VERSION ""

NS_ :

BS_:

BU_:

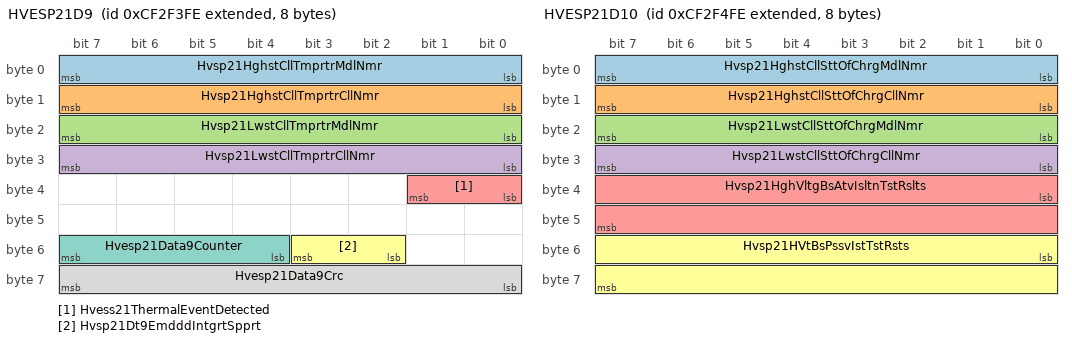
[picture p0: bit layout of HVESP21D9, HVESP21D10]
BO_ 2364732414 HVESP21D9: 8 Vector__XXX
 SG_ Hvsp21HghstCllTmprtrMdlNmr : 0|8@1+ (1,0) [0|250] "count" Vector__XXX
 SG_ Hvsp21HghstCllTmprtrCllNmr : 8|8@1+ (1,0) [0|250] "count" Vector__XXX
 SG_ Hvsp21LwstCllTmprtrMdlNmr : 16|8@1+ (1,0) [0|250] "count" Vector__XXX
 SG_ Hvsp21LwstCllTmprtrCllNmr : 24|8@1+ (1,0) [0|250] "count" Vector__XXX
 SG_ Hvess21ThermalEventDetected : 32|2@1+ (1,0) [0|3] "" Vector__XXX
 SG_ Hvsp21Dt9EmdddIntgrtSpprt : 50|2@1+ (1,0) [0|3] "" Vector__XXX
 SG_ Hvesp21Data9Counter : 52|4@1+ (1,0) [0|15] "" Vector__XXX
 SG_ Hvesp21Data9Crc : 56|8@1+ (1,0) [0|250] "count" Vector__XXX

BO_ 2364732670 HVESP21D10: 8 Vector__XXX
 SG_ Hvsp21HghstCllSttOfChrgMdlNmr : 0|8@1+ (1,0) [0|250] "count" Vector__XXX
 SG_ Hvsp21HghstCllSttOfChrgCllNmr : 8|8@1+ (1,0) [0|250] "count" Vector__XXX
 SG_ Hvsp21LwstCllSttOfChrgMdlNmr : 16|8@1+ (1,0) [0|250] "count" Vector__XXX
 SG_ Hvsp21LwstCllSttOfChrgCllNmr : 24|8@1+ (1,0) [0|250] "count" Vector__XXX
 SG_ Hvsp21HghVltgBsAtvIsltnTstRslts : 32|16@1+ (0.1,0) [0|6425.5] "OhmPerV" Vector__XXX
 SG_ Hvsp21HVtBsPssvIstTstRsts : 48|16@1+ (0.1,0) [0|6425.5] "OhmPerV" Vector__XXX

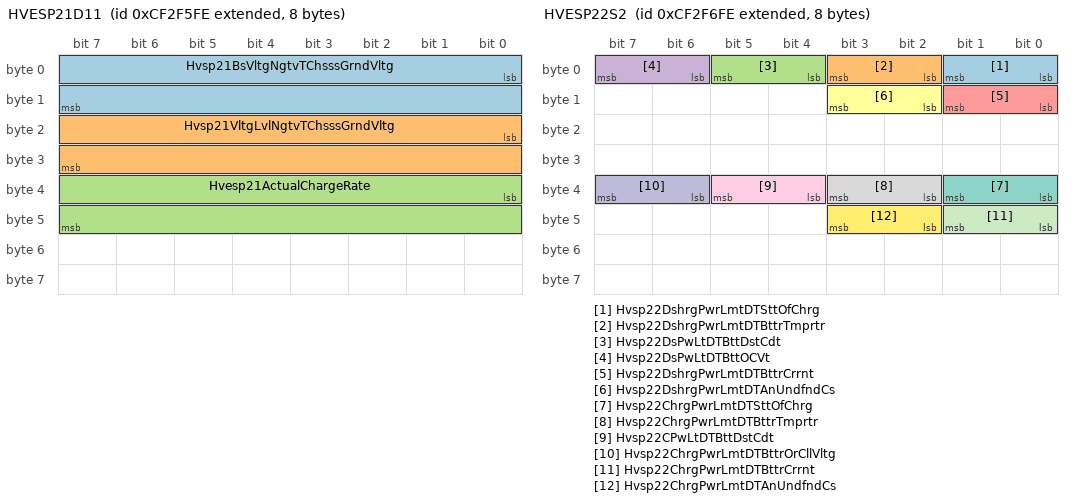
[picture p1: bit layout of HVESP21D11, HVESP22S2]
BO_ 2364732926 HVESP21D11: 8 Vector__XXX
 SG_ Hvsp21BsVltgNgtvTChsssGrndVltg : 0|16@1+ (0.05,0) [0|3212.75] "V" Vector__XXX
 SG_ Hvsp21VltgLvlNgtvTChsssGrndVltg : 16|16@1+ (0.05,0) [0|3212.75] "V" Vector__XXX
 SG_ Hvesp21ActualChargeRate : 32|16@1+ (0.05,0) [0|3212.75] "kW" Vector__XXX

BO_ 2364733182 HVESP22S2: 8 Vector__XXX
 SG_ Hvsp22DshrgPwrLmtDTSttOfChrg : 0|2@1+ (1,0) [0|3] "" Vector__XXX
 SG_ Hvsp22DshrgPwrLmtDTBttrTmprtr : 2|2@1+ (1,0) [0|3] "" Vector__XXX
 SG_ Hvsp22DsPwLtDTBttDstCdt : 4|2@1+ (1,0) [0|3] "" Vector__XXX
 SG_ Hvsp22DsPwLtDTBttOCVt : 6|2@1+ (1,0) [0|3] "" Vector__XXX
 SG_ Hvsp22DshrgPwrLmtDTBttrCrrnt : 8|2@1+ (1,0) [0|3] "" Vector__XXX
 SG_ Hvsp22DshrgPwrLmtDTAnUndfndCs : 10|2@1+ (1,0) [0|3] "" Vector__XXX
 SG_ Hvsp22ChrgPwrLmtDTSttOfChrg : 32|2@1+ (1,0) [0|3] "" Vector__XXX
 SG_ Hvsp22ChrgPwrLmtDTBttrTmprtr : 34|2@1+ (1,0) [0|3] "" Vector__XXX
 SG_ Hvsp22CPwLtDTBttDstCdt : 36|2@1+ (1,0) [0|3] "" Vector__XXX
 SG_ Hvsp22ChrgPwrLmtDTBttrOrCllVltg : 38|2@1+ (1,0) [0|3] "" Vector__XXX
 SG_ Hvsp22ChrgPwrLmtDTBttrCrrnt : 40|2@1+ (1,0) [0|3] "" Vector__XXX
 SG_ Hvsp22ChrgPwrLmtDTAnUndfndCs : 42|2@1+ (1,0) [0|3] "" Vector__XXX

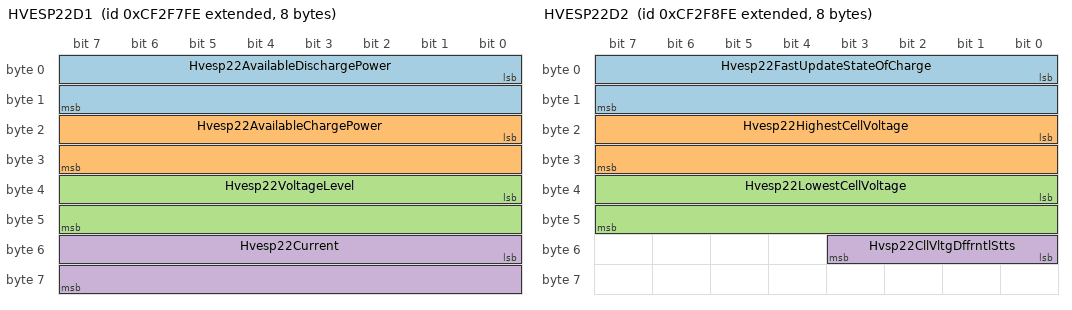
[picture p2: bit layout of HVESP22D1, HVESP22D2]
BO_ 2364733438 HVESP22D1: 8 Vector__XXX
 SG_ Hvesp22AvailableDischargePower : 0|16@1+ (0.05,0) [0|3212.75] "kW" Vector__XXX
 SG_ Hvesp22AvailableChargePower : 16|16@1+ (0.05,0) [0|3212.75] "kW" Vector__XXX
 SG_ Hvesp22VoltageLevel : 32|16@1+ (0.05,0) [0|3212.75] "V" Vector__XXX
 SG_ Hvesp22Current : 48|16@1+ (0.05,-1600) [-1600|1612.75] "A" Vector__XXX

BO_ 2364733694 HVESP22D2: 8 Vector__XXX
 SG_ Hvesp22FastUpdateStateOfCharge : 0|16@1+ (0.0015625,0) [0|100.3984375] "%" Vector__XXX
 SG_ Hvesp22HighestCellVoltage : 16|16@1+ (0.001,0) [0|64.255] "V" Vector__XXX
 SG_ Hvesp22LowestCellVoltage : 32|16@1+ (0.001,0) [0|64.255] "V" Vector__XXX
 SG_ Hvsp22CllVltgDffrntlStts : 48|4@1+ (1,0) [0|15] "" Vector__XXX

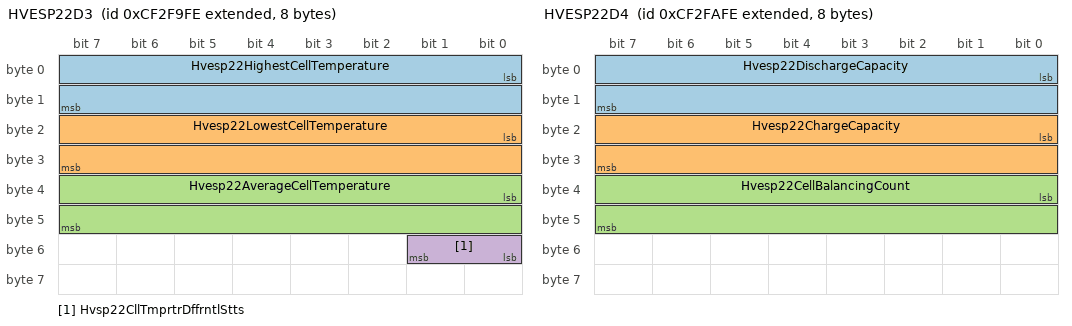
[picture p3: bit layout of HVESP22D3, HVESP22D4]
BO_ 2364733950 HVESP22D3: 8 Vector__XXX
 SG_ Hvesp22HighestCellTemperature : 0|16@1+ (0.03125,-273) [-273|1734.96875] "degC" Vector__XXX
 SG_ Hvesp22LowestCellTemperature : 16|16@1+ (0.03125,-273) [-273|1734.96875] "degC" Vector__XXX
 SG_ Hvesp22AverageCellTemperature : 32|16@1+ (0.03125,-273) [-273|1734.96875] "degC" Vector__XXX
 SG_ Hvsp22CllTmprtrDffrntlStts : 48|2@1+ (1,0) [0|3] "" Vector__XXX

BO_ 2364734206 HVESP22D4: 8 Vector__XXX
 SG_ Hvesp22DischargeCapacity : 0|16@1+ (0.01,0) [0|642.55] "Ah" Vector__XXX
 SG_ Hvesp22ChargeCapacity : 16|16@1+ (0.01,0) [0|642.55] "Ah" Vector__XXX
 SG_ Hvesp22CellBalancingCount : 32|16@1+ (1,0) [0|64255] "count" Vector__XXX

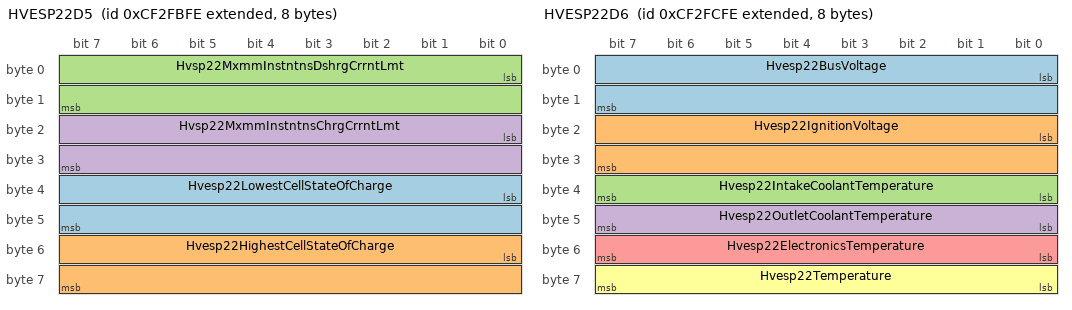
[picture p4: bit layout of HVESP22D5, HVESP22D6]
BO_ 2364734462 HVESP22D5: 8 Vector__XXX
 SG_ Hvesp22LowestCellStateOfCharge : 32|16@1+ (0.0015625,0) [0|100.3984375] "%" Vector__XXX
 SG_ Hvesp22HighestCellStateOfCharge : 48|16@1+ (0.0015625,0) [0|100.3984375] "%" Vector__XXX
 SG_ Hvsp22MxmmInstntnsDshrgCrrntLmt : 0|16@1+ (0.05,-1600) [-1600|0] "A" Vector__XXX
 SG_ Hvsp22MxmmInstntnsChrgCrrntLmt : 16|16@1+ (0.05,-1600) [0|1612.75] "A" Vector__XXX

BO_ 2364734718 HVESP22D6: 8 Vector__XXX
 SG_ Hvesp22BusVoltage : 0|16@1+ (0.05,0) [0|3212.75] "V" Vector__XXX
 SG_ Hvesp22IgnitionVoltage : 16|16@1+ (0.01,0) [0|642.55] "V" Vector__XXX
 SG_ Hvesp22IntakeCoolantTemperature : 32|8@1+ (1,-40) [-40|210] "degC" Vector__XXX
 SG_ Hvesp22OutletCoolantTemperature : 40|8@1+ (1,-40) [-40|210] "degC" Vector__XXX
 SG_ Hvesp22ElectronicsTemperature : 48|8@1+ (1,-40) [-40|210] "degC" Vector__XXX
 SG_ Hvesp22Temperature : 56|8@1+ (1,-40) [-40|210] "degC" Vector__XXX

BO_ 2364734974 HVESP22S1: 8 Vector__XXX
 SG_ Hvsp22HghVltgBsPstvCnttrStt : 0|2@1+ (1,0) [0|3] "" Vector__XXX
 SG_ Hvsp22HghVltgBsNgtvCnttrStt : 2|2@1+ (1,0) [0|3] "" Vector__XXX
 SG_ Hvsp22HghVltgBsDsnntFrwrnng : 4|4@1+ (1,0) [0|15] "" Vector__XXX
 SG_ Hvsp22HghVltgBsPrChrgRlStt : 8|2@1+ (1,0) [0|3] "" Vector__XXX
 SG_ Hvsp22CntrOfPkCnttrStt : 10|2@1+ (1,0) [0|3] "" Vector__XXX
 SG_ Hvsp22HghVltgBsAtvIsltnTstStts : 12|4@1+ (1,0) [0|15] "" Vector__XXX
 SG_ Hvsp22HghVltgBsPssvIsltnTstStts : 16|4@1+ (1,0) [0|15] "" Vector__XXX
 SG_ Hvesp22HvilStatus : 20|2@1+ (1,0) [0|3] "" Vector__XXX
 SG_ Hvesp22InertiaSwitchStatus : 22|2@1+ (1,0) [0|3] "" Vector__XXX
 SG_ Hvesp22StateOfChargeStatus : 24|4@1+ (1,0) [0|15] "" Vector__XXX
 SG_ Hvesp22CellBalanceStatus : 28|2@1+ (1,0) [0|3] "" Vector__XXX
 SG_ Hvesp22CellBalancingActive : 30|2@1+ (1,0) [0|3] "" Vector__XXX
 SG_ Hvesp22InternalChargerStatus : 32|2@1+ (1,0) [0|3] "" Vector__XXX
 SG_ Hvsp22HghVltgBsCnntnStts : 40|4@1+ (1,0) [0|15] "" Vector__XXX
 SG_ Hvesp22OperationalStatus : 44|4@1+ (1,0) [0|15] "" Vector__XXX
 SG_ Hvesp22Status1Counter : 52|4@1+ (1,0) [0|15] "" Vector__XXX
 SG_ Hvesp22Status1Crc : 56|8@1+ (1,0) [0|250] "count" Vector__XXX

BO_ 2364735230 HVESP22D7: 8 Vector__XXX
 SG_ Hvesp22DischargeEnergyCapacity : 0|24@1+ (0.001,0) [0|16449.535] "kWh" Vector__XXX
 SG_ Hvesp22ChargeEnergyCapacity : 24|24@1+ (0.001,0) [0|16449.535] "kWh" Vector__XXX
 SG_ Hvsp22MxmmChrgVltgLmt : 48|16@1+ (0.05,0) [0|3212.75] "V" Vector__XXX

BO_ 2364735486 HVESP22MS1: 8 Vector__XXX
 SG_ Hvesp22Module1OperationalStatus : 0|2@1+ (1,0) [0|3] "" Vector__XXX
 SG_ Hvesp22Module2OperationalStatus : 2|2@1+ (1,0) [0|3] "" Vector__XXX
 SG_ Hvesp22Module3OperationalStatus : 4|2@1+ (1,0) [0|3] "" Vector__XXX
 SG_ Hvesp22Module4OperationalStatus : 6|2@1+ (1,0) [0|3] "" Vector__XXX
 SG_ Hvesp22Module5OperationalStatus : 8|2@1+ (1,0) [0|3] "" Vector__XXX
 SG_ Hvesp22Module6OperationalStatus : 10|2@1+ (1,0) [0|3] "" Vector__XXX
 SG_ Hvesp22Module7OperationalStatus : 12|2@1+ (1,0) [0|3] "" Vector__XXX
 SG_ Hvesp22Module8OperationalStatus : 14|2@1+ (1,0) [0|3] "" Vector__XXX
 SG_ Hvesp22Module9OperationalStatus : 16|2@1+ (1,0) [0|3] "" Vector__XXX
 SG_ Hvsp22Mdl10OprtnlStts : 18|2@1+ (1,0) [0|3] "" Vector__XXX
 SG_ Hvsp22Mdl11OprtnlStts : 20|2@1+ (1,0) [0|3] "" Vector__XXX
 SG_ Hvsp22Mdl12OprtnlStts : 22|2@1+ (1,0) [0|3] "" Vector__XXX
 SG_ Hvsp22Mdl13OprtnlStts : 24|2@1+ (1,0) [0|3] "" Vector__XXX
 SG_ Hvsp22Mdl14OprtnlStts : 26|2@1+ (1,0) [0|3] "" Vector__XXX
 SG_ Hvsp22Mdl15OprtnlStts : 28|2@1+ (1,0) [0|3] "" Vector__XXX
 SG_ Hvsp22Mdl16OprtnlStts : 30|2@1+ (1,0) [0|3] "" Vector__XXX
 SG_ Hvsp22Mdl17OprtnlStts : 32|2@1+ (1,0) [0|3] "" Vector__XXX
 SG_ Hvsp22Mdl18OprtnlStts : 34|2@1+ (1,0) [0|3] "" Vector__XXX
 SG_ Hvsp22Mdl19OprtnlStts : 36|2@1+ (1,0) [0|3] "" Vector__XXX
 SG_ Hvsp22Mdl20OprtnlStts : 38|2@1+ (1,0) [0|3] "" Vector__XXX
 SG_ Hvsp22Mdl21OprtnlStts : 40|2@1+ (1,0) [0|3] "" Vector__XXX
 SG_ Hvsp22Mdl22OprtnlStts : 42|2@1+ (1,0) [0|3] "" Vector__XXX
 SG_ Hvsp22Mdl23OprtnlStts : 44|2@1+ (1,0) [0|3] "" Vector__XXX
 SG_ Hvsp22Mdl24OprtnlStts : 46|2@1+ (1,0) [0|3] "" Vector__XXX
 SG_ Hvsp22Mdl25OprtnlStts : 48|2@1+ (1,0) [0|3] "" Vector__XXX
 SG_ Hvsp22Mdl26OprtnlStts : 50|2@1+ (1,0) [0|3] "" Vector__XXX
 SG_ Hvsp22Mdl27OprtnlStts : 52|2@1+ (1,0) [0|3] "" Vector__XXX
 SG_ Hvsp22Mdl28OprtnlStts : 54|2@1+ (1,0) [0|3] "" Vector__XXX
 SG_ Hvsp22Mdl29OprtnlStts : 56|2@1+ (1,0) [0|3] "" Vector__XXX
 SG_ Hvsp22Mdl30OprtnlStts : 58|2@1+ (1,0) [0|3] "" Vector__XXX
 SG_ Hvsp22Mdl31OprtnlStts : 60|2@1+ (1,0) [0|3] "" Vector__XXX
 SG_ Hvsp22Mdl32OprtnlStts : 62|2@1+ (1,0) [0|3] "" Vector__XXX

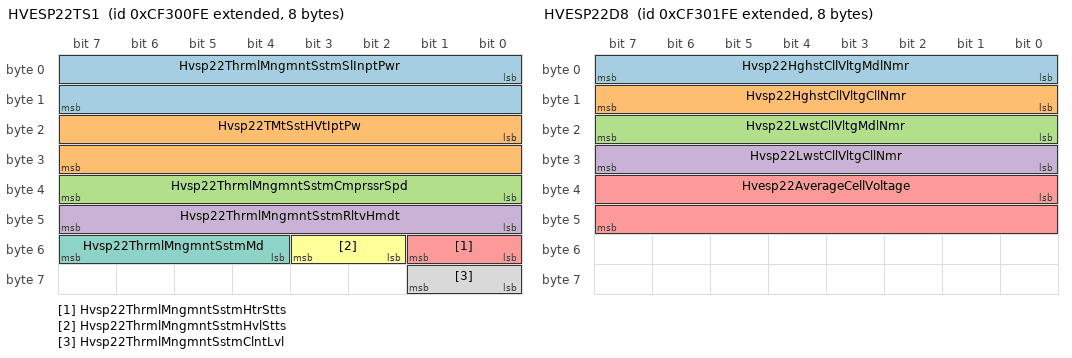
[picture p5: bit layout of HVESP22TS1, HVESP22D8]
BO_ 2364735742 HVESP22TS1: 8 Vector__XXX
 SG_ Hvsp22ThrmlMngmntSstmSlInptPwr : 0|16@1+ (0.5,0) [0|32127.5] "W" Vector__XXX
 SG_ Hvsp22TMtSstHVtIptPw : 16|16@1+ (0.5,0) [0|32127.5] "W" Vector__XXX
 SG_ Hvsp22ThrmlMngmntSstmCmprssrSpd : 32|8@1+ (32,0) [0|8000] "rpm" Vector__XXX
 SG_ Hvsp22ThrmlMngmntSstmRltvHmdt : 40|8@1+ (0.4,0) [0|100] "%" Vector__XXX
 SG_ Hvsp22ThrmlMngmntSstmHtrStts : 48|2@1+ (1,0) [0|3] "" Vector__XXX
 SG_ Hvsp22ThrmlMngmntSstmHvlStts : 50|2@1+ (1,0) [0|3] "" Vector__XXX
 SG_ Hvsp22ThrmlMngmntSstmMd : 52|4@1+ (1,0) [0|15] "" Vector__XXX
 SG_ Hvsp22ThrmlMngmntSstmClntLvl : 56|2@1+ (1,0) [0|3] "" Vector__XXX

BO_ 2364735998 HVESP22D8: 8 Vector__XXX
 SG_ Hvsp22HghstCllVltgMdlNmr : 0|8@1+ (1,0) [0|250] "count" Vector__XXX
 SG_ Hvsp22HghstCllVltgCllNmr : 8|8@1+ (1,0) [0|250] "count" Vector__XXX
 SG_ Hvsp22LwstCllVltgMdlNmr : 16|8@1+ (1,0) [0|250] "count" Vector__XXX
 SG_ Hvsp22LwstCllVltgCllNmr : 24|8@1+ (1,0) [0|250] "count" Vector__XXX
 SG_ Hvesp22AverageCellVoltage : 32|16@1+ (0.001,0) [0|64.255] "V" Vector__XXX

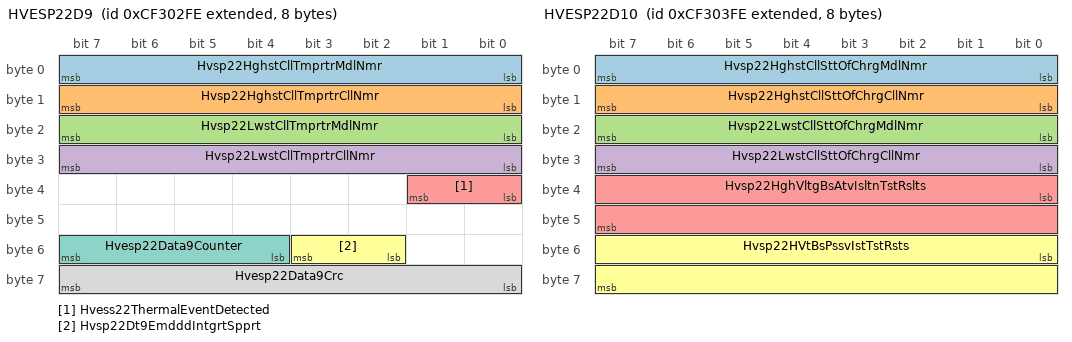
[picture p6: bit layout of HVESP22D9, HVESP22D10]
BO_ 2364736254 HVESP22D9: 8 Vector__XXX
 SG_ Hvsp22HghstCllTmprtrMdlNmr : 0|8@1+ (1,0) [0|250] "count" Vector__XXX
 SG_ Hvsp22HghstCllTmprtrCllNmr : 8|8@1+ (1,0) [0|250] "count" Vector__XXX
 SG_ Hvsp22LwstCllTmprtrMdlNmr : 16|8@1+ (1,0) [0|250] "count" Vector__XXX
 SG_ Hvsp22LwstCllTmprtrCllNmr : 24|8@1+ (1,0) [0|250] "count" Vector__XXX
 SG_ Hvess22ThermalEventDetected : 32|2@1+ (1,0) [0|3] "" Vector__XXX
 SG_ Hvsp22Dt9EmdddIntgrtSpprt : 50|2@1+ (1,0) [0|3] "" Vector__XXX
 SG_ Hvesp22Data9Counter : 52|4@1+ (1,0) [0|15] "" Vector__XXX
 SG_ Hvesp22Data9Crc : 56|8@1+ (1,0) [0|250] "count" Vector__XXX

BO_ 2364736510 HVESP22D10: 8 Vector__XXX
 SG_ Hvsp22HghstCllSttOfChrgMdlNmr : 0|8@1+ (1,0) [0|250] "count" Vector__XXX
 SG_ Hvsp22HghstCllSttOfChrgCllNmr : 8|8@1+ (1,0) [0|250] "count" Vector__XXX
 SG_ Hvsp22LwstCllSttOfChrgMdlNmr : 16|8@1+ (1,0) [0|250] "count" Vector__XXX
 SG_ Hvsp22LwstCllSttOfChrgCllNmr : 24|8@1+ (1,0) [0|250] "count" Vector__XXX
 SG_ Hvsp22HghVltgBsAtvIsltnTstRslts : 32|16@1+ (0.1,0) [0|6425.5] "OhmPerV" Vector__XXX
 SG_ Hvsp22HVtBsPssvIstTstRsts : 48|16@1+ (0.1,0) [0|6425.5] "OhmPerV" Vector__XXX

BO_ 2364736766 HVESP22D11: 8 Vector__XXX
 SG_ Hvsp22BsVltgNgtvTChsssGrndVltg : 0|16@1+ (0.05,0) [0|3212.75] "V" Vector__XXX
 SG_ Hvsp22VltgLvlNgtvTChsssGrndVltg : 16|16@1+ (0.05,0) [0|3212.75] "V" Vector__XXX
 SG_ Hvesp22ActualChargeRate : 32|16@1+ (0.05,0) [0|3212.75] "kW" Vector__XXX

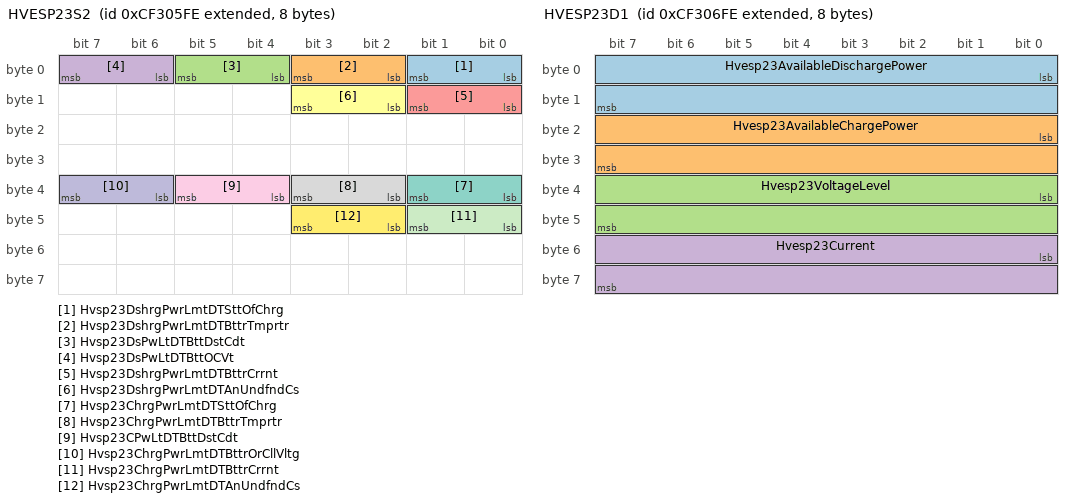
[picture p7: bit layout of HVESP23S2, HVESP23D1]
BO_ 2364737022 HVESP23S2: 8 Vector__XXX
 SG_ Hvsp23DshrgPwrLmtDTSttOfChrg : 0|2@1+ (1,0) [0|3] "" Vector__XXX
 SG_ Hvsp23DshrgPwrLmtDTBttrTmprtr : 2|2@1+ (1,0) [0|3] "" Vector__XXX
 SG_ Hvsp23DsPwLtDTBttDstCdt : 4|2@1+ (1,0) [0|3] "" Vector__XXX
 SG_ Hvsp23DsPwLtDTBttOCVt : 6|2@1+ (1,0) [0|3] "" Vector__XXX
 SG_ Hvsp23DshrgPwrLmtDTBttrCrrnt : 8|2@1+ (1,0) [0|3] "" Vector__XXX
 SG_ Hvsp23DshrgPwrLmtDTAnUndfndCs : 10|2@1+ (1,0) [0|3] "" Vector__XXX
 SG_ Hvsp23ChrgPwrLmtDTSttOfChrg : 32|2@1+ (1,0) [0|3] "" Vector__XXX
 SG_ Hvsp23ChrgPwrLmtDTBttrTmprtr : 34|2@1+ (1,0) [0|3] "" Vector__XXX
 SG_ Hvsp23CPwLtDTBttDstCdt : 36|2@1+ (1,0) [0|3] "" Vector__XXX
 SG_ Hvsp23ChrgPwrLmtDTBttrOrCllVltg : 38|2@1+ (1,0) [0|3] "" Vector__XXX
 SG_ Hvsp23ChrgPwrLmtDTBttrCrrnt : 40|2@1+ (1,0) [0|3] "" Vector__XXX
 SG_ Hvsp23ChrgPwrLmtDTAnUndfndCs : 42|2@1+ (1,0) [0|3] "" Vector__XXX

BO_ 2364737278 HVESP23D1: 8 Vector__XXX
 SG_ Hvesp23AvailableDischargePower : 0|16@1+ (0.05,0) [0|3212.75] "kW" Vector__XXX
 SG_ Hvesp23AvailableChargePower : 16|16@1+ (0.05,0) [0|3212.75] "kW" Vector__XXX
 SG_ Hvesp23VoltageLevel : 32|16@1+ (0.05,0) [0|3212.75] "V" Vector__XXX
 SG_ Hvesp23Current : 48|16@1+ (0.05,-1600) [-1600|1612.75] "A" Vector__XXX

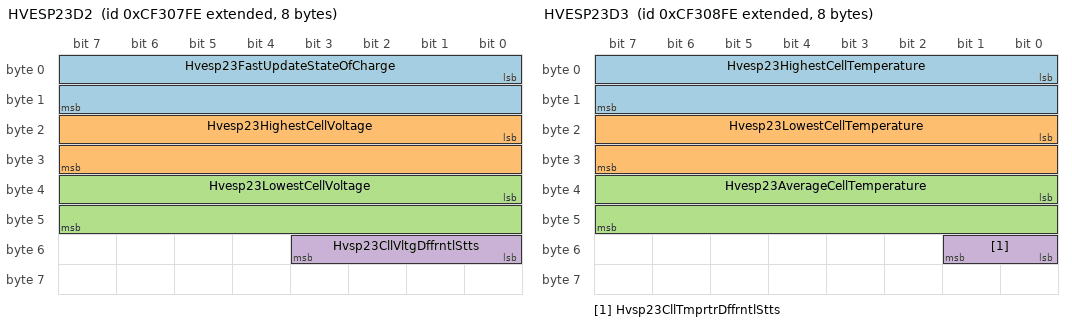
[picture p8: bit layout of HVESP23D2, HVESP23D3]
BO_ 2364737534 HVESP23D2: 8 Vector__XXX
 SG_ Hvesp23FastUpdateStateOfCharge : 0|16@1+ (0.0015625,0) [0|100.3984375] "%" Vector__XXX
 SG_ Hvesp23HighestCellVoltage : 16|16@1+ (0.001,0) [0|64.255] "V" Vector__XXX
 SG_ Hvesp23LowestCellVoltage : 32|16@1+ (0.001,0) [0|64.255] "V" Vector__XXX
 SG_ Hvsp23CllVltgDffrntlStts : 48|4@1+ (1,0) [0|15] "" Vector__XXX

BO_ 2364737790 HVESP23D3: 8 Vector__XXX
 SG_ Hvesp23HighestCellTemperature : 0|16@1+ (0.03125,-273) [-273|1734.96875] "degC" Vector__XXX
 SG_ Hvesp23LowestCellTemperature : 16|16@1+ (0.03125,-273) [-273|1734.96875] "degC" Vector__XXX
 SG_ Hvesp23AverageCellTemperature : 32|16@1+ (0.03125,-273) [-273|1734.96875] "degC" Vector__XXX
 SG_ Hvsp23CllTmprtrDffrntlStts : 48|2@1+ (1,0) [0|3] "" Vector__XXX

BO_ 2364738046 HVESP23D4: 8 Vector__XXX
 SG_ Hvesp23DischargeCapacity : 0|16@1+ (0.01,0) [0|642.55] "Ah" Vector__XXX
 SG_ Hvesp23ChargeCapacity : 16|16@1+ (0.01,0) [0|642.55] "Ah" Vector__XXX
 SG_ Hvesp23CellBalancingCount : 32|16@1+ (1,0) [0|64255] "count" Vector__XXX

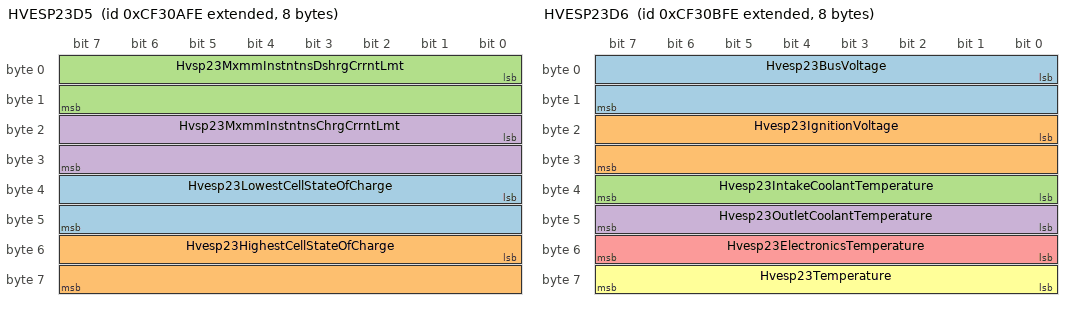
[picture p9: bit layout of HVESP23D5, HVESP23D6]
BO_ 2364738302 HVESP23D5: 8 Vector__XXX
 SG_ Hvesp23LowestCellStateOfCharge : 32|16@1+ (0.0015625,0) [0|100.3984375] "%" Vector__XXX
 SG_ Hvesp23HighestCellStateOfCharge : 48|16@1+ (0.0015625,0) [0|100.3984375] "%" Vector__XXX
 SG_ Hvsp23MxmmInstntnsDshrgCrrntLmt : 0|16@1+ (0.05,-1600) [-1600|0] "A" Vector__XXX
 SG_ Hvsp23MxmmInstntnsChrgCrrntLmt : 16|16@1+ (0.05,-1600) [0|1612.75] "A" Vector__XXX

BO_ 2364738558 HVESP23D6: 8 Vector__XXX
 SG_ Hvesp23BusVoltage : 0|16@1+ (0.05,0) [0|3212.75] "V" Vector__XXX
 SG_ Hvesp23IgnitionVoltage : 16|16@1+ (0.01,0) [0|642.55] "V" Vector__XXX
 SG_ Hvesp23IntakeCoolantTemperature : 32|8@1+ (1,-40) [-40|210] "degC" Vector__XXX
 SG_ Hvesp23OutletCoolantTemperature : 40|8@1+ (1,-40) [-40|210] "degC" Vector__XXX
 SG_ Hvesp23ElectronicsTemperature : 48|8@1+ (1,-40) [-40|210] "degC" Vector__XXX
 SG_ Hvesp23Temperature : 56|8@1+ (1,-40) [-40|210] "degC" Vector__XXX

BO_ 2364738814 HVESP23S1: 8 Vector__XXX
 SG_ Hvsp23HghVltgBsPstvCnttrStt : 0|2@1+ (1,0) [0|3] "" Vector__XXX
 SG_ Hvsp23HghVltgBsNgtvCnttrStt : 2|2@1+ (1,0) [0|3] "" Vector__XXX
 SG_ Hvsp23HghVltgBsDsnntFrwrnng : 4|4@1+ (1,0) [0|15] "" Vector__XXX
 SG_ Hvsp23HghVltgBsPrChrgRlStt : 8|2@1+ (1,0) [0|3] "" Vector__XXX
 SG_ Hvsp23CntrOfPkCnttrStt : 10|2@1+ (1,0) [0|3] "" Vector__XXX
 SG_ Hvsp23HghVltgBsAtvIsltnTstStts : 12|4@1+ (1,0) [0|15] "" Vector__XXX
 SG_ Hvsp23HghVltgBsPssvIsltnTstStts : 16|4@1+ (1,0) [0|15] "" Vector__XXX
 SG_ Hvesp23HvilStatus : 20|2@1+ (1,0) [0|3] "" Vector__XXX
 SG_ Hvesp23InertiaSwitchStatus : 22|2@1+ (1,0) [0|3] "" Vector__XXX
 SG_ Hvesp23StateOfChargeStatus : 24|4@1+ (1,0) [0|15] "" Vector__XXX
 SG_ Hvesp23CellBalanceStatus : 28|2@1+ (1,0) [0|3] "" Vector__XXX
 SG_ Hvesp23CellBalancingActive : 30|2@1+ (1,0) [0|3] "" Vector__XXX
 SG_ Hvesp23InternalChargerStatus : 32|2@1+ (1,0) [0|3] "" Vector__XXX
 SG_ Hvsp23HghVltgBsCnntnStts : 40|4@1+ (1,0) [0|15] "" Vector__XXX
 SG_ Hvesp23OperationalStatus : 44|4@1+ (1,0) [0|15] "" Vector__XXX
 SG_ Hvesp23Status1Counter : 52|4@1+ (1,0) [0|15] "" Vector__XXX
 SG_ Hvesp23Status1Crc : 56|8@1+ (1,0) [0|250] "count" Vector__XXX

BO_ 2364739070 HVESP23D7: 8 Vector__XXX
 SG_ Hvesp23DischargeEnergyCapacity : 0|24@1+ (0.001,0) [0|16449.535] "kWh" Vector__XXX
 SG_ Hvesp23ChargeEnergyCapacity : 24|24@1+ (0.001,0) [0|16449.535] "kWh" Vector__XXX
 SG_ Hvsp23MxmmChrgVltgLmt : 48|16@1+ (0.05,0) [0|3212.75] "V" Vector__XXX

BO_ 2364739326 HVESP23MS1: 8 Vector__XXX
 SG_ Hvesp23Module1OperationalStatus : 0|2@1+ (1,0) [0|3] "" Vector__XXX
 SG_ Hvesp23Module2OperationalStatus : 2|2@1+ (1,0) [0|3] "" Vector__XXX
 SG_ Hvesp23Module3OperationalStatus : 4|2@1+ (1,0) [0|3] "" Vector__XXX
 SG_ Hvesp23Module4OperationalStatus : 6|2@1+ (1,0) [0|3] "" Vector__XXX
 SG_ Hvesp23Module5OperationalStatus : 8|2@1+ (1,0) [0|3] "" Vector__XXX
 SG_ Hvesp23Module6OperationalStatus : 10|2@1+ (1,0) [0|3] "" Vector__XXX
 SG_ Hvesp23Module7OperationalStatus : 12|2@1+ (1,0) [0|3] "" Vector__XXX
 SG_ Hvesp23Module8OperationalStatus : 14|2@1+ (1,0) [0|3] "" Vector__XXX
 SG_ Hvesp23Module9OperationalStatus : 16|2@1+ (1,0) [0|3] "" Vector__XXX
 SG_ Hvsp23Mdl10OprtnlStts : 18|2@1+ (1,0) [0|3] "" Vector__XXX
 SG_ Hvsp23Mdl11OprtnlStts : 20|2@1+ (1,0) [0|3] "" Vector__XXX
 SG_ Hvsp23Mdl12OprtnlStts : 22|2@1+ (1,0) [0|3] "" Vector__XXX
 SG_ Hvsp23Mdl13OprtnlStts : 24|2@1+ (1,0) [0|3] "" Vector__XXX
 SG_ Hvsp23Mdl14OprtnlStts : 26|2@1+ (1,0) [0|3] "" Vector__XXX
 SG_ Hvsp23Mdl15OprtnlStts : 28|2@1+ (1,0) [0|3] "" Vector__XXX
 SG_ Hvsp23Mdl16OprtnlStts : 30|2@1+ (1,0) [0|3] "" Vector__XXX
 SG_ Hvsp23Mdl17OprtnlStts : 32|2@1+ (1,0) [0|3] "" Vector__XXX
 SG_ Hvsp23Mdl18OprtnlStts : 34|2@1+ (1,0) [0|3] "" Vector__XXX
 SG_ Hvsp23Mdl19OprtnlStts : 36|2@1+ (1,0) [0|3] "" Vector__XXX
 SG_ Hvsp23Mdl20OprtnlStts : 38|2@1+ (1,0) [0|3] "" Vector__XXX
 SG_ Hvsp23Mdl21OprtnlStts : 40|2@1+ (1,0) [0|3] "" Vector__XXX
 SG_ Hvsp23Mdl22OprtnlStts : 42|2@1+ (1,0) [0|3] "" Vector__XXX
 SG_ Hvsp23Mdl23OprtnlStts : 44|2@1+ (1,0) [0|3] "" Vector__XXX
 SG_ Hvsp23Mdl24OprtnlStts : 46|2@1+ (1,0) [0|3] "" Vector__XXX
 SG_ Hvsp23Mdl25OprtnlStts : 48|2@1+ (1,0) [0|3] "" Vector__XXX
 SG_ Hvsp23Mdl26OprtnlStts : 50|2@1+ (1,0) [0|3] "" Vector__XXX
 SG_ Hvsp23Mdl27OprtnlStts : 52|2@1+ (1,0) [0|3] "" Vector__XXX
 SG_ Hvsp23Mdl28OprtnlStts : 54|2@1+ (1,0) [0|3] "" Vector__XXX
 SG_ Hvsp23Mdl29OprtnlStts : 56|2@1+ (1,0) [0|3] "" Vector__XXX
 SG_ Hvsp23Mdl30OprtnlStts : 58|2@1+ (1,0) [0|3] "" Vector__XXX
 SG_ Hvsp23Mdl31OprtnlStts : 60|2@1+ (1,0) [0|3] "" Vector__XXX
 SG_ Hvsp23Mdl32OprtnlStts : 62|2@1+ (1,0) [0|3] "" Vector__XXX

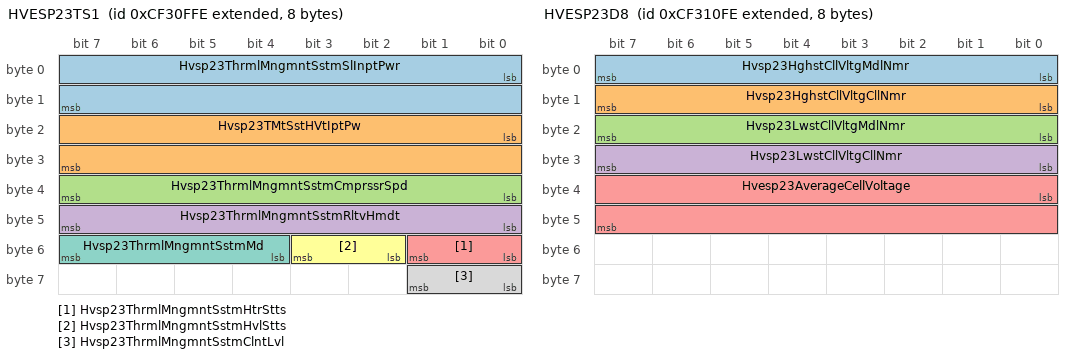
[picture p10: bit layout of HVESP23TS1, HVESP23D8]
BO_ 2364739582 HVESP23TS1: 8 Vector__XXX
 SG_ Hvsp23ThrmlMngmntSstmSlInptPwr : 0|16@1+ (0.5,0) [0|32127.5] "W" Vector__XXX
 SG_ Hvsp23TMtSstHVtIptPw : 16|16@1+ (0.5,0) [0|32127.5] "W" Vector__XXX
 SG_ Hvsp23ThrmlMngmntSstmCmprssrSpd : 32|8@1+ (32,0) [0|8000] "rpm" Vector__XXX
 SG_ Hvsp23ThrmlMngmntSstmRltvHmdt : 40|8@1+ (0.4,0) [0|100] "%" Vector__XXX
 SG_ Hvsp23ThrmlMngmntSstmHtrStts : 48|2@1+ (1,0) [0|3] "" Vector__XXX
 SG_ Hvsp23ThrmlMngmntSstmHvlStts : 50|2@1+ (1,0) [0|3] "" Vector__XXX
 SG_ Hvsp23ThrmlMngmntSstmMd : 52|4@1+ (1,0) [0|15] "" Vector__XXX
 SG_ Hvsp23ThrmlMngmntSstmClntLvl : 56|2@1+ (1,0) [0|3] "" Vector__XXX

BO_ 2364739838 HVESP23D8: 8 Vector__XXX
 SG_ Hvsp23HghstCllVltgMdlNmr : 0|8@1+ (1,0) [0|250] "count" Vector__XXX
 SG_ Hvsp23HghstCllVltgCllNmr : 8|8@1+ (1,0) [0|250] "count" Vector__XXX
 SG_ Hvsp23LwstCllVltgMdlNmr : 16|8@1+ (1,0) [0|250] "count" Vector__XXX
 SG_ Hvsp23LwstCllVltgCllNmr : 24|8@1+ (1,0) [0|250] "count" Vector__XXX
 SG_ Hvesp23AverageCellVoltage : 32|16@1+ (0.001,0) [0|64.255] "V" Vector__XXX

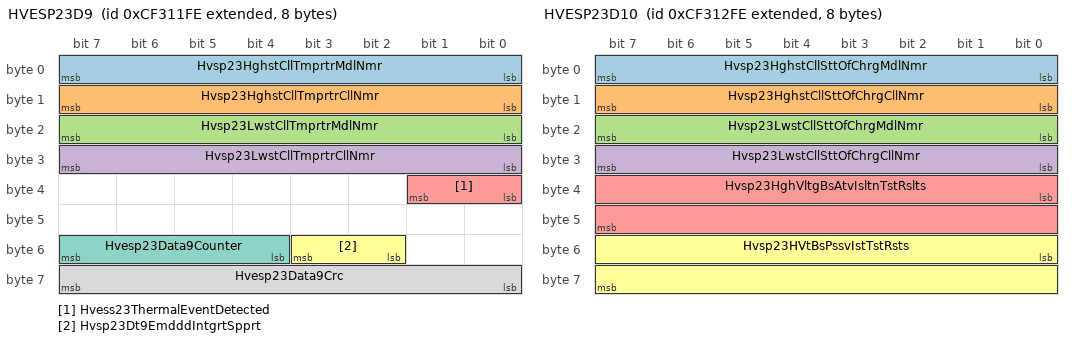
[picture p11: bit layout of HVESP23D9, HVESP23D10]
BO_ 2364740094 HVESP23D9: 8 Vector__XXX
 SG_ Hvsp23HghstCllTmprtrMdlNmr : 0|8@1+ (1,0) [0|250] "count" Vector__XXX
 SG_ Hvsp23HghstCllTmprtrCllNmr : 8|8@1+ (1,0) [0|250] "count" Vector__XXX
 SG_ Hvsp23LwstCllTmprtrMdlNmr : 16|8@1+ (1,0) [0|250] "count" Vector__XXX
 SG_ Hvsp23LwstCllTmprtrCllNmr : 24|8@1+ (1,0) [0|250] "count" Vector__XXX
 SG_ Hvess23ThermalEventDetected : 32|2@1+ (1,0) [0|3] "" Vector__XXX
 SG_ Hvsp23Dt9EmdddIntgrtSpprt : 50|2@1+ (1,0) [0|3] "" Vector__XXX
 SG_ Hvesp23Data9Counter : 52|4@1+ (1,0) [0|15] "" Vector__XXX
 SG_ Hvesp23Data9Crc : 56|8@1+ (1,0) [0|250] "count" Vector__XXX

BO_ 2364740350 HVESP23D10: 8 Vector__XXX
 SG_ Hvsp23HghstCllSttOfChrgMdlNmr : 0|8@1+ (1,0) [0|250] "count" Vector__XXX
 SG_ Hvsp23HghstCllSttOfChrgCllNmr : 8|8@1+ (1,0) [0|250] "count" Vector__XXX
 SG_ Hvsp23LwstCllSttOfChrgMdlNmr : 16|8@1+ (1,0) [0|250] "count" Vector__XXX
 SG_ Hvsp23LwstCllSttOfChrgCllNmr : 24|8@1+ (1,0) [0|250] "count" Vector__XXX
 SG_ Hvsp23HghVltgBsAtvIsltnTstRslts : 32|16@1+ (0.1,0) [0|6425.5] "OhmPerV" Vector__XXX
 SG_ Hvsp23HVtBsPssvIstTstRsts : 48|16@1+ (0.1,0) [0|6425.5] "OhmPerV" Vector__XXX

BO_ 2364740606 HVESP23D11: 8 Vector__XXX
 SG_ Hvsp23BsVltgNgtvTChsssGrndVltg : 0|16@1+ (0.05,0) [0|3212.75] "V" Vector__XXX
 SG_ Hvsp23VltgLvlNgtvTChsssGrndVltg : 16|16@1+ (0.05,0) [0|3212.75] "V" Vector__XXX
 SG_ Hvesp23ActualChargeRate : 32|16@1+ (0.05,0) [0|3212.75] "kW" Vector__XXX

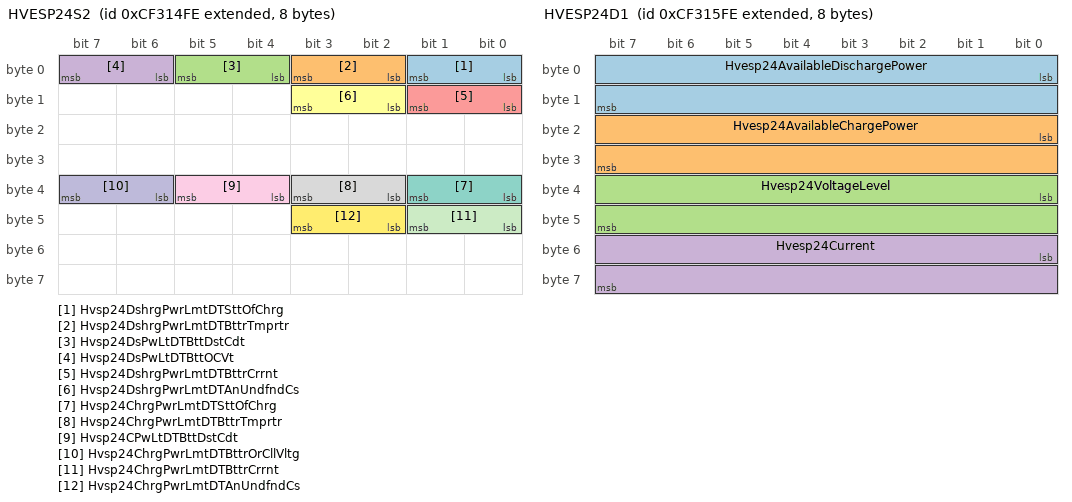
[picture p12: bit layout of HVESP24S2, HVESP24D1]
BO_ 2364740862 HVESP24S2: 8 Vector__XXX
 SG_ Hvsp24DshrgPwrLmtDTSttOfChrg : 0|2@1+ (1,0) [0|3] "" Vector__XXX
 SG_ Hvsp24DshrgPwrLmtDTBttrTmprtr : 2|2@1+ (1,0) [0|3] "" Vector__XXX
 SG_ Hvsp24DsPwLtDTBttDstCdt : 4|2@1+ (1,0) [0|3] "" Vector__XXX
 SG_ Hvsp24DsPwLtDTBttOCVt : 6|2@1+ (1,0) [0|3] "" Vector__XXX
 SG_ Hvsp24DshrgPwrLmtDTBttrCrrnt : 8|2@1+ (1,0) [0|3] "" Vector__XXX
 SG_ Hvsp24DshrgPwrLmtDTAnUndfndCs : 10|2@1+ (1,0) [0|3] "" Vector__XXX
 SG_ Hvsp24ChrgPwrLmtDTSttOfChrg : 32|2@1+ (1,0) [0|3] "" Vector__XXX
 SG_ Hvsp24ChrgPwrLmtDTBttrTmprtr : 34|2@1+ (1,0) [0|3] "" Vector__XXX
 SG_ Hvsp24CPwLtDTBttDstCdt : 36|2@1+ (1,0) [0|3] "" Vector__XXX
 SG_ Hvsp24ChrgPwrLmtDTBttrOrCllVltg : 38|2@1+ (1,0) [0|3] "" Vector__XXX
 SG_ Hvsp24ChrgPwrLmtDTBttrCrrnt : 40|2@1+ (1,0) [0|3] "" Vector__XXX
 SG_ Hvsp24ChrgPwrLmtDTAnUndfndCs : 42|2@1+ (1,0) [0|3] "" Vector__XXX

BO_ 2364741118 HVESP24D1: 8 Vector__XXX
 SG_ Hvesp24AvailableDischargePower : 0|16@1+ (0.05,0) [0|3212.75] "kW" Vector__XXX
 SG_ Hvesp24AvailableChargePower : 16|16@1+ (0.05,0) [0|3212.75] "kW" Vector__XXX
 SG_ Hvesp24VoltageLevel : 32|16@1+ (0.05,0) [0|3212.75] "V" Vector__XXX
 SG_ Hvesp24Current : 48|16@1+ (0.05,-1600) [-1600|1612.75] "A" Vector__XXX

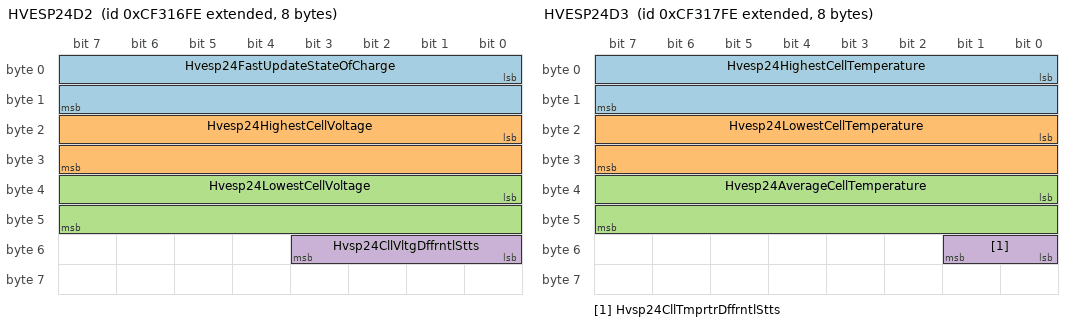
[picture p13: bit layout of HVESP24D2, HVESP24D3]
BO_ 2364741374 HVESP24D2: 8 Vector__XXX
 SG_ Hvesp24FastUpdateStateOfCharge : 0|16@1+ (0.0015625,0) [0|100.3984375] "%" Vector__XXX
 SG_ Hvesp24HighestCellVoltage : 16|16@1+ (0.001,0) [0|64.255] "V" Vector__XXX
 SG_ Hvesp24LowestCellVoltage : 32|16@1+ (0.001,0) [0|64.255] "V" Vector__XXX
 SG_ Hvsp24CllVltgDffrntlStts : 48|4@1+ (1,0) [0|15] "" Vector__XXX

BO_ 2364741630 HVESP24D3: 8 Vector__XXX
 SG_ Hvesp24HighestCellTemperature : 0|16@1+ (0.03125,-273) [-273|1734.96875] "degC" Vector__XXX
 SG_ Hvesp24LowestCellTemperature : 16|16@1+ (0.03125,-273) [-273|1734.96875] "degC" Vector__XXX
 SG_ Hvesp24AverageCellTemperature : 32|16@1+ (0.03125,-273) [-273|1734.96875] "degC" Vector__XXX
 SG_ Hvsp24CllTmprtrDffrntlStts : 48|2@1+ (1,0) [0|3] "" Vector__XXX

BO_ 2364741886 HVESP24D4: 8 Vector__XXX
 SG_ Hvesp24DischargeCapacity : 0|16@1+ (0.01,0) [0|642.55] "Ah" Vector__XXX
 SG_ Hvesp24ChargeCapacity : 16|16@1+ (0.01,0) [0|642.55] "Ah" Vector__XXX
 SG_ Hvesp24CellBalancingCount : 32|16@1+ (1,0) [0|64255] "count" Vector__XXX

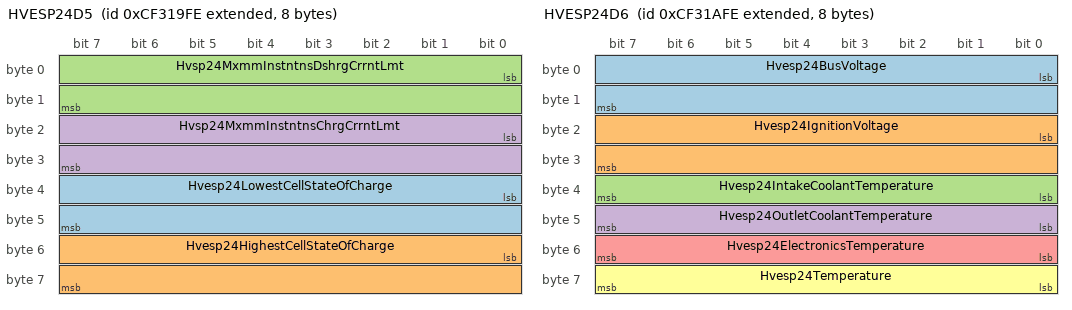
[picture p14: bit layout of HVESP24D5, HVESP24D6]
BO_ 2364742142 HVESP24D5: 8 Vector__XXX
 SG_ Hvesp24LowestCellStateOfCharge : 32|16@1+ (0.0015625,0) [0|100.3984375] "%" Vector__XXX
 SG_ Hvesp24HighestCellStateOfCharge : 48|16@1+ (0.0015625,0) [0|100.3984375] "%" Vector__XXX
 SG_ Hvsp24MxmmInstntnsDshrgCrrntLmt : 0|16@1+ (0.05,-1600) [-1600|0] "A" Vector__XXX
 SG_ Hvsp24MxmmInstntnsChrgCrrntLmt : 16|16@1+ (0.05,-1600) [0|1612.75] "A" Vector__XXX

BO_ 2364742398 HVESP24D6: 8 Vector__XXX
 SG_ Hvesp24BusVoltage : 0|16@1+ (0.05,0) [0|3212.75] "V" Vector__XXX
 SG_ Hvesp24IgnitionVoltage : 16|16@1+ (0.01,0) [0|642.55] "V" Vector__XXX
 SG_ Hvesp24IntakeCoolantTemperature : 32|8@1+ (1,-40) [-40|210] "degC" Vector__XXX
 SG_ Hvesp24OutletCoolantTemperature : 40|8@1+ (1,-40) [-40|210] "degC" Vector__XXX
 SG_ Hvesp24ElectronicsTemperature : 48|8@1+ (1,-40) [-40|210] "degC" Vector__XXX
 SG_ Hvesp24Temperature : 56|8@1+ (1,-40) [-40|210] "degC" Vector__XXX

BO_ 2364742654 HVESP24S1: 8 Vector__XXX
 SG_ Hvsp24HghVltgBsPstvCnttrStt : 0|2@1+ (1,0) [0|3] "" Vector__XXX
 SG_ Hvsp24HghVltgBsNgtvCnttrStt : 2|2@1+ (1,0) [0|3] "" Vector__XXX
 SG_ Hvsp24HghVltgBsDsnntFrwrnng : 4|4@1+ (1,0) [0|15] "" Vector__XXX
 SG_ Hvsp24HghVltgBsPrChrgRlStt : 8|2@1+ (1,0) [0|3] "" Vector__XXX
 SG_ Hvsp24CntrOfPkCnttrStt : 10|2@1+ (1,0) [0|3] "" Vector__XXX
 SG_ Hvsp24HghVltgBsAtvIsltnTstStts : 12|4@1+ (1,0) [0|15] "" Vector__XXX
 SG_ Hvsp24HghVltgBsPssvIsltnTstStts : 16|4@1+ (1,0) [0|15] "" Vector__XXX
 SG_ Hvesp24HvilStatus : 20|2@1+ (1,0) [0|3] "" Vector__XXX
 SG_ Hvesp24InertiaSwitchStatus : 22|2@1+ (1,0) [0|3] "" Vector__XXX
 SG_ Hvesp24StateOfChargeStatus : 24|4@1+ (1,0) [0|15] "" Vector__XXX
 SG_ Hvesp24CellBalanceStatus : 28|2@1+ (1,0) [0|3] "" Vector__XXX
 SG_ Hvesp24CellBalancingActive : 30|2@1+ (1,0) [0|3] "" Vector__XXX
 SG_ Hvesp24InternalChargerStatus : 32|2@1+ (1,0) [0|3] "" Vector__XXX
 SG_ Hvsp24HghVltgBsCnntnStts : 40|4@1+ (1,0) [0|15] "" Vector__XXX
 SG_ Hvesp24OperationalStatus : 44|4@1+ (1,0) [0|15] "" Vector__XXX
 SG_ Hvesp24Status1Counter : 52|4@1+ (1,0) [0|15] "" Vector__XXX
 SG_ Hvesp24Status1Crc : 56|8@1+ (1,0) [0|250] "count" Vector__XXX

BO_ 2364742910 HVESP24D7: 8 Vector__XXX
 SG_ Hvesp24DischargeEnergyCapacity : 0|24@1+ (0.001,0) [0|16449.535] "kWh" Vector__XXX
 SG_ Hvesp24ChargeEnergyCapacity : 24|24@1+ (0.001,0) [0|16449.535] "kWh" Vector__XXX
 SG_ Hvsp24MxmmChrgVltgLmt : 48|16@1+ (0.05,0) [0|3212.75] "V" Vector__XXX

BO_ 2364743166 HVESP24MS1: 8 Vector__XXX
 SG_ Hvesp24Module1OperationalStatus : 0|2@1+ (1,0) [0|3] "" Vector__XXX
 SG_ Hvesp24Module2OperationalStatus : 2|2@1+ (1,0) [0|3] "" Vector__XXX
 SG_ Hvesp24Module3OperationalStatus : 4|2@1+ (1,0) [0|3] "" Vector__XXX
 SG_ Hvesp24Module4OperationalStatus : 6|2@1+ (1,0) [0|3] "" Vector__XXX
 SG_ Hvesp24Module5OperationalStatus : 8|2@1+ (1,0) [0|3] "" Vector__XXX
 SG_ Hvesp24Module6OperationalStatus : 10|2@1+ (1,0) [0|3] "" Vector__XXX
 SG_ Hvesp24Module7OperationalStatus : 12|2@1+ (1,0) [0|3] "" Vector__XXX
 SG_ Hvesp24Module8OperationalStatus : 14|2@1+ (1,0) [0|3] "" Vector__XXX
 SG_ Hvesp24Module9OperationalStatus : 16|2@1+ (1,0) [0|3] "" Vector__XXX
 SG_ Hvsp24Mdl10OprtnlStts : 18|2@1+ (1,0) [0|3] "" Vector__XXX
 SG_ Hvsp24Mdl11OprtnlStts : 20|2@1+ (1,0) [0|3] "" Vector__XXX
 SG_ Hvsp24Mdl12OprtnlStts : 22|2@1+ (1,0) [0|3] "" Vector__XXX
 SG_ Hvsp24Mdl13OprtnlStts : 24|2@1+ (1,0) [0|3] "" Vector__XXX
 SG_ Hvsp24Mdl14OprtnlStts : 26|2@1+ (1,0) [0|3] "" Vector__XXX
 SG_ Hvsp24Mdl15OprtnlStts : 28|2@1+ (1,0) [0|3] "" Vector__XXX
 SG_ Hvsp24Mdl16OprtnlStts : 30|2@1+ (1,0) [0|3] "" Vector__XXX
 SG_ Hvsp24Mdl17OprtnlStts : 32|2@1+ (1,0) [0|3] "" Vector__XXX
 SG_ Hvsp24Mdl18OprtnlStts : 34|2@1+ (1,0) [0|3] "" Vector__XXX
 SG_ Hvsp24Mdl19OprtnlStts : 36|2@1+ (1,0) [0|3] "" Vector__XXX
 SG_ Hvsp24Mdl20OprtnlStts : 38|2@1+ (1,0) [0|3] "" Vector__XXX
 SG_ Hvsp24Mdl21OprtnlStts : 40|2@1+ (1,0) [0|3] "" Vector__XXX
 SG_ Hvsp24Mdl22OprtnlStts : 42|2@1+ (1,0) [0|3] "" Vector__XXX
 SG_ Hvsp24Mdl23OprtnlStts : 44|2@1+ (1,0) [0|3] "" Vector__XXX
 SG_ Hvsp24Mdl24OprtnlStts : 46|2@1+ (1,0) [0|3] "" Vector__XXX
 SG_ Hvsp24Mdl25OprtnlStts : 48|2@1+ (1,0) [0|3] "" Vector__XXX
 SG_ Hvsp24Mdl26OprtnlStts : 50|2@1+ (1,0) [0|3] "" Vector__XXX
 SG_ Hvsp24Mdl27OprtnlStts : 52|2@1+ (1,0) [0|3] "" Vector__XXX
 SG_ Hvsp24Mdl28OprtnlStts : 54|2@1+ (1,0) [0|3] "" Vector__XXX
 SG_ Hvsp24Mdl29OprtnlStts : 56|2@1+ (1,0) [0|3] "" Vector__XXX
 SG_ Hvsp24Mdl30OprtnlStts : 58|2@1+ (1,0) [0|3] "" Vector__XXX
 SG_ Hvsp24Mdl31OprtnlStts : 60|2@1+ (1,0) [0|3] "" Vector__XXX
 SG_ Hvsp24Mdl32OprtnlStts : 62|2@1+ (1,0) [0|3] "" Vector__XXX

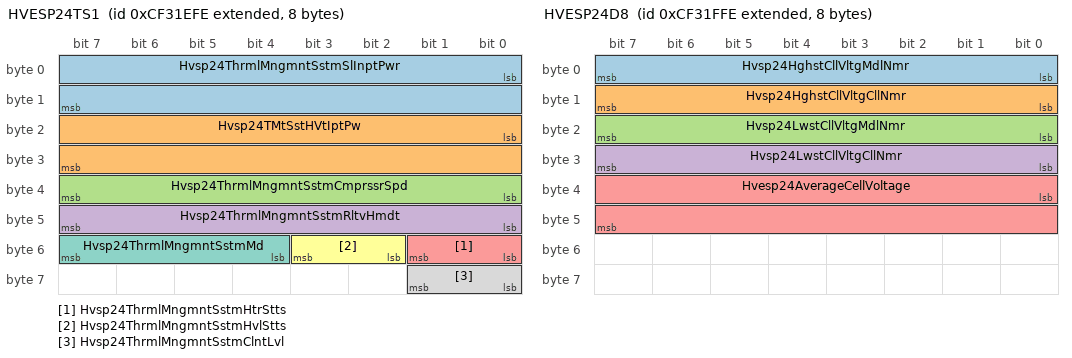
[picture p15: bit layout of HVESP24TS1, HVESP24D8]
BO_ 2364743422 HVESP24TS1: 8 Vector__XXX
 SG_ Hvsp24ThrmlMngmntSstmSlInptPwr : 0|16@1+ (0.5,0) [0|32127.5] "W" Vector__XXX
 SG_ Hvsp24TMtSstHVtIptPw : 16|16@1+ (0.5,0) [0|32127.5] "W" Vector__XXX
 SG_ Hvsp24ThrmlMngmntSstmCmprssrSpd : 32|8@1+ (32,0) [0|8000] "rpm" Vector__XXX
 SG_ Hvsp24ThrmlMngmntSstmRltvHmdt : 40|8@1+ (0.4,0) [0|100] "%" Vector__XXX
 SG_ Hvsp24ThrmlMngmntSstmHtrStts : 48|2@1+ (1,0) [0|3] "" Vector__XXX
 SG_ Hvsp24ThrmlMngmntSstmHvlStts : 50|2@1+ (1,0) [0|3] "" Vector__XXX
 SG_ Hvsp24ThrmlMngmntSstmMd : 52|4@1+ (1,0) [0|15] "" Vector__XXX
 SG_ Hvsp24ThrmlMngmntSstmClntLvl : 56|2@1+ (1,0) [0|3] "" Vector__XXX

BO_ 2364743678 HVESP24D8: 8 Vector__XXX
 SG_ Hvsp24HghstCllVltgMdlNmr : 0|8@1+ (1,0) [0|250] "count" Vector__XXX
 SG_ Hvsp24HghstCllVltgCllNmr : 8|8@1+ (1,0) [0|250] "count" Vector__XXX
 SG_ Hvsp24LwstCllVltgMdlNmr : 16|8@1+ (1,0) [0|250] "count" Vector__XXX
 SG_ Hvsp24LwstCllVltgCllNmr : 24|8@1+ (1,0) [0|250] "count" Vector__XXX
 SG_ Hvesp24AverageCellVoltage : 32|16@1+ (0.001,0) [0|64.255] "V" Vector__XXX

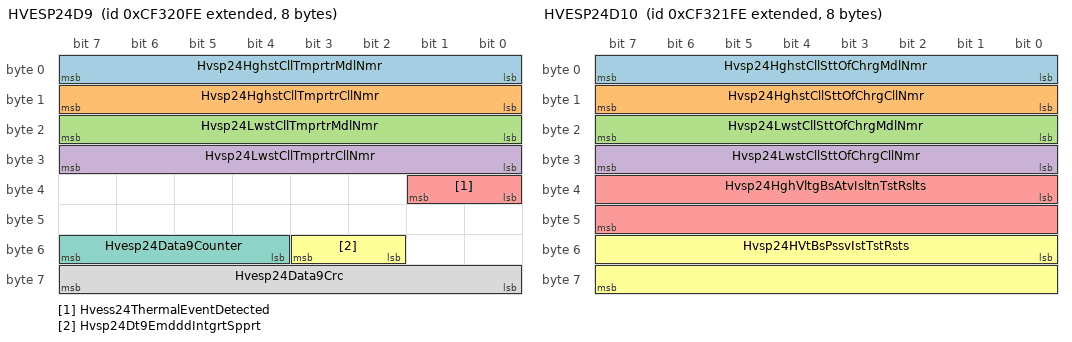
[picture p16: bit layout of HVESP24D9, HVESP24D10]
BO_ 2364743934 HVESP24D9: 8 Vector__XXX
 SG_ Hvsp24HghstCllTmprtrMdlNmr : 0|8@1+ (1,0) [0|250] "count" Vector__XXX
 SG_ Hvsp24HghstCllTmprtrCllNmr : 8|8@1+ (1,0) [0|250] "count" Vector__XXX
 SG_ Hvsp24LwstCllTmprtrMdlNmr : 16|8@1+ (1,0) [0|250] "count" Vector__XXX
 SG_ Hvsp24LwstCllTmprtrCllNmr : 24|8@1+ (1,0) [0|250] "count" Vector__XXX
 SG_ Hvess24ThermalEventDetected : 32|2@1+ (1,0) [0|3] "" Vector__XXX
 SG_ Hvsp24Dt9EmdddIntgrtSpprt : 50|2@1+ (1,0) [0|3] "" Vector__XXX
 SG_ Hvesp24Data9Counter : 52|4@1+ (1,0) [0|15] "" Vector__XXX
 SG_ Hvesp24Data9Crc : 56|8@1+ (1,0) [0|250] "count" Vector__XXX

BO_ 2364744190 HVESP24D10: 8 Vector__XXX
 SG_ Hvsp24HghstCllSttOfChrgMdlNmr : 0|8@1+ (1,0) [0|250] "count" Vector__XXX
 SG_ Hvsp24HghstCllSttOfChrgCllNmr : 8|8@1+ (1,0) [0|250] "count" Vector__XXX
 SG_ Hvsp24LwstCllSttOfChrgMdlNmr : 16|8@1+ (1,0) [0|250] "count" Vector__XXX
 SG_ Hvsp24LwstCllSttOfChrgCllNmr : 24|8@1+ (1,0) [0|250] "count" Vector__XXX
 SG_ Hvsp24HghVltgBsAtvIsltnTstRslts : 32|16@1+ (0.1,0) [0|6425.5] "OhmPerV" Vector__XXX
 SG_ Hvsp24HVtBsPssvIstTstRsts : 48|16@1+ (0.1,0) [0|6425.5] "OhmPerV" Vector__XXX

BO_ 2364744446 HVESP24D11: 8 Vector__XXX
 SG_ Hvsp24BsVltgNgtvTChsssGrndVltg : 0|16@1+ (0.05,0) [0|3212.75] "V" Vector__XXX
 SG_ Hvsp24VltgLvlNgtvTChsssGrndVltg : 16|16@1+ (0.05,0) [0|3212.75] "V" Vector__XXX
 SG_ Hvesp24ActualChargeRate : 32|16@1+ (0.05,0) [0|3212.75] "kW" Vector__XXX

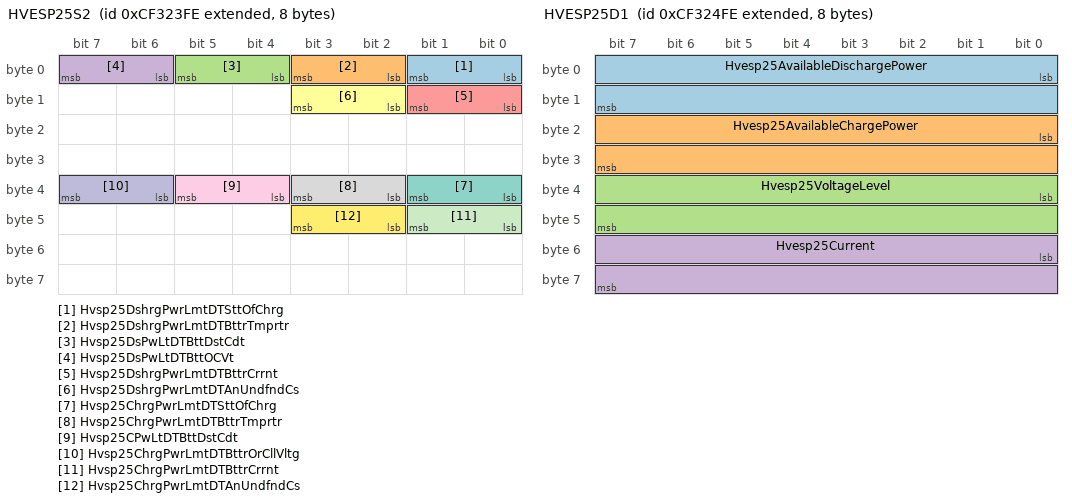
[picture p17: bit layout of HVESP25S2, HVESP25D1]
BO_ 2364744702 HVESP25S2: 8 Vector__XXX
 SG_ Hvsp25DshrgPwrLmtDTSttOfChrg : 0|2@1+ (1,0) [0|3] "" Vector__XXX
 SG_ Hvsp25DshrgPwrLmtDTBttrTmprtr : 2|2@1+ (1,0) [0|3] "" Vector__XXX
 SG_ Hvsp25DsPwLtDTBttDstCdt : 4|2@1+ (1,0) [0|3] "" Vector__XXX
 SG_ Hvsp25DsPwLtDTBttOCVt : 6|2@1+ (1,0) [0|3] "" Vector__XXX
 SG_ Hvsp25DshrgPwrLmtDTBttrCrrnt : 8|2@1+ (1,0) [0|3] "" Vector__XXX
 SG_ Hvsp25DshrgPwrLmtDTAnUndfndCs : 10|2@1+ (1,0) [0|3] "" Vector__XXX
 SG_ Hvsp25ChrgPwrLmtDTSttOfChrg : 32|2@1+ (1,0) [0|3] "" Vector__XXX
 SG_ Hvsp25ChrgPwrLmtDTBttrTmprtr : 34|2@1+ (1,0) [0|3] "" Vector__XXX
 SG_ Hvsp25CPwLtDTBttDstCdt : 36|2@1+ (1,0) [0|3] "" Vector__XXX
 SG_ Hvsp25ChrgPwrLmtDTBttrOrCllVltg : 38|2@1+ (1,0) [0|3] "" Vector__XXX
 SG_ Hvsp25ChrgPwrLmtDTBttrCrrnt : 40|2@1+ (1,0) [0|3] "" Vector__XXX
 SG_ Hvsp25ChrgPwrLmtDTAnUndfndCs : 42|2@1+ (1,0) [0|3] "" Vector__XXX

BO_ 2364744958 HVESP25D1: 8 Vector__XXX
 SG_ Hvesp25AvailableDischargePower : 0|16@1+ (0.05,0) [0|3212.75] "kW" Vector__XXX
 SG_ Hvesp25AvailableChargePower : 16|16@1+ (0.05,0) [0|3212.75] "kW" Vector__XXX
 SG_ Hvesp25VoltageLevel : 32|16@1+ (0.05,0) [0|3212.75] "V" Vector__XXX
 SG_ Hvesp25Current : 48|16@1+ (0.05,-1600) [-1600|1612.75] "A" Vector__XXX

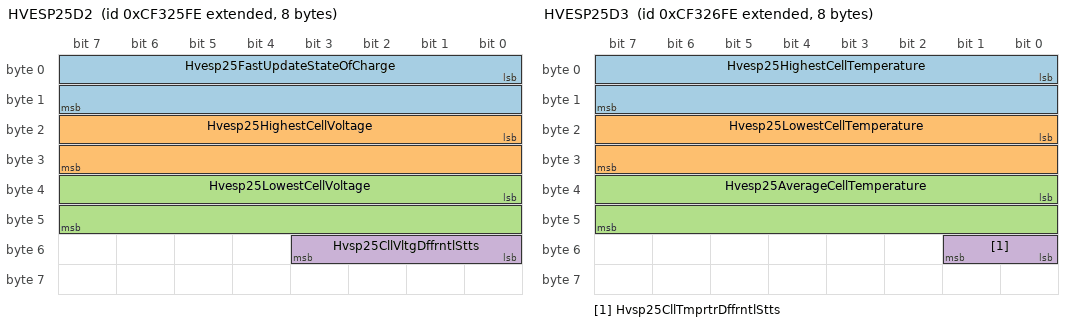
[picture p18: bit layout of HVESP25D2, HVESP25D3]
BO_ 2364745214 HVESP25D2: 8 Vector__XXX
 SG_ Hvesp25FastUpdateStateOfCharge : 0|16@1+ (0.0015625,0) [0|100.3984375] "%" Vector__XXX
 SG_ Hvesp25HighestCellVoltage : 16|16@1+ (0.001,0) [0|64.255] "V" Vector__XXX
 SG_ Hvesp25LowestCellVoltage : 32|16@1+ (0.001,0) [0|64.255] "V" Vector__XXX
 SG_ Hvsp25CllVltgDffrntlStts : 48|4@1+ (1,0) [0|15] "" Vector__XXX

BO_ 2364745470 HVESP25D3: 8 Vector__XXX
 SG_ Hvesp25HighestCellTemperature : 0|16@1+ (0.03125,-273) [-273|1734.96875] "degC" Vector__XXX
 SG_ Hvesp25LowestCellTemperature : 16|16@1+ (0.03125,-273) [-273|1734.96875] "degC" Vector__XXX
 SG_ Hvesp25AverageCellTemperature : 32|16@1+ (0.03125,-273) [-273|1734.96875] "degC" Vector__XXX
 SG_ Hvsp25CllTmprtrDffrntlStts : 48|2@1+ (1,0) [0|3] "" Vector__XXX

BO_ 2364745726 HVESP25D4: 8 Vector__XXX
 SG_ Hvesp25DischargeCapacity : 0|16@1+ (0.01,0) [0|642.55] "Ah" Vector__XXX
 SG_ Hvesp25ChargeCapacity : 16|16@1+ (0.01,0) [0|642.55] "Ah" Vector__XXX
 SG_ Hvesp25CellBalancingCount : 32|16@1+ (1,0) [0|64255] "count" Vector__XXX

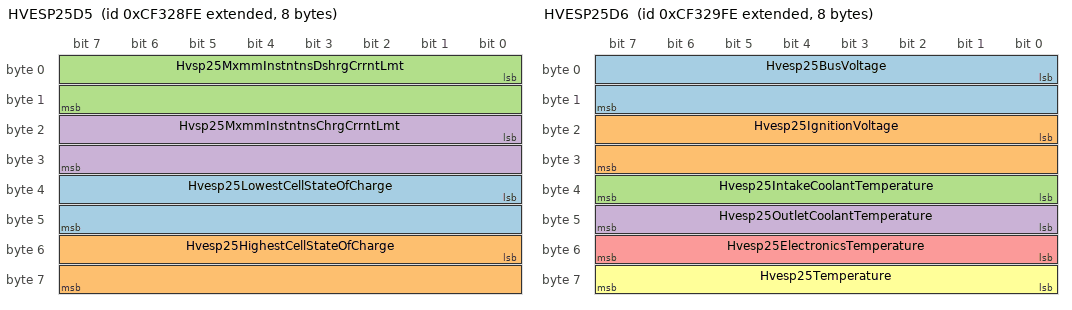
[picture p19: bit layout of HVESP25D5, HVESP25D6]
BO_ 2364745982 HVESP25D5: 8 Vector__XXX
 SG_ Hvesp25LowestCellStateOfCharge : 32|16@1+ (0.0015625,0) [0|100.3984375] "%" Vector__XXX
 SG_ Hvesp25HighestCellStateOfCharge : 48|16@1+ (0.0015625,0) [0|100.3984375] "%" Vector__XXX
 SG_ Hvsp25MxmmInstntnsDshrgCrrntLmt : 0|16@1+ (0.05,-1600) [-1600|0] "A" Vector__XXX
 SG_ Hvsp25MxmmInstntnsChrgCrrntLmt : 16|16@1+ (0.05,-1600) [0|1612.75] "A" Vector__XXX

BO_ 2364746238 HVESP25D6: 8 Vector__XXX
 SG_ Hvesp25BusVoltage : 0|16@1+ (0.05,0) [0|3212.75] "V" Vector__XXX
 SG_ Hvesp25IgnitionVoltage : 16|16@1+ (0.01,0) [0|642.55] "V" Vector__XXX
 SG_ Hvesp25IntakeCoolantTemperature : 32|8@1+ (1,-40) [-40|210] "degC" Vector__XXX
 SG_ Hvesp25OutletCoolantTemperature : 40|8@1+ (1,-40) [-40|210] "degC" Vector__XXX
 SG_ Hvesp25ElectronicsTemperature : 48|8@1+ (1,-40) [-40|210] "degC" Vector__XXX
 SG_ Hvesp25Temperature : 56|8@1+ (1,-40) [-40|210] "degC" Vector__XXX

BO_ 2364746494 HVESP25S1: 8 Vector__XXX
 SG_ Hvsp25HghVltgBsPstvCnttrStt : 0|2@1+ (1,0) [0|3] "" Vector__XXX
 SG_ Hvsp25HghVltgBsNgtvCnttrStt : 2|2@1+ (1,0) [0|3] "" Vector__XXX
 SG_ Hvsp25HghVltgBsDsnntFrwrnng : 4|4@1+ (1,0) [0|15] "" Vector__XXX
 SG_ Hvsp25HghVltgBsPrChrgRlStt : 8|2@1+ (1,0) [0|3] "" Vector__XXX
 SG_ Hvsp25CntrOfPkCnttrStt : 10|2@1+ (1,0) [0|3] "" Vector__XXX
 SG_ Hvsp25HghVltgBsAtvIsltnTstStts : 12|4@1+ (1,0) [0|15] "" Vector__XXX
 SG_ Hvsp25HghVltgBsPssvIsltnTstStts : 16|4@1+ (1,0) [0|15] "" Vector__XXX
 SG_ Hvesp25HvilStatus : 20|2@1+ (1,0) [0|3] "" Vector__XXX
 SG_ Hvesp25InertiaSwitchStatus : 22|2@1+ (1,0) [0|3] "" Vector__XXX
 SG_ Hvesp25StateOfChargeStatus : 24|4@1+ (1,0) [0|15] "" Vector__XXX
 SG_ Hvesp25CellBalanceStatus : 28|2@1+ (1,0) [0|3] "" Vector__XXX
 SG_ Hvesp25CellBalancingActive : 30|2@1+ (1,0) [0|3] "" Vector__XXX
 SG_ Hvesp25InternalChargerStatus : 32|2@1+ (1,0) [0|3] "" Vector__XXX
 SG_ Hvsp25HghVltgBsCnntnStts : 40|4@1+ (1,0) [0|15] "" Vector__XXX
 SG_ Hvesp25OperationalStatus : 44|4@1+ (1,0) [0|15] "" Vector__XXX
 SG_ Hvesp25Status1Counter : 52|4@1+ (1,0) [0|15] "" Vector__XXX
 SG_ Hvesp25Status1Crc : 56|8@1+ (1,0) [0|250] "count" Vector__XXX

BO_ 2364746750 HVESP25D7: 8 Vector__XXX
 SG_ Hvesp25DischargeEnergyCapacity : 0|24@1+ (0.001,0) [0|16449.535] "kWh" Vector__XXX
 SG_ Hvesp25ChargeEnergyCapacity : 24|24@1+ (0.001,0) [0|16449.535] "kWh" Vector__XXX
 SG_ Hvsp25MxmmChrgVltgLmt : 48|16@1+ (0.05,0) [0|3212.75] "V" Vector__XXX

CM_ BO_ 2364732414 "High Voltage Energy Storage Pack 21 Data 9";
CM_ SG_ 2364732414 Hvsp21HghstCllTmprtrMdlNmr "HVESP21 Highest Cell Temperature Module Number: Identifies the location of the module containing SPN 16720 (HVESP21 Highest Cell Temperature).This parameter is for one of multiple packs in an HVESS. If there is only one pack in the system, the HVESS ...";
CM_ SG_ 2364732414 Hvsp21HghstCllTmprtrCllNmr "HVESP21 Highest Cell Temperature Cell Number: Identifies the location of SPN 16720 (HVESP21 Highest Cell Temperature) within SPN 16802 (HVESP21 Highest Cell Temperature Module Number).This parameter is for one of multiple packs in an HVESS. If there ...";
CM_ SG_ 2364732414 Hvsp21LwstCllTmprtrMdlNmr "HVESP21 Lowest Cell Temperature Module Number: Identifies the location of the module containing SPN 16721 (HVESP21 Lowest Cell Temperature).This parameter is for one of multiple packs in an HVESS. If there is only one pack in the system, the HVESS pa...";
CM_ SG_ 2364732414 Hvsp21LwstCllTmprtrCllNmr "HVESP21 Lowest Cell Temperature Cell Number: Identifies the location of SPN 16721 (HVESP21 Lowest Cell Temperature) within SPN 16804 (HVESP21 Lowest Cell Temperature Module Number).This parameter is for one of multiple packs in an HVESS. If there is ...";
CM_ SG_ 2364732414 Hvess21ThermalEventDetected "HVESS21 Thermal Event Detected: A sensor has detected the presence of a thermal event at or near High Voltage Energy Storage Pack instance.00b = No Thermal Event Detected01b = Thermal Event Detected10b = Error11b = Not availableThis parameter is for ...";
CM_ SG_ 2364732414 Hvsp21Dt9EmdddIntgrtSpprt "HVESP21 Data 9 Embedded Integrity Support: Indicates SPN 23036 (HVESP21 Data 9 CRC) and SPN 23035 (HVESP21 Data 9 Counter) are supported by the sender.00b = Embedded CRC and Counter are supported by the sender01b = Protection is provided using an ext...";
CM_ SG_ 2364732414 Hvesp21Data9Counter "HVESP21 Data 9 Counter: The message counter is used to detect situations where the transmitting ECU malfunction repeats the same frame all the time. The receiver of the information may use the counter parameter to detect this situation. The transmitt...";
CM_ SG_ 2364732414 Hvesp21Data9Crc "HVESP21 Data 9 CRC: The CRC is defined as follows: - Length: 8 bits- Polynomial: x^8+x^5+x^3+x^2+x+1- Initial Value: FFh- Input Data Reflection: Not reflected- Result Data Reflection: Not reflected- XOR value: FFh SAE makes no claim of the functional...";
CM_ BO_ 2364732670 "High Voltage Energy Storage Pack 21 Data 10";
CM_ SG_ 2364732670 Hvsp21HghstCllSttOfChrgMdlNmr "HVESP21 Highest Cell State of Charge Module Number: Identifies the location of the module containing SPN 16730 (HVESP21 Highest Cell State of Charge).This parameter is for one of multiple packs in an HVESS. If there is only one pack in the system, th...";
CM_ SG_ 2364732670 Hvsp21HghstCllSttOfChrgCllNmr "HVESP21 Highest Cell State of Charge Cell Number: Identifies the location of SPN 16730 (HVESP21 Highest Cell State of Charge) within SPN 16806 (HVESP21 Highest Cell State of Charge Module Number).This parameter is for one of multiple packs in an HVES...";
CM_ SG_ 2364732670 Hvsp21LwstCllSttOfChrgMdlNmr "HVESP21 Lowest Cell State of Charge Module Number: Identifies the location of the module containing SPN 16729 (HVESP21 Lowest Cell State of Charge).This parameter is for one of multiple packs in an HVESS. If there is only one pack in the system, the ...";
CM_ SG_ 2364732670 Hvsp21LwstCllSttOfChrgCllNmr "HVESP21 Lowest Cell State of Charge Cell Number: Identifies the location of SPN 16729 (HVESP21 Lowest Cell State of Charge) within SPN 16808 (HVESP21 Lowest Cell State of Charge Module Number).This parameter is for one of multiple packs in an HVESS. ...";
CM_ SG_ 2364732670 Hvsp21HghVltgBsAtvIsltnTstRslts "HVESP21 High-Voltage Bus Active Isolation Test Results: The isolation resistance expressed in Ohms per Volt that resulted from the High-Voltage Bus Active Isolation Test.See SPN 16742 (HVESP21 High-Voltage Bus Active Isolation Test Status) for test s...";
CM_ SG_ 2364732670 Hvsp21HVtBsPssvIstTstRsts "HVESP21 High-Voltage Bus Passive Isolation Test Results: The isolation resistance expressed in Ohms per Volt that resulted from the High-Voltage Bus Passive Isolation Test.See SPN 16743 (HVESP21 High-Voltage Bus Passive Isolation Test Status) for tes...";
CM_ BO_ 2364732926 "High Voltage Energy Storage Pack 21 Data 11";
CM_ SG_ 2364732926 Hvsp21BsVltgNgtvTChsssGrndVltg "HVESP21 Bus Voltage Negative to Chassis Ground Voltage: Voltage difference between the most negative terminal of the HVES battery and chassis measured on the hybrid or EV system bus side (not the battery side) of any HVES contained output contactor. ...";
CM_ SG_ 2364732926 Hvsp21VltgLvlNgtvTChsssGrndVltg "HVESP21 Voltage Level Negative to Chassis Ground Voltage: Voltage difference between the most negative terminal of the HVES battery and chassis measured at the battery side of any HVES contained output contactor.  This voltage may be used for system ...";
CM_ SG_ 2364732926 Hvesp21ActualChargeRate "HVESP21 Actual Charge Rate: This signal represents the actual present charge rate of this High Voltage Energy Storage Pack instance.This parameter is for one of multiple packs in an HVESS. If there is only one pack in the system, the HVESS parameters...";
CM_ BO_ 2364733182 "High Voltage Energy Storage Pack 22 Status 2";
CM_ SG_ 2364733182 Hvsp22DshrgPwrLmtDTSttOfChrg "HVESP22 Discharge Power Limit Due to State of Charge: Indicates whether or not discharge power of this HVES instance is being limited due to state of charge.This parameter is for one of multiple packs in an HVESS.  If there is only one pack in the sy...";
CM_ SG_ 2364733182 Hvsp22DshrgPwrLmtDTBttrTmprtr "HVESP22 Discharge Power Limit Due to Battery Temperature: Indicates whether or not discharge power of this HVES instance is being limited due to battery temperature.This parameter is for one of multiple packs in an HVESS.  If there is only one pack i...";
CM_ SG_ 2364733182 Hvsp22DsPwLtDTBttDstCdt "HVESP22 Discharge Power Limit Due to Battery Diagnostic Condition: Indicates whether or not discharge power of this HVES instance is being limited due to a battery diagnostic condition.This parameter is for one of multiple packs in an HVESS.  If ther...";
CM_ SG_ 2364733182 Hvsp22DsPwLtDTBttOCVt "HVESP22 Discharge Power Limit Due to Battery or Cell Voltage: Indicates whether or not discharge power of this HVES instance is being limited due to a battery or cell voltage level.This parameter is for one of multiple packs in an HVESS.  If there is...";
CM_ SG_ 2364733182 Hvsp22DshrgPwrLmtDTBttrCrrnt "HVESP22 Discharge Power Limit Due to Battery Current: Indicates whether or not discharge power of this HVES instance is being limited due to battery current.This parameter is for one of multiple packs in an HVESS.  If there is only one pack in the sy...";
CM_ SG_ 2364733182 Hvsp22DshrgPwrLmtDTAnUndfndCs "HVESP22 Discharge Power Limit Due to an Undefined Cause: Indicates whether or not discharge power of this HVES instance is being limited due to an undefined cause.This parameter is for one of multiple packs in an HVESS.  If there is only one pack in ...";
CM_ SG_ 2364733182 Hvsp22ChrgPwrLmtDTSttOfChrg "HVESP22 Charge Power Limit Due to State of Charge: Indicates whether or not charge power of this HVES instance is being limited due to state of charge.This parameter is for one of multiple packs in an HVESS.  If there is only one pack in the system, ...";
CM_ SG_ 2364733182 Hvsp22ChrgPwrLmtDTBttrTmprtr "HVESP22 Charge Power Limit Due to Battery Temperature: Indicates whether or not charge power of this HVES instance is being limited due to battery temperature.This parameter is for one of multiple packs in an HVESS.  If there is only one pack in the ...";
CM_ SG_ 2364733182 Hvsp22CPwLtDTBttDstCdt "HVESP22 Charge Power Limit Due to Battery Diagnostic Condition: Indicates whether or not charge power of this HVES instance is being limited due to a battery diagnostic condition.This parameter is for one of multiple packs in an HVESS.  If there is o...";
CM_ SG_ 2364733182 Hvsp22ChrgPwrLmtDTBttrOrCllVltg "HVESP22 Charge Power Limit Due to Battery or Cell Voltage: Indicates whether or not charge power of this HVES instance is being limited due to a battery or cell voltage level.This parameter is for one of multiple packs in an HVESS.  If there is only ...";
CM_ SG_ 2364733182 Hvsp22ChrgPwrLmtDTBttrCrrnt "HVESP22 Charge Power Limit Due to Battery Current: Indicates whether or not charge power of this HVES instance is being limited due to battery current.This parameter is for one of multiple packs in an HVESS.  If there is only one pack in the system, ...";
CM_ SG_ 2364733182 Hvsp22ChrgPwrLmtDTAnUndfndCs "HVESP22 Charge Power Limit Due to an Undefined Cause: Indicates whether or not charge power of this HVES instance is being limited due to an undefined cause.This parameter is for one of multiple packs in an HVESS.  If there is only one pack in the sy...";
CM_ BO_ 2364733438 "High Voltage Energy Storage Pack 22 Data 1";
CM_ SG_ 2364733438 Hvesp22AvailableDischargePower "HVESP22 Available Discharge Power: The rate at which this High Voltage Energy Storage Pack instance can currently provide energy for propulsion or other uses.This parameter is for one of multiple packs in an HVESS.  If there is only one pack in the s...";
CM_ SG_ 2364733438 Hvesp22AvailableChargePower "HVESP22 Available Charge Power: The rate at which this High Voltage Energy Storage Pack instance can currently receive energy from a regenerative or recharging system.This parameter is for one of multiple packs in an HVESS.  If there is only one pack...";
CM_ SG_ 2364733438 Hvesp22VoltageLevel "HVESP22 Voltage Level: The voltage level of this High Voltage Energy Storage Pack instance. This parameter should be synchronized with SPN 16857 (HVESP22 Current) such that a realized power value can be calculated. If the HVES component physically co...";
CM_ SG_ 2364733438 Hvesp22Current "HVESP22 Current: The current in or out of this High Voltage Energy Storage Pack instance. This parameter should be synchronized with SPN 16856 (HVESP22 Voltage Level) such that a realized power value can be calculated. This parameter is defined from ...";
CM_ BO_ 2364733694 "High Voltage Energy Storage Pack 22 Data 2";
CM_ SG_ 2364733694 Hvesp22FastUpdateStateOfCharge "HVESP22 Fast Update State of Charge: Indicates this High Voltage Energy Storage Pack instance state of charge. 0% means no charge remaining, 100% means the system is fully charged in terms of physical limits of this energy storage pack instance. Acce...";
CM_ SG_ 2364733694 Hvesp22HighestCellVoltage "HVESP22 Highest Cell Voltage: The highest voltage level reported by any cell in this High Voltage Energy Storage Pack instance. If a single voltage sensor covers more than one cell, the value in this parameter is for the smallest group of cells measu...";
CM_ SG_ 2364733694 Hvesp22LowestCellVoltage "HVESP22 Lowest Cell Voltage: The lowest voltage level reported by any cell in this High Voltage Energy Storage Pack instance. If a single voltage sensor covers more than one cell, the value in this parameter is for the smallest group of cells measure...";
CM_ SG_ 2364733694 Hvsp22CllVltgDffrntlStts "HVESP22 Cell Voltage Differential Status: Indicates whether or not the differential between the highest and lowest cell voltages are within acceptable limits, according to this High Voltage Energy Storage Pack instance. The actual voltage differentia...";
CM_ BO_ 2364733950 "High Voltage Energy Storage Pack 22 Data 3";
CM_ SG_ 2364733950 Hvesp22HighestCellTemperature "HVESP22 Highest Cell Temperature: The highest temperature level reported by any cell in this High Voltage Energy Storage Pack instance. If a single temperature sensor covers more than one cell, the value in this parameter is for the smallest group of...";
CM_ SG_ 2364733950 Hvesp22LowestCellTemperature "HVESP22 Lowest Cell Temperature: The lowest temperature level reported by any cell in this High Voltage Energy Storage Pack instance. If a single temperature sensor covers more than one cell, the value in this parameter is for the smallest group of c...";
CM_ SG_ 2364733950 Hvesp22AverageCellTemperature "HVESP22 Average Cell Temperature: The average temperature level of all cells in this High Voltage Energy Storage Pack instance.This parameter is for one of multiple packs in an HVESS.  If there is only one pack in the system, the HVESS parameters sho...";
CM_ SG_ 2364733950 Hvsp22CllTmprtrDffrntlStts "HVESP22 Cell Temperature Differential Status: Indicates whether or not the differential between the highest and lowest cell temperatures are within acceptable limits per this High Voltage Energy Storage Pack instance. The actual temperature different...";
CM_ BO_ 2364734206 "High Voltage Energy Storage Pack 22 Data 4";
CM_ SG_ 2364734206 Hvesp22DischargeCapacity "HVESP22 Discharge Capacity: The amount of stored electrical charge in this High Voltage Energy Storage Pack instance that is available for use by the hybrid or EV system, i.e. 'how full is the tank'. See SPN 16896 (HVESP22 Discharge Energy Capacity) ...";
CM_ SG_ 2364734206 Hvesp22ChargeCapacity "HVESP22 Charge Capacity: The amount of unused electrical charge storage in this High Voltage Energy Storage Pack instance that is available to be filled by charging, i.e. 'how much empty space is remaining in the tank'. See SPN 16897 (HVESP22 Charge ...";
CM_ SG_ 2364734206 Hvesp22CellBalancingCount "HVESP22 Cell Balancing Count: The number of cells that are currently being balanced in this High Voltage Energy Storage Pack instance.This parameter is for one of multiple packs in an HVESS.  If there is only one pack in the system, the HVESS paramet...";
CM_ BO_ 2364734462 "High Voltage Energy Storage Pack 22 Data 5";
CM_ SG_ 2364734462 Hvesp22LowestCellStateOfCharge "HVESP22 Lowest Cell State of Charge: Indicates the state of charge of the lowest-charged cell in this High Voltage Energy Storage Pack instance. 0% means no charge remaining, 100% means the cell is fully charged. If a single state of charge value cov...";
CM_ SG_ 2364734462 Hvesp22HighestCellStateOfCharge "HVESP22 Highest Cell State of Charge: Indicates the state of charge of the highest-charged cell in this High Voltage Energy Storage Pack instance. 0% means no charge remaining, 100% means the cell is fully charged. If a single state of charge value c...";
CM_ SG_ 2364734462 Hvsp22MxmmInstntnsDshrgCrrntLmt "HVESP22 Maximum Instantaneous Discharge Current Limit: The maximum instantaneous current flow limit out of this High Voltage Energy Storage Pack instance. This parameter is defined from the high voltage energy storage pack's point of view and should ...";
CM_ SG_ 2364734462 Hvsp22MxmmInstntnsChrgCrrntLmt "HVESP22 Maximum Instantaneous Charge Current Limit: The maximum instantaneous current flow limit into this High Voltage Energy Storage Pack instance. This parameter is defined from the high voltage energy storage pack's point of view and should refle...";
CM_ BO_ 2364734718 "High Voltage Energy Storage Pack 22 Data 6";
CM_ SG_ 2364734718 Hvesp22BusVoltage "HVESP22 Bus Voltage: The voltage level of the high voltage bus, as measured by this High Voltage Energy Storage Pack instance on the bus side (not the battery side) of its contactors.This parameter is for one of multiple packs in an HVESS.  If there ...";
CM_ SG_ 2364734718 Hvesp22IgnitionVoltage "HVESP22 Ignition Voltage: The voltage level at the ignition input of this High Voltage Energy Storage Pack controller.This parameter is for one of multiple packs in an HVESS.  If there is only one pack in the system, the HVESS parameters should be us...";
CM_ SG_ 2364734718 Hvesp22IntakeCoolantTemperature "HVESP22 Intake Coolant Temperature: The temperature of liquid coolant as it enters this High Voltage Energy Storage Pack instance.This parameter is for one of multiple packs in an HVESS.  If there is only one pack in the system, the HVESS parameters ...";
CM_ SG_ 2364734718 Hvesp22OutletCoolantTemperature "HVESP22 Outlet Coolant Temperature: The temperature of liquid coolant as it exits this High Voltage Energy Storage Pack instance.This parameter is for one of multiple packs in an HVESS.  If there is only one pack in the system, the HVESS parameters s...";
CM_ SG_ 2364734718 Hvesp22ElectronicsTemperature "HVESP22 Electronics Temperature: The temperature of the electronics or control modules in this High Voltage Energy Storage Pack instance.  If there are multiple temperature sensors then this parameter would be set to the maximum sensor reading.This p...";
CM_ SG_ 2364734718 Hvesp22Temperature "HVESP22 Temperature: The temperature of this High Voltage Energy Storage Pack instance. The value may be determined from a unique sensor specifically for this purpose, or by aggregating various temperature sensor readings within the pack.This paramet...";
CM_ BO_ 2364734974 "High Voltage Energy Storage Pack 22 Status 1";
CM_ SG_ 2364734974 Hvsp22HghVltgBsPstvCnttrStt "HVESP22 High-Voltage Bus (Positive) Contactor State: Position of this High Voltage Energy Storage Pack instance positive side bus contactor.  When this contactor is closed, the positive side of this HVES instance is connected to the positive side of ...";
CM_ SG_ 2364734974 Hvsp22HghVltgBsNgtvCnttrStt "HVESP22 High-Voltage Bus (Negative) Contactor State: Position of this High Voltage Energy Storage Pack instance negative side bus contactor. When this contactor is closed, the negative side of this HVES instance is connected to the negative side of t...";
CM_ SG_ 2364734974 Hvsp22HghVltgBsDsnntFrwrnng "HVESP22 High-Voltage Bus Disconnect Forewarning: Indicates that this High Voltage Energy Storage Pack instance is about to disconnect from the high voltage bus due to unacceptable conditions.This parameter is for one of multiple packs in an HVESS. If...";
CM_ SG_ 2364734974 Hvsp22HghVltgBsPrChrgRlStt "HVESP22 High-Voltage Bus Pre-Charge Relay State: Position of the high-voltage bus contactor pre-charge relay.  When this relay is closed, this High Voltage Energy Storage Pack instance is bringing the high-voltage bus up to its operating level.This p...";
CM_ SG_ 2364734974 Hvsp22CntrOfPkCnttrStt "HVESP22 Center of Pack Contactor State: Position of the center high-voltage contactor. When this contactor is closed, the positive half of this High Voltage Energy Storage Pack instance is connected to the negative half. If a system controls the posi...";
CM_ SG_ 2364734974 Hvsp22HghVltgBsAtvIsltnTstStts "HVESP22 High-Voltage Bus Active Isolation Test Status: Status of the high-voltage bus electrical active isolation test as performed by this High Voltage Energy Storage Pack instance.This parameter is for one of multiple packs in an HVESS. If there is...";
CM_ SG_ 2364734974 Hvsp22HghVltgBsPssvIsltnTstStts "HVESP22 High-Voltage Bus Passive Isolation Test Status: Status of the high-voltage bus electrical passive isolation test as performed by this High Voltage Energy Storage Pack instance.This parameter is for one of multiple packs in an HVESS. If there ...";
CM_ SG_ 2364734974 Hvesp22HvilStatus "HVESP22 HVIL Status: Status of the High Voltage Interlock Loop from the viewpoint of this High Voltage Energy Storage Pack instance.This parameter is for one of multiple packs in an HVESS. If there is only one pack in the system, the HVESS parameters...";
CM_ SG_ 2364734974 Hvesp22InertiaSwitchStatus "HVESP22 Inertia Switch Status: Switch indicating that an impact has been sensed by this High Voltage Energy Storage Pack instance. The impact indication may require action by another controller, or by this HVES instance itself.  For example, a contro...";
CM_ SG_ 2364734974 Hvesp22StateOfChargeStatus "HVESP22 State of Charge Status: Status of this High Voltage Energy Storage Pack instance State of Charge (SOC).  Note:  A given HVES controller may not support all of the states.This parameter is for one of multiple packs in an HVESS.  If there is on...";
CM_ SG_ 2364734974 Hvesp22CellBalanceStatus "HVESP22 Cell Balance Status: Indicates whether or not the cells in this High Voltage Energy Storage Pack instance are balanced.This parameter is for one of multiple packs in an HVESS.  If there is only one pack in the system, the HVESS parameters sho...";
CM_ SG_ 2364734974 Hvesp22CellBalancingActive "HVESP22 Cell Balancing Active: Indicates whether or not the cells in this High Voltage Energy Storage Pack instance are currently being balanced.This parameter is for one of multiple packs in an HVESS.  If there is only one pack in the system, the HV...";
CM_ SG_ 2364734974 Hvesp22InternalChargerStatus "HVESP22 Internal Charger Status: Indicates that the charger in this HVES instance is on.  External chargers may use the External Energy Source Connection Status (SPN 7898) and related SPs.This parameter is for one of multiple packs in an HVESS. If th...";
CM_ SG_ 2364734974 Hvsp22HghVltgBsCnntnStts "HVESP22 High-Voltage Bus Connection Status: This parameter provides high level feedback on this High Voltage Energy Storage Pack instance high voltage bus connection. For specific contactor information, see SPN 16879 (HVESP22 High-Voltage Bus (Positi...";
CM_ SG_ 2364734974 Hvesp22OperationalStatus "HVESP22 Operational Status: Provides feedback on where this High Voltage Energy Storage Pack instance is in its operating spectrum, and includes feedback in response to the Operation Consent [i.e. SPN 16837 (HVESP22 Operation Consent)] and Power Down...";
CM_ SG_ 2364734974 Hvesp22Status1Counter "HVESP22 Status 1 Counter: The message counter is used to detect situations where the transmitting ECU malfunction repeats the same frame all the time. The receiver of the information may use the counter parameter to detect this situation. The transmi...";
CM_ SG_ 2364734974 Hvesp22Status1Crc "HVESP22 Status 1 CRC: The CRC is defined as follows: - Length: 8 bits- Polynomial: x^8+x^5+x^3+x^2+x+1- Initial Value: FFh- Input Data Reflection: Not reflected- Result Data Reflection: Not reflected- XOR value: FFh SAE makes no claim of the function...";
CM_ BO_ 2364735230 "High Voltage Energy Storage Pack 22 Data 7";
CM_ SG_ 2364735230 Hvesp22DischargeEnergyCapacity "HVESP22 Discharge Energy Capacity: The amount of stored electrical energy in this High Voltage Energy Storage Pack instance that is available for use by the hybrid or EV system, i.e. 'how full is the tank'. See SPN 16866 (HVESP22 Discharge Capacity) ...";
CM_ SG_ 2364735230 Hvesp22ChargeEnergyCapacity "HVESP22 Charge Energy Capacity: The amount of unused electrical energy storage available to be filled by charging this High Voltage Energy Storage Pack instance, i.e. 'how much empty space is remaining in the tank'. See SPN 16867 (HVESP22 Charge Capa...";
CM_ SG_ 2364735230 Hvsp22MxmmChrgVltgLmt "HVESP22 Maximum Charge Voltage Limit: The maximum voltage level not to be exceeded while charging this High Voltage Energy Storage Pack instance. If this parameter is not supported, the maximum charge voltage should be limited to SPN 16965 (HVESP22 R...";
CM_ BO_ 2364735486 "High Voltage Energy Storage Pack 22 Module Status 1";
CM_ SG_ 2364735486 Hvesp22Module1OperationalStatus "HVESP22 Module 1 Operational Status: Operational Status of Module 1 in this High Voltage Energy Storage Pack Instance.  Not Operational is used when the module is initializing or not able to function (e.g. internal module level monitors have failed)....";
CM_ SG_ 2364735486 Hvesp22Module2OperationalStatus "HVESP22 Module 2 Operational Status: Operational Status of Module 2 in this High Voltage Energy Storage Pack Instance.  Not Operational is used when the module is initializing or not able to function (e.g. internal module level monitors have failed)....";
CM_ SG_ 2364735486 Hvesp22Module3OperationalStatus "HVESP22 Module 3 Operational Status: Operational Status of Module 3 in this High Voltage Energy Storage Pack Instance.  Not Operational is used when the module is initializing or not able to function (e.g. internal module level monitors have failed)....";
CM_ SG_ 2364735486 Hvesp22Module4OperationalStatus "HVESP22 Module 4 Operational Status: Operational Status of Module 4 in this High Voltage Energy Storage Pack Instance.  Not Operational is used when the module is initializing or not able to function (e.g. internal module level monitors have failed)....";
CM_ SG_ 2364735486 Hvesp22Module5OperationalStatus "HVESP22 Module 5 Operational Status: Operational Status of Module 5 in this High Voltage Energy Storage Pack Instance.  Not Operational is used when the module is initializing or not able to function (e.g. internal module level monitors have failed)....";
CM_ SG_ 2364735486 Hvesp22Module6OperationalStatus "HVESP22 Module 6 Operational Status: Operational Status of Module 6 in this High Voltage Energy Storage Pack Instance.  Not Operational is used when the module is initializing or not able to function (e.g. internal module level monitors have failed)....";
CM_ SG_ 2364735486 Hvesp22Module7OperationalStatus "HVESP22 Module 7 Operational Status: Operational Status of Module 7 in this High Voltage Energy Storage Pack Instance.  Not Operational is used when the module is initializing or not able to function (e.g. internal module level monitors have failed)....";
CM_ SG_ 2364735486 Hvesp22Module8OperationalStatus "HVESP22 Module 8 Operational Status: Operational Status of Module 8 in this High Voltage Energy Storage Pack Instance.  Not Operational is used when the module is initializing or not able to function (e.g. internal module level monitors have failed)....";
CM_ SG_ 2364735486 Hvesp22Module9OperationalStatus "HVESP22 Module 9 Operational Status: Operational Status of Module 9 in this High Voltage Energy Storage Pack Instance.  Not Operational is used when the module is initializing or not able to function (e.g. internal module level monitors have failed)....";
CM_ SG_ 2364735486 Hvsp22Mdl10OprtnlStts "HVESP22 Module 10 Operational Status: Operational Status of Module 10 in this High Voltage Energy Storage Pack Instance.  Not Operational is used when the module is initializing or not able to function (e.g. internal module level monitors have failed...";
CM_ SG_ 2364735486 Hvsp22Mdl11OprtnlStts "HVESP22 Module 11 Operational Status: Operational Status of Module 11 in this High Voltage Energy Storage Pack Instance.  Not Operational is used when the module is initializing or not able to function (e.g. internal module level monitors have failed...";
CM_ SG_ 2364735486 Hvsp22Mdl12OprtnlStts "HVESP22 Module 12 Operational Status: Operational Status of Module 12 in this High Voltage Energy Storage Pack Instance.  Not Operational is used when the module is initializing or not able to function (e.g. internal module level monitors have failed...";
CM_ SG_ 2364735486 Hvsp22Mdl13OprtnlStts "HVESP22 Module 13 Operational Status: Operational Status of Module 13 in this High Voltage Energy Storage Pack Instance.  Not Operational is used when the module is initializing or not able to function (e.g. internal module level monitors have failed...";
CM_ SG_ 2364735486 Hvsp22Mdl14OprtnlStts "HVESP22 Module 14 Operational Status: Operational Status of Module 14 in this High Voltage Energy Storage Pack Instance.  Not Operational is used when the module is initializing or not able to function (e.g. internal module level monitors have failed...";
CM_ SG_ 2364735486 Hvsp22Mdl15OprtnlStts "HVESP22 Module 15 Operational Status: Operational Status of Module 15 in this High Voltage Energy Storage Pack Instance.  Not Operational is used when the module is initializing or not able to function (e.g. internal module level monitors have failed...";
CM_ SG_ 2364735486 Hvsp22Mdl16OprtnlStts "HVESP22 Module 16 Operational Status: Operational Status of Module 16 in this High Voltage Energy Storage Pack Instance.  Not Operational is used when the module is initializing or not able to function (e.g. internal module level monitors have failed...";
CM_ SG_ 2364735486 Hvsp22Mdl17OprtnlStts "HVESP22 Module 17 Operational Status: Operational Status of Module 17 in this High Voltage Energy Storage Pack Instance.  Not Operational is used when the module is initializing or not able to function (e.g. internal module level monitors have failed...";
CM_ SG_ 2364735486 Hvsp22Mdl18OprtnlStts "HVESP22 Module 18 Operational Status: Operational Status of Module 18 in this High Voltage Energy Storage Pack Instance.  Not Operational is used when the module is initializing or not able to function (e.g. internal module level monitors have failed...";
CM_ SG_ 2364735486 Hvsp22Mdl19OprtnlStts "HVESP22 Module 19 Operational Status: Operational Status of Module 19 in this High Voltage Energy Storage Pack Instance.  Not Operational is used when the module is initializing or not able to function (e.g. internal module level monitors have failed...";
CM_ SG_ 2364735486 Hvsp22Mdl20OprtnlStts "HVESP22 Module 20 Operational Status: Operational Status of Module 20 in this High Voltage Energy Storage Pack Instance.  Not Operational is used when the module is initializing or not able to function (e.g. internal module level monitors have failed...";
CM_ SG_ 2364735486 Hvsp22Mdl21OprtnlStts "HVESP22 Module 21 Operational Status: Operational Status of Module 21 in this High Voltage Energy Storage Pack Instance.  Not Operational is used when the module is initializing or not able to function (e.g. internal module level monitors have failed...";
CM_ SG_ 2364735486 Hvsp22Mdl22OprtnlStts "HVESP22 Module 22 Operational Status: Operational Status of Module 22 in this High Voltage Energy Storage Pack Instance.  Not Operational is used when the module is initializing or not able to function (e.g. internal module level monitors have failed...";
CM_ SG_ 2364735486 Hvsp22Mdl23OprtnlStts "HVESP22 Module 23 Operational Status: Operational Status of Module 23 in this High Voltage Energy Storage Pack Instance.  Not Operational is used when the module is initializing or not able to function (e.g. internal module level monitors have failed...";
CM_ SG_ 2364735486 Hvsp22Mdl24OprtnlStts "HVESP22 Module 24 Operational Status: Operational Status of Module 24 in this High Voltage Energy Storage Pack Instance.  Not Operational is used when the module is initializing or not able to function (e.g. internal module level monitors have failed...";
CM_ SG_ 2364735486 Hvsp22Mdl25OprtnlStts "HVESP22 Module 25 Operational Status: Operational Status of Module 25 in this High Voltage Energy Storage Pack Instance.  Not Operational is used when the module is initializing or not able to function (e.g. internal module level monitors have failed...";
CM_ SG_ 2364735486 Hvsp22Mdl26OprtnlStts "HVESP22 Module 26 Operational Status: Operational Status of Module 26 in this High Voltage Energy Storage Pack Instance.  Not Operational is used when the module is initializing or not able to function (e.g. internal module level monitors have failed...";
CM_ SG_ 2364735486 Hvsp22Mdl27OprtnlStts "HVESP22 Module 27 Operational Status: Operational Status of Module 27 in this High Voltage Energy Storage Pack Instance.  Not Operational is used when the module is initializing or not able to function (e.g. internal module level monitors have failed...";
CM_ SG_ 2364735486 Hvsp22Mdl28OprtnlStts "HVESP22 Module 28 Operational Status: Operational Status of Module 28 in this High Voltage Energy Storage Pack Instance.  Not Operational is used when the module is initializing or not able to function (e.g. internal module level monitors have failed...";
CM_ SG_ 2364735486 Hvsp22Mdl29OprtnlStts "HVESP22 Module 29 Operational Status: Operational Status of Module 29 in this High Voltage Energy Storage Pack Instance.  Not Operational is used when the module is initializing or not able to function (e.g. internal module level monitors have failed...";
CM_ SG_ 2364735486 Hvsp22Mdl30OprtnlStts "HVESP22 Module 30 Operational Status: Operational Status of Module 30 in this High Voltage Energy Storage Pack Instance.  Not Operational is used when the module is initializing or not able to function (e.g. internal module level monitors have failed...";
CM_ SG_ 2364735486 Hvsp22Mdl31OprtnlStts "HVESP22 Module 31 Operational Status: Operational Status of Module 31 in this High Voltage Energy Storage Pack Instance.  Not Operational is used when the module is initializing or not able to function (e.g. internal module level monitors have failed...";
CM_ SG_ 2364735486 Hvsp22Mdl32OprtnlStts "HVESP22 Module 32 Operational Status: Operational Status of Module 32 in this High Voltage Energy Storage Pack Instance.  Not Operational is used when the module is initializing or not able to function (e.g. internal module level monitors have failed...";
CM_ BO_ 2364735742 "High Voltage Energy Storage Pack 22 Thermal Management System Status 1";
CM_ SG_ 2364735742 Hvsp22ThrmlMngmntSstmSlInptPwr "HVESP22 Thermal Management System SLI Input Power: This is the low-voltage power consumed by this HVES Thermal Management System (TMS).This parameter is for one of multiple packs in an HVESS.  If there is only one pack in the system, the HVESS parame...";
CM_ SG_ 2364735742 Hvsp22TMtSstHVtIptPw "HVESP22 Thermal Management System High-Voltage Input Power: This is the high-voltage power consumed by this HVES Thermal Management System (TMS).This parameter is for one of multiple packs in an HVESS.  If there is only one pack in the system, the HV...";
CM_ SG_ 2364735742 Hvsp22ThrmlMngmntSstmCmprssrSpd "HVESP22 Thermal Management System Compressor Speed: When this High Voltage Energy Storage Pack Thermal Management System is equipped with an active cooling system (e.g. air conditioner), this is the Compressor Speed.This parameter is for one of multi...";
CM_ SG_ 2364735742 Hvsp22ThrmlMngmntSstmRltvHmdt "HVESP22 Thermal Management System Relative Humidty: When this High Voltage Energy Storage Pack Thermal Management System is equipped with a relative humidity sensor, this is the  measured Relative Humidity.This parameter is for one of multiple packs ...";
CM_ SG_ 2364735742 Hvsp22ThrmlMngmntSstmHtrStts "HVESP22 Thermal Management System Heater Status: The state of this High Voltage Energy Storage Pack heaterThis parameter is for one of multiple packs in an HVESS.  If there is only one pack in the system, the HVESS parameters should be used. If there...";
CM_ SG_ 2364735742 Hvsp22ThrmlMngmntSstmHvlStts "HVESP22 Thermal Management System HVIL Status: In multiple HVES configurations, this is the status of the High Voltage Interlock Loop from the viewpoint of this Thermal Management System.00b = HVIL Closed01b = HVIL Open10b = Error11b = Not AvailableT...";
CM_ SG_ 2364735742 Hvsp22ThrmlMngmntSstmMd "HVESP22 Thermal Management System Mode: Indicates the operating mode of the Thermal Management System.  The heat transfer medium may be (e.g. liquid or air).  The cooling system may be fans, liquid coolant, or a combination of mediums.  The system ma...";
CM_ SG_ 2364735742 Hvsp22ThrmlMngmntSstmClntLvl "HVESP22 Thermal Management System Coolant Level: Indicates the coolant level in this HVES Thermal Management System (TMS).This parameter is for one of multiple packs in an HVESS.  If there is only one pack in the system, the HVESS parameters should b...";
CM_ BO_ 2364735998 "High Voltage Energy Storage Pack 22 Data 8";
CM_ SG_ 2364735998 Hvsp22HghstCllVltgMdlNmr "HVESP22 Highest Cell Voltage Module Number: Identifies the location of the module containing SPN 16859 (HVESP22 Highest Cell Voltage).This parameter is for one of multiple packs in an HVESS. If there is only one pack in the system, the HVESS paramete...";
CM_ SG_ 2364735998 Hvsp22HghstCllVltgCllNmr "HVESP22 Highest Cell Voltage Cell Number: Identifies the location of SPN 16859 (HVESP22 Highest Cell Voltage) within SPN 16939 (HVESP22 Highest Cell Voltage Module Number).This parameter is for one of multiple packs in an HVESS. If there is only one ...";
CM_ SG_ 2364735998 Hvsp22LwstCllVltgMdlNmr "HVESP22 Lowest Cell Voltage Module Number: Identifies the location of the module containing SPN 16860 (HVESP22 Lowest Cell Voltage).This parameter is for one of multiple packs in an HVESS. If there is only one pack in the system, the HVESS parameters...";
CM_ SG_ 2364735998 Hvsp22LwstCllVltgCllNmr "HVESP22 Lowest Cell Voltage Cell Number: Identifies the location of SPN 16860 (HVESP22 Lowest Cell Voltage) within SPN 16941 (HVESP22 Lowest Cell Voltage Module Number).This parameter is for one of multiple packs in an HVESS. If there is only one pac...";
CM_ SG_ 2364735998 Hvesp22AverageCellVoltage "HVESP22 Average Cell Voltage: The average cell voltage in this High Voltage Energy Storage Pack instance.This parameter is for one of multiple packs in an HVESS.  If there is only one pack in the system, the HVESS parameters should be used. If there ...";
CM_ BO_ 2364736254 "High Voltage Energy Storage Pack 22 Data 9";
CM_ SG_ 2364736254 Hvsp22HghstCllTmprtrMdlNmr "HVESP22 Highest Cell Temperature Module Number: Identifies the location of the module containing SPN 16862 (HVESP22 Highest Cell Temperature).This parameter is for one of multiple packs in an HVESS. If there is only one pack in the system, the HVESS ...";
CM_ SG_ 2364736254 Hvsp22HghstCllTmprtrCllNmr "HVESP22 Highest Cell Temperature Cell Number: Identifies the location of SPN 16862 (HVESP22 Highest Cell Temperature) within SPN 16944 (HVESP22 Highest Cell Temperature Module Number).This parameter is for one of multiple packs in an HVESS. If there ...";
CM_ SG_ 2364736254 Hvsp22LwstCllTmprtrMdlNmr "HVESP22 Lowest Cell Temperature Module Number: Identifies the location of the module containing SPN 16863 (HVESP22 Lowest Cell Temperature).This parameter is for one of multiple packs in an HVESS. If there is only one pack in the system, the HVESS pa...";
CM_ SG_ 2364736254 Hvsp22LwstCllTmprtrCllNmr "HVESP22 Lowest Cell Temperature Cell Number: Identifies the location of SPN 16863 (HVESP22 Lowest Cell Temperature) within SPN 16946 (HVESP22 Lowest Cell Temperature Module Number).This parameter is for one of multiple packs in an HVESS. If there is ...";
CM_ SG_ 2364736254 Hvess22ThermalEventDetected "HVESS22 Thermal Event Detected: A sensor has detected the presence of a thermal event at or near High Voltage Energy Storage Pack instance.00b = No Thermal Event Detected01b = Thermal Event Detected10b = Error11b = Not availableThis parameter is for ...";
CM_ SG_ 2364736254 Hvsp22Dt9EmdddIntgrtSpprt "HVESP22 Data 9 Embedded Integrity Support: Indicates SPN 23039 (HVESP22 Data 9 CRC) and SPN 23038 (HVESP22 Data 9 Counter) are supported by the sender.00b = Embedded CRC and Counter are supported by the sender01b = Protection is provided using an ext...";
CM_ SG_ 2364736254 Hvesp22Data9Counter "HVESP22 Data 9 Counter: The message counter is used to detect situations where the transmitting ECU malfunction repeats the same frame all the time. The receiver of the information may use the counter parameter to detect this situation. The transmitt...";
CM_ SG_ 2364736254 Hvesp22Data9Crc "HVESP22 Data 9 CRC: The CRC is defined as follows: - Length: 8 bits- Polynomial: x^8+x^5+x^3+x^2+x+1- Initial Value: FFh- Input Data Reflection: Not reflected- Result Data Reflection: Not reflected- XOR value: FFh SAE makes no claim of the functional...";
CM_ BO_ 2364736510 "High Voltage Energy Storage Pack 22 Data 10";
CM_ SG_ 2364736510 Hvsp22HghstCllSttOfChrgMdlNmr "HVESP22 Highest Cell State of Charge Module Number: Identifies the location of the module containing SPN 16872 (HVESP22 Highest Cell State of Charge).This parameter is for one of multiple packs in an HVESS. If there is only one pack in the system, th...";
CM_ SG_ 2364736510 Hvsp22HghstCllSttOfChrgCllNmr "HVESP22 Highest Cell State of Charge Cell Number: Identifies the location of SPN 16872 (HVESP22 Highest Cell State of Charge) within SPN 16948 (HVESP22 Highest Cell State of Charge Module Number).This parameter is for one of multiple packs in an HVES...";
CM_ SG_ 2364736510 Hvsp22LwstCllSttOfChrgMdlNmr "HVESP22 Lowest Cell State of Charge Module Number: Identifies the location of the module containing SPN 16871 (HVESP22 Lowest Cell State of Charge).This parameter is for one of multiple packs in an HVESS. If there is only one pack in the system, the ...";
CM_ SG_ 2364736510 Hvsp22LwstCllSttOfChrgCllNmr "HVESP22 Lowest Cell State of Charge Cell Number: Identifies the location of SPN 16871 (HVESP22 Lowest Cell State of Charge) within SPN 16950 (HVESP22 Lowest Cell State of Charge Module Number).This parameter is for one of multiple packs in an HVESS. ...";
CM_ SG_ 2364736510 Hvsp22HghVltgBsAtvIsltnTstRslts "HVESP22 High-Voltage Bus Active Isolation Test Results: The isolation resistance expressed in Ohms per Volt that resulted from the High-Voltage Bus Active Isolation Test.See SPN 16884 (HVESP22 High-Voltage Bus Active Isolation Test Status) for test s...";
CM_ SG_ 2364736510 Hvsp22HVtBsPssvIstTstRsts "HVESP22 High-Voltage Bus Passive Isolation Test Results: The isolation resistance expressed in Ohms per Volt that resulted from the High-Voltage Bus Passive Isolation Test.See SPN 16885 (HVESP22 High-Voltage Bus Passive Isolation Test Status) for tes...";
CM_ BO_ 2364736766 "High Voltage Energy Storage Pack 22 Data 11";
CM_ SG_ 2364736766 Hvsp22BsVltgNgtvTChsssGrndVltg "HVESP22 Bus Voltage Negative to Chassis Ground Voltage: Voltage difference between the most negative terminal of the HVES battery and chassis measured on the hybrid or EV system bus side (not the battery side) of any HVES contained output contactor. ...";
CM_ SG_ 2364736766 Hvsp22VltgLvlNgtvTChsssGrndVltg "HVESP22 Voltage Level Negative to Chassis Ground Voltage: Voltage difference between the most negative terminal of the HVES battery and chassis measured at the battery side of any HVES contained output contactor.  This voltage may be used for system ...";
CM_ SG_ 2364736766 Hvesp22ActualChargeRate "HVESP22 Actual Charge Rate: This signal represents the actual present charge rate of this High Voltage Energy Storage Pack instance.This parameter is for one of multiple packs in an HVESS. If there is only one pack in the system, the HVESS parameters...";
CM_ BO_ 2364737022 "High Voltage Energy Storage Pack 23 Status 2";
CM_ SG_ 2364737022 Hvsp23DshrgPwrLmtDTSttOfChrg "HVESP23 Discharge Power Limit Due to State of Charge: Indicates whether or not discharge power of this HVES instance is being limited due to state of charge.This parameter is for one of multiple packs in an HVESS.  If there is only one pack in the sy...";
CM_ SG_ 2364737022 Hvsp23DshrgPwrLmtDTBttrTmprtr "HVESP23 Discharge Power Limit Due to Battery Temperature: Indicates whether or not discharge power of this HVES instance is being limited due to battery temperature.This parameter is for one of multiple packs in an HVESS.  If there is only one pack i...";
CM_ SG_ 2364737022 Hvsp23DsPwLtDTBttDstCdt "HVESP23 Discharge Power Limit Due to Battery Diagnostic Condition: Indicates whether or not discharge power of this HVES instance is being limited due to a battery diagnostic condition.This parameter is for one of multiple packs in an HVESS.  If ther...";
CM_ SG_ 2364737022 Hvsp23DsPwLtDTBttOCVt "HVESP23 Discharge Power Limit Due to Battery or Cell Voltage: Indicates whether or not discharge power of this HVES instance is being limited due to a battery or cell voltage level.This parameter is for one of multiple packs in an HVESS.  If there is...";
CM_ SG_ 2364737022 Hvsp23DshrgPwrLmtDTBttrCrrnt "HVESP23 Discharge Power Limit Due to Battery Current: Indicates whether or not discharge power of this HVES instance is being limited due to battery current.This parameter is for one of multiple packs in an HVESS.  If there is only one pack in the sy...";
CM_ SG_ 2364737022 Hvsp23DshrgPwrLmtDTAnUndfndCs "HVESP23 Discharge Power Limit Due to an Undefined Cause: Indicates whether or not discharge power of this HVES instance is being limited due to an undefined cause.This parameter is for one of multiple packs in an HVESS.  If there is only one pack in ...";
CM_ SG_ 2364737022 Hvsp23ChrgPwrLmtDTSttOfChrg "HVESP23 Charge Power Limit Due to State of Charge: Indicates whether or not charge power of this HVES instance is being limited due to state of charge.This parameter is for one of multiple packs in an HVESS.  If there is only one pack in the system, ...";
CM_ SG_ 2364737022 Hvsp23ChrgPwrLmtDTBttrTmprtr "HVESP23 Charge Power Limit Due to Battery Temperature: Indicates whether or not charge power of this HVES instance is being limited due to battery temperature.This parameter is for one of multiple packs in an HVESS.  If there is only one pack in the ...";
CM_ SG_ 2364737022 Hvsp23CPwLtDTBttDstCdt "HVESP23 Charge Power Limit Due to Battery Diagnostic Condition: Indicates whether or not charge power of this HVES instance is being limited due to a battery diagnostic condition.This parameter is for one of multiple packs in an HVESS.  If there is o...";
CM_ SG_ 2364737022 Hvsp23ChrgPwrLmtDTBttrOrCllVltg "HVESP23 Charge Power Limit Due to Battery or Cell Voltage: Indicates whether or not charge power of this HVES instance is being limited due to a battery or cell voltage level.This parameter is for one of multiple packs in an HVESS.  If there is only ...";
CM_ SG_ 2364737022 Hvsp23ChrgPwrLmtDTBttrCrrnt "HVESP23 Charge Power Limit Due to Battery Current: Indicates whether or not charge power of this HVES instance is being limited due to battery current.This parameter is for one of multiple packs in an HVESS.  If there is only one pack in the system, ...";
CM_ SG_ 2364737022 Hvsp23ChrgPwrLmtDTAnUndfndCs "HVESP23 Charge Power Limit Due to an Undefined Cause: Indicates whether or not charge power of this HVES instance is being limited due to an undefined cause.This parameter is for one of multiple packs in an HVESS.  If there is only one pack in the sy...";
CM_ BO_ 2364737278 "High Voltage Energy Storage Pack 23 Data 1";
CM_ SG_ 2364737278 Hvesp23AvailableDischargePower "HVESP23 Available Discharge Power: The rate at which this High Voltage Energy Storage Pack instance can currently provide energy for propulsion or other uses.This parameter is for one of multiple packs in an HVESS.  If there is only one pack in the s...";
CM_ SG_ 2364737278 Hvesp23AvailableChargePower "HVESP23 Available Charge Power: The rate at which this High Voltage Energy Storage Pack instance can currently receive energy from a regenerative or recharging system.This parameter is for one of multiple packs in an HVESS.  If there is only one pack...";
CM_ SG_ 2364737278 Hvesp23VoltageLevel "HVESP23 Voltage Level: The voltage level of this High Voltage Energy Storage Pack instance. This parameter should be synchronized with SPN 16999 (HVESP23 Current) such that a realized power value can be calculated. If the HVES component physically co...";
CM_ SG_ 2364737278 Hvesp23Current "HVESP23 Current: The current in or out of this High Voltage Energy Storage Pack instance. This parameter should be synchronized with SPN 16998 (HVESP23 Voltage Level) such that a realized power value can be calculated. This parameter is defined from ...";
CM_ BO_ 2364737534 "High Voltage Energy Storage Pack 23 Data 2";
CM_ SG_ 2364737534 Hvesp23FastUpdateStateOfCharge "HVESP23 Fast Update State of Charge: Indicates this High Voltage Energy Storage Pack instance state of charge. 0% means no charge remaining, 100% means the system is fully charged in terms of physical limits of this energy storage pack instance. Acce...";
CM_ SG_ 2364737534 Hvesp23HighestCellVoltage "HVESP23 Highest Cell Voltage: The highest voltage level reported by any cell in this High Voltage Energy Storage Pack instance. If a single voltage sensor covers more than one cell, the value in this parameter is for the smallest group of cells measu...";
CM_ SG_ 2364737534 Hvesp23LowestCellVoltage "HVESP23 Lowest Cell Voltage: The lowest voltage level reported by any cell in this High Voltage Energy Storage Pack instance. If a single voltage sensor covers more than one cell, the value in this parameter is for the smallest group of cells measure...";
CM_ SG_ 2364737534 Hvsp23CllVltgDffrntlStts "HVESP23 Cell Voltage Differential Status: Indicates whether or not the differential between the highest and lowest cell voltages are within acceptable limits, according to this High Voltage Energy Storage Pack instance. The actual voltage differentia...";
CM_ BO_ 2364737790 "High Voltage Energy Storage Pack 23 Data 3";
CM_ SG_ 2364737790 Hvesp23HighestCellTemperature "HVESP23 Highest Cell Temperature: The highest temperature level reported by any cell in this High Voltage Energy Storage Pack instance. If a single temperature sensor covers more than one cell, the value in this parameter is for the smallest group of...";
CM_ SG_ 2364737790 Hvesp23LowestCellTemperature "HVESP23 Lowest Cell Temperature: The lowest temperature level reported by any cell in this High Voltage Energy Storage Pack instance. If a single temperature sensor covers more than one cell, the value in this parameter is for the smallest group of c...";
CM_ SG_ 2364737790 Hvesp23AverageCellTemperature "HVESP23 Average Cell Temperature: The average temperature level of all cells in this High Voltage Energy Storage Pack instance.This parameter is for one of multiple packs in an HVESS.  If there is only one pack in the system, the HVESS parameters sho...";
CM_ SG_ 2364737790 Hvsp23CllTmprtrDffrntlStts "HVESP23 Cell Temperature Differential Status: Indicates whether or not the differential between the highest and lowest cell temperatures are within acceptable limits per this High Voltage Energy Storage Pack instance. The actual temperature different...";
CM_ BO_ 2364738046 "High Voltage Energy Storage Pack 23 Data 4";
CM_ SG_ 2364738046 Hvesp23DischargeCapacity "HVESP23 Discharge Capacity: The amount of stored electrical charge in this High Voltage Energy Storage Pack instance that is available for use by the hybrid or EV system, i.e. 'how full is the tank'. See SPN 17038 (HVESP23 Discharge Energy Capacity) ...";
CM_ SG_ 2364738046 Hvesp23ChargeCapacity "HVESP23 Charge Capacity: The amount of unused electrical charge storage in this High Voltage Energy Storage Pack instance that is available to be filled by charging, i.e. 'how much empty space is remaining in the tank'. See SPN 17039 (HVESP23 Charge ...";
CM_ SG_ 2364738046 Hvesp23CellBalancingCount "HVESP23 Cell Balancing Count: The number of cells that are currently being balanced in this High Voltage Energy Storage Pack instance.This parameter is for one of multiple packs in an HVESS.  If there is only one pack in the system, the HVESS paramet...";
CM_ BO_ 2364738302 "High Voltage Energy Storage Pack 23 Data 5";
CM_ SG_ 2364738302 Hvesp23LowestCellStateOfCharge "HVESP23 Lowest Cell State of Charge: Indicates the state of charge of the lowest-charged cell in this High Voltage Energy Storage Pack instance. 0% means no charge remaining, 100% means the cell is fully charged. If a single state of charge value cov...";
CM_ SG_ 2364738302 Hvesp23HighestCellStateOfCharge "HVESP23 Highest Cell State of Charge: Indicates the state of charge of the highest-charged cell in this High Voltage Energy Storage Pack instance. 0% means no charge remaining, 100% means the cell is fully charged. If a single state of charge value c...";
CM_ SG_ 2364738302 Hvsp23MxmmInstntnsDshrgCrrntLmt "HVESP23 Maximum Instantaneous Discharge Current Limit: The maximum instantaneous current flow limit out of this High Voltage Energy Storage Pack instance. This parameter is defined from the high voltage energy storage pack's point of view and should ...";
CM_ SG_ 2364738302 Hvsp23MxmmInstntnsChrgCrrntLmt "HVESP23 Maximum Instantaneous Charge Current Limit: The maximum instantaneous current flow limit into this High Voltage Energy Storage Pack instance. This parameter is defined from the high voltage energy storage pack's point of view and should refle...";
CM_ BO_ 2364738558 "High Voltage Energy Storage Pack 23 Data 6";
CM_ SG_ 2364738558 Hvesp23BusVoltage "HVESP23 Bus Voltage: The voltage level of the high voltage bus, as measured by this High Voltage Energy Storage Pack instance on the bus side (not the battery side) of its contactors.This parameter is for one of multiple packs in an HVESS.  If there ...";
CM_ SG_ 2364738558 Hvesp23IgnitionVoltage "HVESP23 Ignition Voltage: The voltage level at the ignition input of this High Voltage Energy Storage Pack controller.This parameter is for one of multiple packs in an HVESS.  If there is only one pack in the system, the HVESS parameters should be us...";
CM_ SG_ 2364738558 Hvesp23IntakeCoolantTemperature "HVESP23 Intake Coolant Temperature: The temperature of liquid coolant as it enters this High Voltage Energy Storage Pack instance.This parameter is for one of multiple packs in an HVESS.  If there is only one pack in the system, the HVESS parameters ...";
CM_ SG_ 2364738558 Hvesp23OutletCoolantTemperature "HVESP23 Outlet Coolant Temperature: The temperature of liquid coolant as it exits this High Voltage Energy Storage Pack instance.This parameter is for one of multiple packs in an HVESS.  If there is only one pack in the system, the HVESS parameters s...";
CM_ SG_ 2364738558 Hvesp23ElectronicsTemperature "HVESP23 Electronics Temperature: The temperature of the electronics or control modules in this High Voltage Energy Storage Pack instance.  If there are multiple temperature sensors then this parameter would be set to the maximum sensor reading.This p...";
CM_ SG_ 2364738558 Hvesp23Temperature "HVESP23 Temperature: The temperature of this High Voltage Energy Storage Pack instance. The value may be determined from a unique sensor specifically for this purpose, or by aggregating various temperature sensor readings within the pack.This paramet...";
CM_ BO_ 2364738814 "High Voltage Energy Storage Pack 23 Status 1";
CM_ SG_ 2364738814 Hvsp23HghVltgBsPstvCnttrStt "HVESP23 High-Voltage Bus (Positive) Contactor State: Position of this High Voltage Energy Storage Pack instance positive side bus contactor.  When this contactor is closed, the positive side of this HVES instance is connected to the positive side of ...";
CM_ SG_ 2364738814 Hvsp23HghVltgBsNgtvCnttrStt "HVESP23 High-Voltage Bus (Negative) Contactor State: Position of this High Voltage Energy Storage Pack instance negative side bus contactor. When this contactor is closed, the negative side of this HVES instance is connected to the negative side of t...";
CM_ SG_ 2364738814 Hvsp23HghVltgBsDsnntFrwrnng "HVESP23 High-Voltage Bus Disconnect Forewarning: Indicates that this High Voltage Energy Storage Pack instance is about to disconnect from the high voltage bus due to unacceptable conditions.This parameter is for one of multiple packs in an HVESS. If...";
CM_ SG_ 2364738814 Hvsp23HghVltgBsPrChrgRlStt "HVESP23 High-Voltage Bus Pre-Charge Relay State: Position of the high-voltage bus contactor pre-charge relay.  When this relay is closed, this High Voltage Energy Storage Pack instance is bringing the high-voltage bus up to its operating level.This p...";
CM_ SG_ 2364738814 Hvsp23CntrOfPkCnttrStt "HVESP23 Center of Pack Contactor State: Position of the center high-voltage contactor. When this contactor is closed, the positive half of this High Voltage Energy Storage Pack instance is connected to the negative half. If a system controls the posi...";
CM_ SG_ 2364738814 Hvsp23HghVltgBsAtvIsltnTstStts "HVESP23 High-Voltage Bus Active Isolation Test Status: Status of the high-voltage bus electrical active isolation test as performed by this High Voltage Energy Storage Pack instance.This parameter is for one of multiple packs in an HVESS. If there is...";
CM_ SG_ 2364738814 Hvsp23HghVltgBsPssvIsltnTstStts "HVESP23 High-Voltage Bus Passive Isolation Test Status: Status of the high-voltage bus electrical passive isolation test as performed by this High Voltage Energy Storage Pack instance.This parameter is for one of multiple packs in an HVESS. If there ...";
CM_ SG_ 2364738814 Hvesp23HvilStatus "HVESP23 HVIL Status: Status of the High Voltage Interlock Loop from the viewpoint of this High Voltage Energy Storage Pack instance.This parameter is for one of multiple packs in an HVESS. If there is only one pack in the system, the HVESS parameters...";
CM_ SG_ 2364738814 Hvesp23InertiaSwitchStatus "HVESP23 Inertia Switch Status: Switch indicating that an impact has been sensed by this High Voltage Energy Storage Pack instance. The impact indication may require action by another controller, or by this HVES instance itself.  For example, a contro...";
CM_ SG_ 2364738814 Hvesp23StateOfChargeStatus "HVESP23 State of Charge Status: Status of this High Voltage Energy Storage Pack instance State of Charge (SOC).  Note:  A given HVES controller may not support all of the states.This parameter is for one of multiple packs in an HVESS.  If there is on...";
CM_ SG_ 2364738814 Hvesp23CellBalanceStatus "HVESP23 Cell Balance Status: Indicates whether or not the cells in this High Voltage Energy Storage Pack instance are balanced.This parameter is for one of multiple packs in an HVESS.  If there is only one pack in the system, the HVESS parameters sho...";
CM_ SG_ 2364738814 Hvesp23CellBalancingActive "HVESP23 Cell Balancing Active: Indicates whether or not the cells in this High Voltage Energy Storage Pack instance are currently being balanced.This parameter is for one of multiple packs in an HVESS.  If there is only one pack in the system, the HV...";
CM_ SG_ 2364738814 Hvesp23InternalChargerStatus "HVESP23 Internal Charger Status: Indicates that the charger in this HVES instance is on.  External chargers may use the External Energy Source Connection Status (SPN 7898) and related SPs.This parameter is for one of multiple packs in an HVESS. If th...";
CM_ SG_ 2364738814 Hvsp23HghVltgBsCnntnStts "HVESP23 High-Voltage Bus Connection Status: This parameter provides high level feedback on this High Voltage Energy Storage Pack instance high voltage bus connection. For specific contactor information, see SPN 17021 (HVESP23 High-Voltage Bus (Positi...";
CM_ SG_ 2364738814 Hvesp23OperationalStatus "HVESP23 Operational Status: Provides feedback on where this High Voltage Energy Storage Pack instance is in its operating spectrum, and includes feedback in response to the Operation Consent [i.e. SPN 16979 (HVESP23 Operation Consent)] and Power Down...";
CM_ SG_ 2364738814 Hvesp23Status1Counter "HVESP23 Status 1 Counter: The message counter is used to detect situations where the transmitting ECU malfunction repeats the same frame all the time. The receiver of the information may use the counter parameter to detect this situation. The transmi...";
CM_ SG_ 2364738814 Hvesp23Status1Crc "HVESP23 Status 1 CRC: The CRC is defined as follows: - Length: 8 bits- Polynomial: x^8+x^5+x^3+x^2+x+1- Initial Value: FFh- Input Data Reflection: Not reflected- Result Data Reflection: Not reflected- XOR value: FFh SAE makes no claim of the function...";
CM_ BO_ 2364739070 "High Voltage Energy Storage Pack 23 Data 7";
CM_ SG_ 2364739070 Hvesp23DischargeEnergyCapacity "HVESP23 Discharge Energy Capacity: The amount of stored electrical energy in this High Voltage Energy Storage Pack instance that is available for use by the hybrid or EV system, i.e. 'how full is the tank'. See SPN 17008 (HVESP23 Discharge Capacity) ...";
CM_ SG_ 2364739070 Hvesp23ChargeEnergyCapacity "HVESP23 Charge Energy Capacity: The amount of unused electrical energy storage available to be filled by charging this High Voltage Energy Storage Pack instance, i.e. 'how much empty space is remaining in the tank'. See SPN 17009 (HVESP23 Charge Capa...";
CM_ SG_ 2364739070 Hvsp23MxmmChrgVltgLmt "HVESP23 Maximum Charge Voltage Limit: The maximum voltage level not to be exceeded while charging this High Voltage Energy Storage Pack instance. If this parameter is not supported, the maximum charge voltage should be limited to SPN 17107 (HVESP23 R...";
CM_ BO_ 2364739326 "High Voltage Energy Storage Pack 23 Module Status 1";
CM_ SG_ 2364739326 Hvesp23Module1OperationalStatus "HVESP23 Module 1 Operational Status: Operational Status of Module 1 in this High Voltage Energy Storage Pack Instance.  Not Operational is used when the module is initializing or not able to function (e.g. internal module level monitors have failed)....";
CM_ SG_ 2364739326 Hvesp23Module2OperationalStatus "HVESP23 Module 2 Operational Status: Operational Status of Module 2 in this High Voltage Energy Storage Pack Instance.  Not Operational is used when the module is initializing or not able to function (e.g. internal module level monitors have failed)....";
CM_ SG_ 2364739326 Hvesp23Module3OperationalStatus "HVESP23 Module 3 Operational Status: Operational Status of Module 3 in this High Voltage Energy Storage Pack Instance.  Not Operational is used when the module is initializing or not able to function (e.g. internal module level monitors have failed)....";
CM_ SG_ 2364739326 Hvesp23Module4OperationalStatus "HVESP23 Module 4 Operational Status: Operational Status of Module 4 in this High Voltage Energy Storage Pack Instance.  Not Operational is used when the module is initializing or not able to function (e.g. internal module level monitors have failed)....";
CM_ SG_ 2364739326 Hvesp23Module5OperationalStatus "HVESP23 Module 5 Operational Status: Operational Status of Module 5 in this High Voltage Energy Storage Pack Instance.  Not Operational is used when the module is initializing or not able to function (e.g. internal module level monitors have failed)....";
CM_ SG_ 2364739326 Hvesp23Module6OperationalStatus "HVESP23 Module 6 Operational Status: Operational Status of Module 6 in this High Voltage Energy Storage Pack Instance.  Not Operational is used when the module is initializing or not able to function (e.g. internal module level monitors have failed)....";
CM_ SG_ 2364739326 Hvesp23Module7OperationalStatus "HVESP23 Module 7 Operational Status: Operational Status of Module 7 in this High Voltage Energy Storage Pack Instance.  Not Operational is used when the module is initializing or not able to function (e.g. internal module level monitors have failed)....";
CM_ SG_ 2364739326 Hvesp23Module8OperationalStatus "HVESP23 Module 8 Operational Status: Operational Status of Module 8 in this High Voltage Energy Storage Pack Instance.  Not Operational is used when the module is initializing or not able to function (e.g. internal module level monitors have failed)....";
CM_ SG_ 2364739326 Hvesp23Module9OperationalStatus "HVESP23 Module 9 Operational Status: Operational Status of Module 9 in this High Voltage Energy Storage Pack Instance.  Not Operational is used when the module is initializing or not able to function (e.g. internal module level monitors have failed)....";
CM_ SG_ 2364739326 Hvsp23Mdl10OprtnlStts "HVESP23 Module 10 Operational Status: Operational Status of Module 10 in this High Voltage Energy Storage Pack Instance.  Not Operational is used when the module is initializing or not able to function (e.g. internal module level monitors have failed...";
CM_ SG_ 2364739326 Hvsp23Mdl11OprtnlStts "HVESP23 Module 11 Operational Status: Operational Status of Module 11 in this High Voltage Energy Storage Pack Instance.  Not Operational is used when the module is initializing or not able to function (e.g. internal module level monitors have failed...";
CM_ SG_ 2364739326 Hvsp23Mdl12OprtnlStts "HVESP23 Module 12 Operational Status: Operational Status of Module 12 in this High Voltage Energy Storage Pack Instance.  Not Operational is used when the module is initializing or not able to function (e.g. internal module level monitors have failed...";
CM_ SG_ 2364739326 Hvsp23Mdl13OprtnlStts "HVESP23 Module 13 Operational Status: Operational Status of Module 13 in this High Voltage Energy Storage Pack Instance.  Not Operational is used when the module is initializing or not able to function (e.g. internal module level monitors have failed...";
CM_ SG_ 2364739326 Hvsp23Mdl14OprtnlStts "HVESP23 Module 14 Operational Status: Operational Status of Module 14 in this High Voltage Energy Storage Pack Instance.  Not Operational is used when the module is initializing or not able to function (e.g. internal module level monitors have failed...";
CM_ SG_ 2364739326 Hvsp23Mdl15OprtnlStts "HVESP23 Module 15 Operational Status: Operational Status of Module 15 in this High Voltage Energy Storage Pack Instance.  Not Operational is used when the module is initializing or not able to function (e.g. internal module level monitors have failed...";
CM_ SG_ 2364739326 Hvsp23Mdl16OprtnlStts "HVESP23 Module 16 Operational Status: Operational Status of Module 16 in this High Voltage Energy Storage Pack Instance.  Not Operational is used when the module is initializing or not able to function (e.g. internal module level monitors have failed...";
CM_ SG_ 2364739326 Hvsp23Mdl17OprtnlStts "HVESP23 Module 17 Operational Status: Operational Status of Module 17 in this High Voltage Energy Storage Pack Instance.  Not Operational is used when the module is initializing or not able to function (e.g. internal module level monitors have failed...";
CM_ SG_ 2364739326 Hvsp23Mdl18OprtnlStts "HVESP23 Module 18 Operational Status: Operational Status of Module 18 in this High Voltage Energy Storage Pack Instance.  Not Operational is used when the module is initializing or not able to function (e.g. internal module level monitors have failed...";
CM_ SG_ 2364739326 Hvsp23Mdl19OprtnlStts "HVESP23 Module 19 Operational Status: Operational Status of Module 19 in this High Voltage Energy Storage Pack Instance.  Not Operational is used when the module is initializing or not able to function (e.g. internal module level monitors have failed...";
CM_ SG_ 2364739326 Hvsp23Mdl20OprtnlStts "HVESP23 Module 20 Operational Status: Operational Status of Module 20 in this High Voltage Energy Storage Pack Instance.  Not Operational is used when the module is initializing or not able to function (e.g. internal module level monitors have failed...";
CM_ SG_ 2364739326 Hvsp23Mdl21OprtnlStts "HVESP23 Module 21 Operational Status: Operational Status of Module 21 in this High Voltage Energy Storage Pack Instance.  Not Operational is used when the module is initializing or not able to function (e.g. internal module level monitors have failed...";
CM_ SG_ 2364739326 Hvsp23Mdl22OprtnlStts "HVESP23 Module 22 Operational Status: Operational Status of Module 22 in this High Voltage Energy Storage Pack Instance.  Not Operational is used when the module is initializing or not able to function (e.g. internal module level monitors have failed...";
CM_ SG_ 2364739326 Hvsp23Mdl23OprtnlStts "HVESP23 Module 23 Operational Status: Operational Status of Module 23 in this High Voltage Energy Storage Pack Instance.  Not Operational is used when the module is initializing or not able to function (e.g. internal module level monitors have failed...";
CM_ SG_ 2364739326 Hvsp23Mdl24OprtnlStts "HVESP23 Module 24 Operational Status: Operational Status of Module 24 in this High Voltage Energy Storage Pack Instance.  Not Operational is used when the module is initializing or not able to function (e.g. internal module level monitors have failed...";
CM_ SG_ 2364739326 Hvsp23Mdl25OprtnlStts "HVESP23 Module 25 Operational Status: Operational Status of Module 25 in this High Voltage Energy Storage Pack Instance.  Not Operational is used when the module is initializing or not able to function (e.g. internal module level monitors have failed...";
CM_ SG_ 2364739326 Hvsp23Mdl26OprtnlStts "HVESP23 Module 26 Operational Status: Operational Status of Module 26 in this High Voltage Energy Storage Pack Instance.  Not Operational is used when the module is initializing or not able to function (e.g. internal module level monitors have failed...";
CM_ SG_ 2364739326 Hvsp23Mdl27OprtnlStts "HVESP23 Module 27 Operational Status: Operational Status of Module 27 in this High Voltage Energy Storage Pack Instance.  Not Operational is used when the module is initializing or not able to function (e.g. internal module level monitors have failed...";
CM_ SG_ 2364739326 Hvsp23Mdl28OprtnlStts "HVESP23 Module 28 Operational Status: Operational Status of Module 28 in this High Voltage Energy Storage Pack Instance.  Not Operational is used when the module is initializing or not able to function (e.g. internal module level monitors have failed...";
CM_ SG_ 2364739326 Hvsp23Mdl29OprtnlStts "HVESP23 Module 29 Operational Status: Operational Status of Module 29 in this High Voltage Energy Storage Pack Instance.  Not Operational is used when the module is initializing or not able to function (e.g. internal module level monitors have failed...";
CM_ SG_ 2364739326 Hvsp23Mdl30OprtnlStts "HVESP23 Module 30 Operational Status: Operational Status of Module 30 in this High Voltage Energy Storage Pack Instance.  Not Operational is used when the module is initializing or not able to function (e.g. internal module level monitors have failed...";
CM_ SG_ 2364739326 Hvsp23Mdl31OprtnlStts "HVESP23 Module 31 Operational Status: Operational Status of Module 31 in this High Voltage Energy Storage Pack Instance.  Not Operational is used when the module is initializing or not able to function (e.g. internal module level monitors have failed...";
CM_ SG_ 2364739326 Hvsp23Mdl32OprtnlStts "HVESP23 Module 32 Operational Status: Operational Status of Module 32 in this High Voltage Energy Storage Pack Instance.  Not Operational is used when the module is initializing or not able to function (e.g. internal module level monitors have failed...";
CM_ BO_ 2364739582 "High Voltage Energy Storage Pack 23 Thermal Management System Status 1";
CM_ SG_ 2364739582 Hvsp23ThrmlMngmntSstmSlInptPwr "HVESP23 Thermal Management System SLI Input Power: This is the low-voltage power consumed by this HVES Thermal Management System (TMS).This parameter is for one of multiple packs in an HVESS.  If there is only one pack in the system, the HVESS parame...";
CM_ SG_ 2364739582 Hvsp23TMtSstHVtIptPw "HVESP23 Thermal Management System High-Voltage Input Power: This is the high-voltage power consumed by this HVES Thermal Management System (TMS).This parameter is for one of multiple packs in an HVESS.  If there is only one pack in the system, the HV...";
CM_ SG_ 2364739582 Hvsp23ThrmlMngmntSstmCmprssrSpd "HVESP23 Thermal Management System Compressor Speed: When this High Voltage Energy Storage Pack Thermal Management System is equipped with an active cooling system (e.g. air conditioner), this is the Compressor Speed.This parameter is for one of multi...";
CM_ SG_ 2364739582 Hvsp23ThrmlMngmntSstmRltvHmdt "HVESP23 Thermal Management System Relative Humidty: When this High Voltage Energy Storage Pack Thermal Management System is equipped with a relative humidity sensor, this is the  measured Relative Humidity.This parameter is for one of multiple packs ...";
CM_ SG_ 2364739582 Hvsp23ThrmlMngmntSstmHtrStts "HVESP23 Thermal Management System Heater Status: The state of this High Voltage Energy Storage Pack heaterThis parameter is for one of multiple packs in an HVESS.  If there is only one pack in the system, the HVESS parameters should be used. If there...";
CM_ SG_ 2364739582 Hvsp23ThrmlMngmntSstmHvlStts "HVESP23 Thermal Management System HVIL Status: In multiple HVES configurations, this is the status of the High Voltage Interlock Loop from the viewpoint of this Thermal Management System.00b = HVIL Closed01b = HVIL Open10b = Error11b = Not AvailableT...";
CM_ SG_ 2364739582 Hvsp23ThrmlMngmntSstmMd "HVESP23 Thermal Management System Mode: Indicates the operating mode of the Thermal Management System.  The heat transfer medium may be (e.g. liquid or air).  The cooling system may be fans, liquid coolant, or a combination of mediums.  The system ma...";
CM_ SG_ 2364739582 Hvsp23ThrmlMngmntSstmClntLvl "HVESP23 Thermal Management System Coolant Level: Indicates the coolant level in this HVES Thermal Management System (TMS).This parameter is for one of multiple packs in an HVESS.  If there is only one pack in the system, the HVESS parameters should b...";
CM_ BO_ 2364739838 "High Voltage Energy Storage Pack 23 Data 8";
CM_ SG_ 2364739838 Hvsp23HghstCllVltgMdlNmr "HVESP23 Highest Cell Voltage Module Number: Identifies the location of the module containing SPN 17001 (HVESP23 Highest Cell Voltage).This parameter is for one of multiple packs in an HVESS. If there is only one pack in the system, the HVESS paramete...";
CM_ SG_ 2364739838 Hvsp23HghstCllVltgCllNmr "HVESP23 Highest Cell Voltage Cell Number: Identifies the location of SPN 17001 (HVESP23 Highest Cell Voltage) within SPN 17081 (HVESP23 Highest Cell Voltage Module Number).This parameter is for one of multiple packs in an HVESS. If there is only one ...";
CM_ SG_ 2364739838 Hvsp23LwstCllVltgMdlNmr "HVESP23 Lowest Cell Voltage Module Number: Identifies the location of the module containing SPN 17002 (HVESP23 Lowest Cell Voltage).This parameter is for one of multiple packs in an HVESS. If there is only one pack in the system, the HVESS parameters...";
CM_ SG_ 2364739838 Hvsp23LwstCllVltgCllNmr "HVESP23 Lowest Cell Voltage Cell Number: Identifies the location of SPN 17002 (HVESP23 Lowest Cell Voltage) within SPN 17083 (HVESP23 Lowest Cell Voltage Module Number).This parameter is for one of multiple packs in an HVESS. If there is only one pac...";
CM_ SG_ 2364739838 Hvesp23AverageCellVoltage "HVESP23 Average Cell Voltage: The average cell voltage in this High Voltage Energy Storage Pack instance.This parameter is for one of multiple packs in an HVESS.  If there is only one pack in the system, the HVESS parameters should be used. If there ...";
CM_ BO_ 2364740094 "High Voltage Energy Storage Pack 23 Data 9";
CM_ SG_ 2364740094 Hvsp23HghstCllTmprtrMdlNmr "HVESP23 Highest Cell Temperature Module Number: Identifies the location of the module containing SPN 17004 (HVESP23 Highest Cell Temperature).This parameter is for one of multiple packs in an HVESS. If there is only one pack in the system, the HVESS ...";
CM_ SG_ 2364740094 Hvsp23HghstCllTmprtrCllNmr "HVESP23 Highest Cell Temperature Cell Number: Identifies the location of SPN 17004 (HVESP23 Highest Cell Temperature) within SPN 17086 (HVESP23 Highest Cell Temperature Module Number).This parameter is for one of multiple packs in an HVESS. If there ...";
CM_ SG_ 2364740094 Hvsp23LwstCllTmprtrMdlNmr "HVESP23 Lowest Cell Temperature Module Number: Identifies the location of the module containing SPN 17005 (HVESP23 Lowest Cell Temperature).This parameter is for one of multiple packs in an HVESS. If there is only one pack in the system, the HVESS pa...";
CM_ SG_ 2364740094 Hvsp23LwstCllTmprtrCllNmr "HVESP23 Lowest Cell Temperature Cell Number: Identifies the location of SPN 17005 (HVESP23 Lowest Cell Temperature) within SPN 17088 (HVESP23 Lowest Cell Temperature Module Number).This parameter is for one of multiple packs in an HVESS. If there is ...";
CM_ SG_ 2364740094 Hvess23ThermalEventDetected "HVESS23 Thermal Event Detected: A sensor has detected the presence of a thermal event at or near High Voltage Energy Storage Pack instance.00b = No Thermal Event Detected01b = Thermal Event Detected10b = Error11b = Not availableThis parameter is for ...";
CM_ SG_ 2364740094 Hvsp23Dt9EmdddIntgrtSpprt "HVESP23 Data 9 Embedded Integrity Support: Indicates SPN 23042 (HVESP23 Data 9 CRC) and SPN 23041 (HVESP23 Data 9 Counter) are supported by the sender.00b = Embedded CRC and Counter are supported by the sender01b = Protection is provided using an ext...";
CM_ SG_ 2364740094 Hvesp23Data9Counter "HVESP23 Data 9 Counter: The message counter is used to detect situations where the transmitting ECU malfunction repeats the same frame all the time. The receiver of the information may use the counter parameter to detect this situation. The transmitt...";
CM_ SG_ 2364740094 Hvesp23Data9Crc "HVESP23 Data 9 CRC: The CRC is defined as follows: - Length: 8 bits- Polynomial: x^8+x^5+x^3+x^2+x+1- Initial Value: FFh- Input Data Reflection: Not reflected- Result Data Reflection: Not reflected- XOR value: FFh SAE makes no claim of the functional...";
CM_ BO_ 2364740350 "High Voltage Energy Storage Pack 23 Data 10";
CM_ SG_ 2364740350 Hvsp23HghstCllSttOfChrgMdlNmr "HVESP23 Highest Cell State of Charge Module Number: Identifies the location of the module containing SPN 17014 (HVESP23 Highest Cell State of Charge).This parameter is for one of multiple packs in an HVESS. If there is only one pack in the system, th...";
CM_ SG_ 2364740350 Hvsp23HghstCllSttOfChrgCllNmr "HVESP23 Highest Cell State of Charge Cell Number: Identifies the location of SPN 17014 (HVESP23 Highest Cell State of Charge) within SPN 17090 (HVESP23 Highest Cell State of Charge Module Number).This parameter is for one of multiple packs in an HVES...";
CM_ SG_ 2364740350 Hvsp23LwstCllSttOfChrgMdlNmr "HVESP23 Lowest Cell State of Charge Module Number: Identifies the location of the module containing SPN 17013 (HVESP23 Lowest Cell State of Charge).This parameter is for one of multiple packs in an HVESS. If there is only one pack in the system, the ...";
CM_ SG_ 2364740350 Hvsp23LwstCllSttOfChrgCllNmr "HVESP23 Lowest Cell State of Charge Cell Number: Identifies the location of SPN 17013 (HVESP23 Lowest Cell State of Charge) within SPN 17092 (HVESP23 Lowest Cell State of Charge Module Number).This parameter is for one of multiple packs in an HVESS. ...";
CM_ SG_ 2364740350 Hvsp23HghVltgBsAtvIsltnTstRslts "HVESP23 High-Voltage Bus Active Isolation Test Results: The isolation resistance expressed in Ohms per Volt that resulted from the High-Voltage Bus Active Isolation Test.See SPN 17026 (HVESP23 High-Voltage Bus Active Isolation Test Status) for test s...";
CM_ SG_ 2364740350 Hvsp23HVtBsPssvIstTstRsts "HVESP23 High-Voltage Bus Passive Isolation Test Results: The isolation resistance expressed in Ohms per Volt that resulted from the High-Voltage Bus Passive Isolation Test.See SPN 17027 (HVESP23 High-Voltage Bus Passive Isolation Test Status) for tes...";
CM_ BO_ 2364740606 "High Voltage Energy Storage Pack 23 Data 11";
CM_ SG_ 2364740606 Hvsp23BsVltgNgtvTChsssGrndVltg "HVESP23 Bus Voltage Negative to Chassis Ground Voltage: Voltage difference between the most negative terminal of the HVES battery and chassis measured on the hybrid or EV system bus side (not the battery side) of any HVES contained output contactor. ...";
CM_ SG_ 2364740606 Hvsp23VltgLvlNgtvTChsssGrndVltg "HVESP23 Voltage Level Negative to Chassis Ground Voltage: Voltage difference between the most negative terminal of the HVES battery and chassis measured at the battery side of any HVES contained output contactor.  This voltage may be used for system ...";
CM_ SG_ 2364740606 Hvesp23ActualChargeRate "HVESP23 Actual Charge Rate: This signal represents the actual present charge rate of this High Voltage Energy Storage Pack instance.This parameter is for one of multiple packs in an HVESS. If there is only one pack in the system, the HVESS parameters...";
CM_ BO_ 2364740862 "High Voltage Energy Storage Pack 24 Status 2";
CM_ SG_ 2364740862 Hvsp24DshrgPwrLmtDTSttOfChrg "HVESP24 Discharge Power Limit Due to State of Charge: Indicates whether or not discharge power of this HVES instance is being limited due to state of charge.This parameter is for one of multiple packs in an HVESS.  If there is only one pack in the sy...";
CM_ SG_ 2364740862 Hvsp24DshrgPwrLmtDTBttrTmprtr "HVESP24 Discharge Power Limit Due to Battery Temperature: Indicates whether or not discharge power of this HVES instance is being limited due to battery temperature.This parameter is for one of multiple packs in an HVESS.  If there is only one pack i...";
CM_ SG_ 2364740862 Hvsp24DsPwLtDTBttDstCdt "HVESP24 Discharge Power Limit Due to Battery Diagnostic Condition: Indicates whether or not discharge power of this HVES instance is being limited due to a battery diagnostic condition.This parameter is for one of multiple packs in an HVESS.  If ther...";
CM_ SG_ 2364740862 Hvsp24DsPwLtDTBttOCVt "HVESP24 Discharge Power Limit Due to Battery or Cell Voltage: Indicates whether or not discharge power of this HVES instance is being limited due to a battery or cell voltage level.This parameter is for one of multiple packs in an HVESS.  If there is...";
CM_ SG_ 2364740862 Hvsp24DshrgPwrLmtDTBttrCrrnt "HVESP24 Discharge Power Limit Due to Battery Current: Indicates whether or not discharge power of this HVES instance is being limited due to battery current.This parameter is for one of multiple packs in an HVESS.  If there is only one pack in the sy...";
CM_ SG_ 2364740862 Hvsp24DshrgPwrLmtDTAnUndfndCs "HVESP24 Discharge Power Limit Due to an Undefined Cause: Indicates whether or not discharge power of this HVES instance is being limited due to an undefined cause.This parameter is for one of multiple packs in an HVESS.  If there is only one pack in ...";
CM_ SG_ 2364740862 Hvsp24ChrgPwrLmtDTSttOfChrg "HVESP24 Charge Power Limit Due to State of Charge: Indicates whether or not charge power of this HVES instance is being limited due to state of charge.This parameter is for one of multiple packs in an HVESS.  If there is only one pack in the system, ...";
CM_ SG_ 2364740862 Hvsp24ChrgPwrLmtDTBttrTmprtr "HVESP24 Charge Power Limit Due to Battery Temperature: Indicates whether or not charge power of this HVES instance is being limited due to battery temperature.This parameter is for one of multiple packs in an HVESS.  If there is only one pack in the ...";
CM_ SG_ 2364740862 Hvsp24CPwLtDTBttDstCdt "HVESP24 Charge Power Limit Due to Battery Diagnostic Condition: Indicates whether or not charge power of this HVES instance is being limited due to a battery diagnostic condition.This parameter is for one of multiple packs in an HVESS.  If there is o...";
CM_ SG_ 2364740862 Hvsp24ChrgPwrLmtDTBttrOrCllVltg "HVESP24 Charge Power Limit Due to Battery or Cell Voltage: Indicates whether or not charge power of this HVES instance is being limited due to a battery or cell voltage level.This parameter is for one of multiple packs in an HVESS.  If there is only ...";
CM_ SG_ 2364740862 Hvsp24ChrgPwrLmtDTBttrCrrnt "HVESP24 Charge Power Limit Due to Battery Current: Indicates whether or not charge power of this HVES instance is being limited due to battery current.This parameter is for one of multiple packs in an HVESS.  If there is only one pack in the system, ...";
CM_ SG_ 2364740862 Hvsp24ChrgPwrLmtDTAnUndfndCs "HVESP24 Charge Power Limit Due to an Undefined Cause: Indicates whether or not charge power of this HVES instance is being limited due to an undefined cause.This parameter is for one of multiple packs in an HVESS.  If there is only one pack in the sy...";
CM_ BO_ 2364741118 "High Voltage Energy Storage Pack 24 Data 1";
CM_ SG_ 2364741118 Hvesp24AvailableDischargePower "HVESP24 Available Discharge Power: The rate at which this High Voltage Energy Storage Pack instance can currently provide energy for propulsion or other uses.This parameter is for one of multiple packs in an HVESS.  If there is only one pack in the s...";
CM_ SG_ 2364741118 Hvesp24AvailableChargePower "HVESP24 Available Charge Power: The rate at which this High Voltage Energy Storage Pack instance can currently receive energy from a regenerative or recharging system.This parameter is for one of multiple packs in an HVESS.  If there is only one pack...";
CM_ SG_ 2364741118 Hvesp24VoltageLevel "HVESP24 Voltage Level: The voltage level of this High Voltage Energy Storage Pack instance. This parameter should be synchronized with SPN 17141 (HVESP24 Current) such that a realized power value can be calculated. If the HVES component physically co...";
CM_ SG_ 2364741118 Hvesp24Current "HVESP24 Current: The current in or out of this High Voltage Energy Storage Pack instance. This parameter should be synchronized with SPN 17140 (HVESP24 Voltage Level) such that a realized power value can be calculated. This parameter is defined from ...";
CM_ BO_ 2364741374 "High Voltage Energy Storage Pack 24 Data 2";
CM_ SG_ 2364741374 Hvesp24FastUpdateStateOfCharge "HVESP24 Fast Update State of Charge: Indicates this High Voltage Energy Storage Pack instance state of charge. 0% means no charge remaining, 100% means the system is fully charged in terms of physical limits of this energy storage pack instance. Acce...";
CM_ SG_ 2364741374 Hvesp24HighestCellVoltage "HVESP24 Highest Cell Voltage: The highest voltage level reported by any cell in this High Voltage Energy Storage Pack instance. If a single voltage sensor covers more than one cell, the value in this parameter is for the smallest group of cells measu...";
CM_ SG_ 2364741374 Hvesp24LowestCellVoltage "HVESP24 Lowest Cell Voltage: The lowest voltage level reported by any cell in this High Voltage Energy Storage Pack instance. If a single voltage sensor covers more than one cell, the value in this parameter is for the smallest group of cells measure...";
CM_ SG_ 2364741374 Hvsp24CllVltgDffrntlStts "HVESP24 Cell Voltage Differential Status: Indicates whether or not the differential between the highest and lowest cell voltages are within acceptable limits, according to this High Voltage Energy Storage Pack instance. The actual voltage differentia...";
CM_ BO_ 2364741630 "High Voltage Energy Storage Pack 24 Data 3";
CM_ SG_ 2364741630 Hvesp24HighestCellTemperature "HVESP24 Highest Cell Temperature: The highest temperature level reported by any cell in this High Voltage Energy Storage Pack instance. If a single temperature sensor covers more than one cell, the value in this parameter is for the smallest group of...";
CM_ SG_ 2364741630 Hvesp24LowestCellTemperature "HVESP24 Lowest Cell Temperature: The lowest temperature level reported by any cell in this High Voltage Energy Storage Pack instance. If a single temperature sensor covers more than one cell, the value in this parameter is for the smallest group of c...";
CM_ SG_ 2364741630 Hvesp24AverageCellTemperature "HVESP24 Average Cell Temperature: The average temperature level of all cells in this High Voltage Energy Storage Pack instance.This parameter is for one of multiple packs in an HVESS.  If there is only one pack in the system, the HVESS parameters sho...";
CM_ SG_ 2364741630 Hvsp24CllTmprtrDffrntlStts "HVESP24 Cell Temperature Differential Status: Indicates whether or not the differential between the highest and lowest cell temperatures are within acceptable limits per this High Voltage Energy Storage Pack instance. The actual temperature different...";
CM_ BO_ 2364741886 "High Voltage Energy Storage Pack 24 Data 4";
CM_ SG_ 2364741886 Hvesp24DischargeCapacity "HVESP24 Discharge Capacity: The amount of stored electrical charge in this High Voltage Energy Storage Pack instance that is available for use by the hybrid or EV system, i.e. 'how full is the tank'. See SPN 17180 (HVESP24 Discharge Energy Capacity) ...";
CM_ SG_ 2364741886 Hvesp24ChargeCapacity "HVESP24 Charge Capacity: The amount of unused electrical charge storage in this High Voltage Energy Storage Pack instance that is available to be filled by charging, i.e. 'how much empty space is remaining in the tank'. See SPN 17181 (HVESP24 Charge ...";
CM_ SG_ 2364741886 Hvesp24CellBalancingCount "HVESP24 Cell Balancing Count: The number of cells that are currently being balanced in this High Voltage Energy Storage Pack instance.This parameter is for one of multiple packs in an HVESS.  If there is only one pack in the system, the HVESS paramet...";
CM_ BO_ 2364742142 "High Voltage Energy Storage Pack 24 Data 5";
CM_ SG_ 2364742142 Hvesp24LowestCellStateOfCharge "HVESP24 Lowest Cell State of Charge: Indicates the state of charge of the lowest-charged cell in this High Voltage Energy Storage Pack instance. 0% means no charge remaining, 100% means the cell is fully charged. If a single state of charge value cov...";
CM_ SG_ 2364742142 Hvesp24HighestCellStateOfCharge "HVESP24 Highest Cell State of Charge: Indicates the state of charge of the highest-charged cell in this High Voltage Energy Storage Pack instance. 0% means no charge remaining, 100% means the cell is fully charged. If a single state of charge value c...";
CM_ SG_ 2364742142 Hvsp24MxmmInstntnsDshrgCrrntLmt "HVESP24 Maximum Instantaneous Discharge Current Limit: The maximum instantaneous current flow limit out of this High Voltage Energy Storage Pack instance. This parameter is defined from the high voltage energy storage pack's point of view and should ...";
CM_ SG_ 2364742142 Hvsp24MxmmInstntnsChrgCrrntLmt "HVESP24 Maximum Instantaneous Charge Current Limit: The maximum instantaneous current flow limit into this High Voltage Energy Storage Pack instance. This parameter is defined from the high voltage energy storage pack's point of view and should refle...";
CM_ BO_ 2364742398 "High Voltage Energy Storage Pack 24 Data 6";
CM_ SG_ 2364742398 Hvesp24BusVoltage "HVESP24 Bus Voltage: The voltage level of the high voltage bus, as measured by this High Voltage Energy Storage Pack instance on the bus side (not the battery side) of its contactors.This parameter is for one of multiple packs in an HVESS.  If there ...";
CM_ SG_ 2364742398 Hvesp24IgnitionVoltage "HVESP24 Ignition Voltage: The voltage level at the ignition input of this High Voltage Energy Storage Pack controller.This parameter is for one of multiple packs in an HVESS.  If there is only one pack in the system, the HVESS parameters should be us...";
CM_ SG_ 2364742398 Hvesp24IntakeCoolantTemperature "HVESP24 Intake Coolant Temperature: The temperature of liquid coolant as it enters this High Voltage Energy Storage Pack instance.This parameter is for one of multiple packs in an HVESS.  If there is only one pack in the system, the HVESS parameters ...";
CM_ SG_ 2364742398 Hvesp24OutletCoolantTemperature "HVESP24 Outlet Coolant Temperature: The temperature of liquid coolant as it exits this High Voltage Energy Storage Pack instance.This parameter is for one of multiple packs in an HVESS.  If there is only one pack in the system, the HVESS parameters s...";
CM_ SG_ 2364742398 Hvesp24ElectronicsTemperature "HVESP24 Electronics Temperature: The temperature of the electronics or control modules in this High Voltage Energy Storage Pack instance.  If there are multiple temperature sensors then this parameter would be set to the maximum sensor reading.This p...";
CM_ SG_ 2364742398 Hvesp24Temperature "HVESP24 Temperature: The temperature of this High Voltage Energy Storage Pack instance. The value may be determined from a unique sensor specifically for this purpose, or by aggregating various temperature sensor readings within the pack.This paramet...";
CM_ BO_ 2364742654 "High Voltage Energy Storage Pack 24 Status 1";
CM_ SG_ 2364742654 Hvsp24HghVltgBsPstvCnttrStt "HVESP24 High-Voltage Bus (Positive) Contactor State: Position of this High Voltage Energy Storage Pack instance positive side bus contactor.  When this contactor is closed, the positive side of this HVES instance is connected to the positive side of ...";
CM_ SG_ 2364742654 Hvsp24HghVltgBsNgtvCnttrStt "HVESP24 High-Voltage Bus (Negative) Contactor State: Position of this High Voltage Energy Storage Pack instance negative side bus contactor. When this contactor is closed, the negative side of this HVES instance is connected to the negative side of t...";
CM_ SG_ 2364742654 Hvsp24HghVltgBsDsnntFrwrnng "HVESP24 High-Voltage Bus Disconnect Forewarning: Indicates that this High Voltage Energy Storage Pack instance is about to disconnect from the high voltage bus due to unacceptable conditions.This parameter is for one of multiple packs in an HVESS. If...";
CM_ SG_ 2364742654 Hvsp24HghVltgBsPrChrgRlStt "HVESP24 High-Voltage Bus Pre-Charge Relay State: Position of the high-voltage bus contactor pre-charge relay.  When this relay is closed, this High Voltage Energy Storage Pack instance is bringing the high-voltage bus up to its operating level.This p...";
CM_ SG_ 2364742654 Hvsp24CntrOfPkCnttrStt "HVESP24 Center of Pack Contactor State: Position of the center high-voltage contactor. When this contactor is closed, the positive half of this High Voltage Energy Storage Pack instance is connected to the negative half. If a system controls the posi...";
CM_ SG_ 2364742654 Hvsp24HghVltgBsAtvIsltnTstStts "HVESP24 High-Voltage Bus Active Isolation Test Status: Status of the high-voltage bus electrical active isolation test as performed by this High Voltage Energy Storage Pack instance.This parameter is for one of multiple packs in an HVESS. If there is...";
CM_ SG_ 2364742654 Hvsp24HghVltgBsPssvIsltnTstStts "HVESP24 High-Voltage Bus Passive Isolation Test Status: Status of the high-voltage bus electrical passive isolation test as performed by this High Voltage Energy Storage Pack instance.This parameter is for one of multiple packs in an HVESS. If there ...";
CM_ SG_ 2364742654 Hvesp24HvilStatus "HVESP24 HVIL Status: Status of the High Voltage Interlock Loop from the viewpoint of this High Voltage Energy Storage Pack instance.This parameter is for one of multiple packs in an HVESS. If there is only one pack in the system, the HVESS parameters...";
CM_ SG_ 2364742654 Hvesp24InertiaSwitchStatus "HVESP24 Inertia Switch Status: Switch indicating that an impact has been sensed by this High Voltage Energy Storage Pack instance. The impact indication may require action by another controller, or by this HVES instance itself.  For example, a contro...";
CM_ SG_ 2364742654 Hvesp24StateOfChargeStatus "HVESP24 State of Charge Status: Status of this High Voltage Energy Storage Pack instance State of Charge (SOC).  Note:  A given HVES controller may not support all of the states.This parameter is for one of multiple packs in an HVESS.  If there is on...";
CM_ SG_ 2364742654 Hvesp24CellBalanceStatus "HVESP24 Cell Balance Status: Indicates whether or not the cells in this High Voltage Energy Storage Pack instance are balanced.This parameter is for one of multiple packs in an HVESS.  If there is only one pack in the system, the HVESS parameters sho...";
CM_ SG_ 2364742654 Hvesp24CellBalancingActive "HVESP24 Cell Balancing Active: Indicates whether or not the cells in this High Voltage Energy Storage Pack instance are currently being balanced.This parameter is for one of multiple packs in an HVESS.  If there is only one pack in the system, the HV...";
CM_ SG_ 2364742654 Hvesp24InternalChargerStatus "HVESP24 Internal Charger Status: Indicates that the charger in this HVES instance is on.  External chargers may use the External Energy Source Connection Status (SPN 7898) and related SPs.This parameter is for one of multiple packs in an HVESS. If th...";
CM_ SG_ 2364742654 Hvsp24HghVltgBsCnntnStts "HVESP24 High-Voltage Bus Connection Status: This parameter provides high level feedback on this High Voltage Energy Storage Pack instance high voltage bus connection. For specific contactor information, see SPN 17163 (HVESP24 High-Voltage Bus (Positi...";
CM_ SG_ 2364742654 Hvesp24OperationalStatus "HVESP24 Operational Status: Provides feedback on where this High Voltage Energy Storage Pack instance is in its operating spectrum, and includes feedback in response to the Operation Consent [i.e. SPN 17121 (HVESP24 Operation Consent)] and Power Down...";
CM_ SG_ 2364742654 Hvesp24Status1Counter "HVESP24 Status 1 Counter: The message counter is used to detect situations where the transmitting ECU malfunction repeats the same frame all the time. The receiver of the information may use the counter parameter to detect this situation. The transmi...";
CM_ SG_ 2364742654 Hvesp24Status1Crc "HVESP24 Status 1 CRC: The CRC is defined as follows: - Length: 8 bits- Polynomial: x^8+x^5+x^3+x^2+x+1- Initial Value: FFh- Input Data Reflection: Not reflected- Result Data Reflection: Not reflected- XOR value: FFh SAE makes no claim of the function...";
CM_ BO_ 2364742910 "High Voltage Energy Storage Pack 24 Data 7";
CM_ SG_ 2364742910 Hvesp24DischargeEnergyCapacity "HVESP24 Discharge Energy Capacity: The amount of stored electrical energy in this High Voltage Energy Storage Pack instance that is available for use by the hybrid or EV system, i.e. 'how full is the tank'. See SPN 17150 (HVESP24 Discharge Capacity) ...";
CM_ SG_ 2364742910 Hvesp24ChargeEnergyCapacity "HVESP24 Charge Energy Capacity: The amount of unused electrical energy storage available to be filled by charging this High Voltage Energy Storage Pack instance, i.e. 'how much empty space is remaining in the tank'. See SPN 17151 (HVESP24 Charge Capa...";
CM_ SG_ 2364742910 Hvsp24MxmmChrgVltgLmt "HVESP24 Maximum Charge Voltage Limit: The maximum voltage level not to be exceeded while charging this High Voltage Energy Storage Pack instance. If this parameter is not supported, the maximum charge voltage should be limited to SPN 17249 (HVESP24 R...";
CM_ BO_ 2364743166 "High Voltage Energy Storage Pack 24 Module Status 1";
CM_ SG_ 2364743166 Hvesp24Module1OperationalStatus "HVESP24 Module 1 Operational Status: Operational Status of Module 1 in this High Voltage Energy Storage Pack Instance.  Not Operational is used when the module is initializing or not able to function (e.g. internal module level monitors have failed)....";
CM_ SG_ 2364743166 Hvesp24Module2OperationalStatus "HVESP24 Module 2 Operational Status: Operational Status of Module 2 in this High Voltage Energy Storage Pack Instance.  Not Operational is used when the module is initializing or not able to function (e.g. internal module level monitors have failed)....";
CM_ SG_ 2364743166 Hvesp24Module3OperationalStatus "HVESP24 Module 3 Operational Status: Operational Status of Module 3 in this High Voltage Energy Storage Pack Instance.  Not Operational is used when the module is initializing or not able to function (e.g. internal module level monitors have failed)....";
CM_ SG_ 2364743166 Hvesp24Module4OperationalStatus "HVESP24 Module 4 Operational Status: Operational Status of Module 4 in this High Voltage Energy Storage Pack Instance.  Not Operational is used when the module is initializing or not able to function (e.g. internal module level monitors have failed)....";
CM_ SG_ 2364743166 Hvesp24Module5OperationalStatus "HVESP24 Module 5 Operational Status: Operational Status of Module 5 in this High Voltage Energy Storage Pack Instance.  Not Operational is used when the module is initializing or not able to function (e.g. internal module level monitors have failed)....";
CM_ SG_ 2364743166 Hvesp24Module6OperationalStatus "HVESP24 Module 6 Operational Status: Operational Status of Module 6 in this High Voltage Energy Storage Pack Instance.  Not Operational is used when the module is initializing or not able to function (e.g. internal module level monitors have failed)....";
CM_ SG_ 2364743166 Hvesp24Module7OperationalStatus "HVESP24 Module 7 Operational Status: Operational Status of Module 7 in this High Voltage Energy Storage Pack Instance.  Not Operational is used when the module is initializing or not able to function (e.g. internal module level monitors have failed)....";
CM_ SG_ 2364743166 Hvesp24Module8OperationalStatus "HVESP24 Module 8 Operational Status: Operational Status of Module 8 in this High Voltage Energy Storage Pack Instance.  Not Operational is used when the module is initializing or not able to function (e.g. internal module level monitors have failed)....";
CM_ SG_ 2364743166 Hvesp24Module9OperationalStatus "HVESP24 Module 9 Operational Status: Operational Status of Module 9 in this High Voltage Energy Storage Pack Instance.  Not Operational is used when the module is initializing or not able to function (e.g. internal module level monitors have failed)....";
CM_ SG_ 2364743166 Hvsp24Mdl10OprtnlStts "HVESP24 Module 10 Operational Status: Operational Status of Module 10 in this High Voltage Energy Storage Pack Instance.  Not Operational is used when the module is initializing or not able to function (e.g. internal module level monitors have failed...";
CM_ SG_ 2364743166 Hvsp24Mdl11OprtnlStts "HVESP24 Module 11 Operational Status: Operational Status of Module 11 in this High Voltage Energy Storage Pack Instance.  Not Operational is used when the module is initializing or not able to function (e.g. internal module level monitors have failed...";
CM_ SG_ 2364743166 Hvsp24Mdl12OprtnlStts "HVESP24 Module 12 Operational Status: Operational Status of Module 12 in this High Voltage Energy Storage Pack Instance.  Not Operational is used when the module is initializing or not able to function (e.g. internal module level monitors have failed...";
CM_ SG_ 2364743166 Hvsp24Mdl13OprtnlStts "HVESP24 Module 13 Operational Status: Operational Status of Module 13 in this High Voltage Energy Storage Pack Instance.  Not Operational is used when the module is initializing or not able to function (e.g. internal module level monitors have failed...";
CM_ SG_ 2364743166 Hvsp24Mdl14OprtnlStts "HVESP24 Module 14 Operational Status: Operational Status of Module 14 in this High Voltage Energy Storage Pack Instance.  Not Operational is used when the module is initializing or not able to function (e.g. internal module level monitors have failed...";
CM_ SG_ 2364743166 Hvsp24Mdl15OprtnlStts "HVESP24 Module 15 Operational Status: Operational Status of Module 15 in this High Voltage Energy Storage Pack Instance.  Not Operational is used when the module is initializing or not able to function (e.g. internal module level monitors have failed...";
CM_ SG_ 2364743166 Hvsp24Mdl16OprtnlStts "HVESP24 Module 16 Operational Status: Operational Status of Module 16 in this High Voltage Energy Storage Pack Instance.  Not Operational is used when the module is initializing or not able to function (e.g. internal module level monitors have failed...";
CM_ SG_ 2364743166 Hvsp24Mdl17OprtnlStts "HVESP24 Module 17 Operational Status: Operational Status of Module 17 in this High Voltage Energy Storage Pack Instance.  Not Operational is used when the module is initializing or not able to function (e.g. internal module level monitors have failed...";
CM_ SG_ 2364743166 Hvsp24Mdl18OprtnlStts "HVESP24 Module 18 Operational Status: Operational Status of Module 18 in this High Voltage Energy Storage Pack Instance.  Not Operational is used when the module is initializing or not able to function (e.g. internal module level monitors have failed...";
CM_ SG_ 2364743166 Hvsp24Mdl19OprtnlStts "HVESP24 Module 19 Operational Status: Operational Status of Module 19 in this High Voltage Energy Storage Pack Instance.  Not Operational is used when the module is initializing or not able to function (e.g. internal module level monitors have failed...";
CM_ SG_ 2364743166 Hvsp24Mdl20OprtnlStts "HVESP24 Module 20 Operational Status: Operational Status of Module 20 in this High Voltage Energy Storage Pack Instance.  Not Operational is used when the module is initializing or not able to function (e.g. internal module level monitors have failed...";
CM_ SG_ 2364743166 Hvsp24Mdl21OprtnlStts "HVESP24 Module 21 Operational Status: Operational Status of Module 21 in this High Voltage Energy Storage Pack Instance.  Not Operational is used when the module is initializing or not able to function (e.g. internal module level monitors have failed...";
CM_ SG_ 2364743166 Hvsp24Mdl22OprtnlStts "HVESP24 Module 22 Operational Status: Operational Status of Module 22 in this High Voltage Energy Storage Pack Instance.  Not Operational is used when the module is initializing or not able to function (e.g. internal module level monitors have failed...";
CM_ SG_ 2364743166 Hvsp24Mdl23OprtnlStts "HVESP24 Module 23 Operational Status: Operational Status of Module 23 in this High Voltage Energy Storage Pack Instance.  Not Operational is used when the module is initializing or not able to function (e.g. internal module level monitors have failed...";
CM_ SG_ 2364743166 Hvsp24Mdl24OprtnlStts "HVESP24 Module 24 Operational Status: Operational Status of Module 24 in this High Voltage Energy Storage Pack Instance.  Not Operational is used when the module is initializing or not able to function (e.g. internal module level monitors have failed...";
CM_ SG_ 2364743166 Hvsp24Mdl25OprtnlStts "HVESP24 Module 25 Operational Status: Operational Status of Module 25 in this High Voltage Energy Storage Pack Instance.  Not Operational is used when the module is initializing or not able to function (e.g. internal module level monitors have failed...";
CM_ SG_ 2364743166 Hvsp24Mdl26OprtnlStts "HVESP24 Module 26 Operational Status: Operational Status of Module 26 in this High Voltage Energy Storage Pack Instance.  Not Operational is used when the module is initializing or not able to function (e.g. internal module level monitors have failed...";
CM_ SG_ 2364743166 Hvsp24Mdl27OprtnlStts "HVESP24 Module 27 Operational Status: Operational Status of Module 27 in this High Voltage Energy Storage Pack Instance.  Not Operational is used when the module is initializing or not able to function (e.g. internal module level monitors have failed...";
CM_ SG_ 2364743166 Hvsp24Mdl28OprtnlStts "HVESP24 Module 28 Operational Status: Operational Status of Module 28 in this High Voltage Energy Storage Pack Instance.  Not Operational is used when the module is initializing or not able to function (e.g. internal module level monitors have failed...";
CM_ SG_ 2364743166 Hvsp24Mdl29OprtnlStts "HVESP24 Module 29 Operational Status: Operational Status of Module 29 in this High Voltage Energy Storage Pack Instance.  Not Operational is used when the module is initializing or not able to function (e.g. internal module level monitors have failed...";
CM_ SG_ 2364743166 Hvsp24Mdl30OprtnlStts "HVESP24 Module 30 Operational Status: Operational Status of Module 30 in this High Voltage Energy Storage Pack Instance.  Not Operational is used when the module is initializing or not able to function (e.g. internal module level monitors have failed...";
CM_ SG_ 2364743166 Hvsp24Mdl31OprtnlStts "HVESP24 Module 31 Operational Status: Operational Status of Module 31 in this High Voltage Energy Storage Pack Instance.  Not Operational is used when the module is initializing or not able to function (e.g. internal module level monitors have failed...";
CM_ SG_ 2364743166 Hvsp24Mdl32OprtnlStts "HVESP24 Module 32 Operational Status: Operational Status of Module 32 in this High Voltage Energy Storage Pack Instance.  Not Operational is used when the module is initializing or not able to function (e.g. internal module level monitors have failed...";
CM_ BO_ 2364743422 "High Voltage Energy Storage Pack 24 Thermal Management System Status 1";
CM_ SG_ 2364743422 Hvsp24ThrmlMngmntSstmSlInptPwr "HVESP24 Thermal Management System SLI Input Power: This is the low-voltage power consumed by this HVES Thermal Management System (TMS).This parameter is for one of multiple packs in an HVESS.  If there is only one pack in the system, the HVESS parame...";
CM_ SG_ 2364743422 Hvsp24TMtSstHVtIptPw "HVESP24 Thermal Management System High-Voltage Input Power: This is the high-voltage power consumed by this HVES Thermal Management System (TMS).This parameter is for one of multiple packs in an HVESS.  If there is only one pack in the system, the HV...";
CM_ SG_ 2364743422 Hvsp24ThrmlMngmntSstmCmprssrSpd "HVESP24 Thermal Management System Compressor Speed: When this High Voltage Energy Storage Pack Thermal Management System is equipped with an active cooling system (e.g. air conditioner), this is the Compressor Speed.This parameter is for one of multi...";
CM_ SG_ 2364743422 Hvsp24ThrmlMngmntSstmRltvHmdt "HVESP24 Thermal Management System Relative Humidty: When this High Voltage Energy Storage Pack Thermal Management System is equipped with a relative humidity sensor, this is the  measured Relative Humidity.This parameter is for one of multiple packs ...";
CM_ SG_ 2364743422 Hvsp24ThrmlMngmntSstmHtrStts "HVESP24 Thermal Management System Heater Status: The state of this High Voltage Energy Storage Pack heaterThis parameter is for one of multiple packs in an HVESS.  If there is only one pack in the system, the HVESS parameters should be used. If there...";
CM_ SG_ 2364743422 Hvsp24ThrmlMngmntSstmHvlStts "HVESP24 Thermal Management System HVIL Status: In multiple HVES configurations, this is the status of the High Voltage Interlock Loop from the viewpoint of this Thermal Management System.00b = HVIL Closed01b = HVIL Open10b = Error11b = Not AvailableT...";
CM_ SG_ 2364743422 Hvsp24ThrmlMngmntSstmMd "HVESP24 Thermal Management System Mode: Indicates the operating mode of the Thermal Management System.  The heat transfer medium may be (e.g. liquid or air).  The cooling system may be fans, liquid coolant, or a combination of mediums.  The system ma...";
CM_ SG_ 2364743422 Hvsp24ThrmlMngmntSstmClntLvl "HVESP24 Thermal Management System Coolant Level: Indicates the coolant level in this HVES Thermal Management System (TMS).This parameter is for one of multiple packs in an HVESS.  If there is only one pack in the system, the HVESS parameters should b...";
CM_ BO_ 2364743678 "High Voltage Energy Storage Pack 24 Data 8";
CM_ SG_ 2364743678 Hvsp24HghstCllVltgMdlNmr "HVESP24 Highest Cell Voltage Module Number: Identifies the location of the module containing SPN 17143 (HVESP24 Highest Cell Voltage).This parameter is for one of multiple packs in an HVESS. If there is only one pack in the system, the HVESS paramete...";
CM_ SG_ 2364743678 Hvsp24HghstCllVltgCllNmr "HVESP24 Highest Cell Voltage Cell Number: Identifies the location of SPN 17143 (HVESP24 Highest Cell Voltage) within SPN 17223 (HVESP24 Highest Cell Voltage Module Number).This parameter is for one of multiple packs in an HVESS. If there is only one ...";
CM_ SG_ 2364743678 Hvsp24LwstCllVltgMdlNmr "HVESP24 Lowest Cell Voltage Module Number: Identifies the location of the module containing SPN 17144 (HVESP24 Lowest Cell Voltage).This parameter is for one of multiple packs in an HVESS. If there is only one pack in the system, the HVESS parameters...";
CM_ SG_ 2364743678 Hvsp24LwstCllVltgCllNmr "HVESP24 Lowest Cell Voltage Cell Number: Identifies the location of SPN 17144 (HVESP24 Lowest Cell Voltage) within SPN 17225 (HVESP24 Lowest Cell Voltage Module Number).This parameter is for one of multiple packs in an HVESS. If there is only one pac...";
CM_ SG_ 2364743678 Hvesp24AverageCellVoltage "HVESP24 Average Cell Voltage: The average cell voltage in this High Voltage Energy Storage Pack instance.This parameter is for one of multiple packs in an HVESS.  If there is only one pack in the system, the HVESS parameters should be used. If there ...";
CM_ BO_ 2364743934 "High Voltage Energy Storage Pack 24 Data 9";
CM_ SG_ 2364743934 Hvsp24HghstCllTmprtrMdlNmr "HVESP24 Highest Cell Temperature Module Number: Identifies the location of the module containing SPN 17146 (HVESP24 Highest Cell Temperature).This parameter is for one of multiple packs in an HVESS. If there is only one pack in the system, the HVESS ...";
CM_ SG_ 2364743934 Hvsp24HghstCllTmprtrCllNmr "HVESP24 Highest Cell Temperature Cell Number: Identifies the location of SPN 17146 (HVESP24 Highest Cell Temperature) within SPN 17228 (HVESP24 Highest Cell Temperature Module Number).This parameter is for one of multiple packs in an HVESS. If there ...";
CM_ SG_ 2364743934 Hvsp24LwstCllTmprtrMdlNmr "HVESP24 Lowest Cell Temperature Module Number: Identifies the location of the module containing SPN 17147 (HVESP24 Lowest Cell Temperature).This parameter is for one of multiple packs in an HVESS. If there is only one pack in the system, the HVESS pa...";
CM_ SG_ 2364743934 Hvsp24LwstCllTmprtrCllNmr "HVESP24 Lowest Cell Temperature Cell Number: Identifies the location of SPN 17147 (HVESP24 Lowest Cell Temperature) within SPN 17230 (HVESP24 Lowest Cell Temperature Module Number).This parameter is for one of multiple packs in an HVESS. If there is ...";
CM_ SG_ 2364743934 Hvess24ThermalEventDetected "HVESS24 Thermal Event Detected: A sensor has detected the presence of a thermal event at or near High Voltage Energy Storage Pack instance.00b = No Thermal Event Detected01b = Thermal Event Detected10b = Error11b = Not availableThis parameter is for ...";
CM_ SG_ 2364743934 Hvsp24Dt9EmdddIntgrtSpprt "HVESP24 Data 9 Embedded Integrity Support: Indicates SPN 23045 (HVESP24 Data 9 CRC) and SPN 23044 (HVESP24 Data 9 Counter) are supported by the sender.00b = Embedded CRC and Counter are supported by the sender01b = Protection is provided using an ext...";
CM_ SG_ 2364743934 Hvesp24Data9Counter "HVESP24 Data 9 Counter: The message counter is used to detect situations where the transmitting ECU malfunction repeats the same frame all the time. The receiver of the information may use the counter parameter to detect this situation. The transmitt...";
CM_ SG_ 2364743934 Hvesp24Data9Crc "HVESP24 Data 9 CRC: The CRC is defined as follows: - Length: 8 bits- Polynomial: x^8+x^5+x^3+x^2+x+1- Initial Value: FFh- Input Data Reflection: Not reflected- Result Data Reflection: Not reflected- XOR value: FFh SAE makes no claim of the functional...";
CM_ BO_ 2364744190 "High Voltage Energy Storage Pack 24 Data 10";
CM_ SG_ 2364744190 Hvsp24HghstCllSttOfChrgMdlNmr "HVESP24 Highest Cell State of Charge Module Number: Identifies the location of the module containing SPN 17156 (HVESP24 Highest Cell State of Charge).This parameter is for one of multiple packs in an HVESS. If there is only one pack in the system, th...";
CM_ SG_ 2364744190 Hvsp24HghstCllSttOfChrgCllNmr "HVESP24 Highest Cell State of Charge Cell Number: Identifies the location of SPN 17156 (HVESP24 Highest Cell State of Charge) within SPN 17232 (HVESP24 Highest Cell State of Charge Module Number).This parameter is for one of multiple packs in an HVES...";
CM_ SG_ 2364744190 Hvsp24LwstCllSttOfChrgMdlNmr "HVESP24 Lowest Cell State of Charge Module Number: Identifies the location of the module containing SPN 17155 (HVESP24 Lowest Cell State of Charge).This parameter is for one of multiple packs in an HVESS. If there is only one pack in the system, the ...";
CM_ SG_ 2364744190 Hvsp24LwstCllSttOfChrgCllNmr "HVESP24 Lowest Cell State of Charge Cell Number: Identifies the location of SPN 17155 (HVESP24 Lowest Cell State of Charge) within SPN 17234 (HVESP24 Lowest Cell State of Charge Module Number).This parameter is for one of multiple packs in an HVESS. ...";
CM_ SG_ 2364744190 Hvsp24HghVltgBsAtvIsltnTstRslts "HVESP24 High-Voltage Bus Active Isolation Test Results: The isolation resistance expressed in Ohms per Volt that resulted from the High-Voltage Bus Active Isolation Test.See SPN 17168 (HVESP24 High-Voltage Bus Active Isolation Test Status) for test s...";
CM_ SG_ 2364744190 Hvsp24HVtBsPssvIstTstRsts "HVESP24 High-Voltage Bus Passive Isolation Test Results: The isolation resistance expressed in Ohms per Volt that resulted from the High-Voltage Bus Passive Isolation Test.See SPN 17169 (HVESP24 High-Voltage Bus Passive Isolation Test Status) for tes...";
CM_ BO_ 2364744446 "High Voltage Energy Storage Pack 24 Data 11";
CM_ SG_ 2364744446 Hvsp24BsVltgNgtvTChsssGrndVltg "HVESP24 Bus Voltage Negative to Chassis Ground Voltage: Voltage difference between the most negative terminal of the HVES battery and chassis measured on the hybrid or EV system bus side (not the battery side) of any HVES contained output contactor. ...";
CM_ SG_ 2364744446 Hvsp24VltgLvlNgtvTChsssGrndVltg "HVESP24 Voltage Level Negative to Chassis Ground Voltage: Voltage difference between the most negative terminal of the HVES battery and chassis measured at the battery side of any HVES contained output contactor.  This voltage may be used for system ...";
CM_ SG_ 2364744446 Hvesp24ActualChargeRate "HVESP24 Actual Charge Rate: This signal represents the actual present charge rate of this High Voltage Energy Storage Pack instance.This parameter is for one of multiple packs in an HVESS. If there is only one pack in the system, the HVESS parameters...";
CM_ BO_ 2364744702 "High Voltage Energy Storage Pack 25 Status 2";
CM_ SG_ 2364744702 Hvsp25DshrgPwrLmtDTSttOfChrg "HVESP25 Discharge Power Limit Due to State of Charge: Indicates whether or not discharge power of this HVES instance is being limited due to state of charge.This parameter is for one of multiple packs in an HVESS.  If there is only one pack in the sy...";
CM_ SG_ 2364744702 Hvsp25DshrgPwrLmtDTBttrTmprtr "HVESP25 Discharge Power Limit Due to Battery Temperature: Indicates whether or not discharge power of this HVES instance is being limited due to battery temperature.This parameter is for one of multiple packs in an HVESS.  If there is only one pack i...";
CM_ SG_ 2364744702 Hvsp25DsPwLtDTBttDstCdt "HVESP25 Discharge Power Limit Due to Battery Diagnostic Condition: Indicates whether or not discharge power of this HVES instance is being limited due to a battery diagnostic condition.This parameter is for one of multiple packs in an HVESS.  If ther...";
CM_ SG_ 2364744702 Hvsp25DsPwLtDTBttOCVt "HVESP25 Discharge Power Limit Due to Battery or Cell Voltage: Indicates whether or not discharge power of this HVES instance is being limited due to a battery or cell voltage level.This parameter is for one of multiple packs in an HVESS.  If there is...";
CM_ SG_ 2364744702 Hvsp25DshrgPwrLmtDTBttrCrrnt "HVESP25 Discharge Power Limit Due to Battery Current: Indicates whether or not discharge power of this HVES instance is being limited due to battery current.This parameter is for one of multiple packs in an HVESS.  If there is only one pack in the sy...";
CM_ SG_ 2364744702 Hvsp25DshrgPwrLmtDTAnUndfndCs "HVESP25 Discharge Power Limit Due to an Undefined Cause: Indicates whether or not discharge power of this HVES instance is being limited due to an undefined cause.This parameter is for one of multiple packs in an HVESS.  If there is only one pack in ...";
CM_ SG_ 2364744702 Hvsp25ChrgPwrLmtDTSttOfChrg "HVESP25 Charge Power Limit Due to State of Charge: Indicates whether or not charge power of this HVES instance is being limited due to state of charge.This parameter is for one of multiple packs in an HVESS.  If there is only one pack in the system, ...";
CM_ SG_ 2364744702 Hvsp25ChrgPwrLmtDTBttrTmprtr "HVESP25 Charge Power Limit Due to Battery Temperature: Indicates whether or not charge power of this HVES instance is being limited due to battery temperature.This parameter is for one of multiple packs in an HVESS.  If there is only one pack in the ...";
CM_ SG_ 2364744702 Hvsp25CPwLtDTBttDstCdt "HVESP25 Charge Power Limit Due to Battery Diagnostic Condition: Indicates whether or not charge power of this HVES instance is being limited due to a battery diagnostic condition.This parameter is for one of multiple packs in an HVESS.  If there is o...";
CM_ SG_ 2364744702 Hvsp25ChrgPwrLmtDTBttrOrCllVltg "HVESP25 Charge Power Limit Due to Battery or Cell Voltage: Indicates whether or not charge power of this HVES instance is being limited due to a battery or cell voltage level.This parameter is for one of multiple packs in an HVESS.  If there is only ...";
CM_ SG_ 2364744702 Hvsp25ChrgPwrLmtDTBttrCrrnt "HVESP25 Charge Power Limit Due to Battery Current: Indicates whether or not charge power of this HVES instance is being limited due to battery current.This parameter is for one of multiple packs in an HVESS.  If there is only one pack in the system, ...";
CM_ SG_ 2364744702 Hvsp25ChrgPwrLmtDTAnUndfndCs "HVESP25 Charge Power Limit Due to an Undefined Cause: Indicates whether or not charge power of this HVES instance is being limited due to an undefined cause.This parameter is for one of multiple packs in an HVESS.  If there is only one pack in the sy...";
CM_ BO_ 2364744958 "High Voltage Energy Storage Pack 25 Data 1";
CM_ SG_ 2364744958 Hvesp25AvailableDischargePower "HVESP25 Available Discharge Power: The rate at which this High Voltage Energy Storage Pack instance can currently provide energy for propulsion or other uses.This parameter is for one of multiple packs in an HVESS.  If there is only one pack in the s...";
CM_ SG_ 2364744958 Hvesp25AvailableChargePower "HVESP25 Available Charge Power: The rate at which this High Voltage Energy Storage Pack instance can currently receive energy from a regenerative or recharging system.This parameter is for one of multiple packs in an HVESS.  If there is only one pack...";
CM_ SG_ 2364744958 Hvesp25VoltageLevel "HVESP25 Voltage Level: The voltage level of this High Voltage Energy Storage Pack instance. This parameter should be synchronized with SPN 17283 (HVESP25 Current) such that a realized power value can be calculated. If the HVES component physically co...";
CM_ SG_ 2364744958 Hvesp25Current "HVESP25 Current: The current in or out of this High Voltage Energy Storage Pack instance. This parameter should be synchronized with SPN 17282 (HVESP25 Voltage Level) such that a realized power value can be calculated. This parameter is defined from ...";
CM_ BO_ 2364745214 "High Voltage Energy Storage Pack 25 Data 2";
CM_ SG_ 2364745214 Hvesp25FastUpdateStateOfCharge "HVESP25 Fast Update State of Charge: Indicates this High Voltage Energy Storage Pack instance state of charge. 0% means no charge remaining, 100% means the system is fully charged in terms of physical limits of this energy storage pack instance. Acce...";
CM_ SG_ 2364745214 Hvesp25HighestCellVoltage "HVESP25 Highest Cell Voltage: The highest voltage level reported by any cell in this High Voltage Energy Storage Pack instance. If a single voltage sensor covers more than one cell, the value in this parameter is for the smallest group of cells measu...";
CM_ SG_ 2364745214 Hvesp25LowestCellVoltage "HVESP25 Lowest Cell Voltage: The lowest voltage level reported by any cell in this High Voltage Energy Storage Pack instance. If a single voltage sensor covers more than one cell, the value in this parameter is for the smallest group of cells measure...";
CM_ SG_ 2364745214 Hvsp25CllVltgDffrntlStts "HVESP25 Cell Voltage Differential Status: Indicates whether or not the differential between the highest and lowest cell voltages are within acceptable limits, according to this High Voltage Energy Storage Pack instance. The actual voltage differentia...";
CM_ BO_ 2364745470 "High Voltage Energy Storage Pack 25 Data 3";
CM_ SG_ 2364745470 Hvesp25HighestCellTemperature "HVESP25 Highest Cell Temperature: The highest temperature level reported by any cell in this High Voltage Energy Storage Pack instance. If a single temperature sensor covers more than one cell, the value in this parameter is for the smallest group of...";
CM_ SG_ 2364745470 Hvesp25LowestCellTemperature "HVESP25 Lowest Cell Temperature: The lowest temperature level reported by any cell in this High Voltage Energy Storage Pack instance. If a single temperature sensor covers more than one cell, the value in this parameter is for the smallest group of c...";
CM_ SG_ 2364745470 Hvesp25AverageCellTemperature "HVESP25 Average Cell Temperature: The average temperature level of all cells in this High Voltage Energy Storage Pack instance.This parameter is for one of multiple packs in an HVESS.  If there is only one pack in the system, the HVESS parameters sho...";
CM_ SG_ 2364745470 Hvsp25CllTmprtrDffrntlStts "HVESP25 Cell Temperature Differential Status: Indicates whether or not the differential between the highest and lowest cell temperatures are within acceptable limits per this High Voltage Energy Storage Pack instance. The actual temperature different...";
CM_ BO_ 2364745726 "High Voltage Energy Storage Pack 25 Data 4";
CM_ SG_ 2364745726 Hvesp25DischargeCapacity "HVESP25 Discharge Capacity: The amount of stored electrical charge in this High Voltage Energy Storage Pack instance that is available for use by the hybrid or EV system, i.e. 'how full is the tank'. See SPN 17322 (HVESP25 Discharge Energy Capacity) ...";
CM_ SG_ 2364745726 Hvesp25ChargeCapacity "HVESP25 Charge Capacity: The amount of unused electrical charge storage in this High Voltage Energy Storage Pack instance that is available to be filled by charging, i.e. 'how much empty space is remaining in the tank'. See SPN 17323 (HVESP25 Charge ...";
CM_ SG_ 2364745726 Hvesp25CellBalancingCount "HVESP25 Cell Balancing Count: The number of cells that are currently being balanced in this High Voltage Energy Storage Pack instance.This parameter is for one of multiple packs in an HVESS.  If there is only one pack in the system, the HVESS paramet...";
CM_ BO_ 2364745982 "High Voltage Energy Storage Pack 25 Data 5";
CM_ SG_ 2364745982 Hvesp25LowestCellStateOfCharge "HVESP25 Lowest Cell State of Charge: Indicates the state of charge of the lowest-charged cell in this High Voltage Energy Storage Pack instance. 0% means no charge remaining, 100% means the cell is fully charged. If a single state of charge value cov...";
CM_ SG_ 2364745982 Hvesp25HighestCellStateOfCharge "HVESP25 Highest Cell State of Charge: Indicates the state of charge of the highest-charged cell in this High Voltage Energy Storage Pack instance. 0% means no charge remaining, 100% means the cell is fully charged. If a single state of charge value c...";
CM_ SG_ 2364745982 Hvsp25MxmmInstntnsDshrgCrrntLmt "HVESP25 Maximum Instantaneous Discharge Current Limit: The maximum instantaneous current flow limit out of this High Voltage Energy Storage Pack instance. This parameter is defined from the high voltage energy storage pack's point of view and should ...";
CM_ SG_ 2364745982 Hvsp25MxmmInstntnsChrgCrrntLmt "HVESP25 Maximum Instantaneous Charge Current Limit: The maximum instantaneous current flow limit into this High Voltage Energy Storage Pack instance. This parameter is defined from the high voltage energy storage pack's point of view and should refle...";
CM_ BO_ 2364746238 "High Voltage Energy Storage Pack 25 Data 6";
CM_ SG_ 2364746238 Hvesp25BusVoltage "HVESP25 Bus Voltage: The voltage level of the high voltage bus, as measured by this High Voltage Energy Storage Pack instance on the bus side (not the battery side) of its contactors.This parameter is for one of multiple packs in an HVESS.  If there ...";
CM_ SG_ 2364746238 Hvesp25IgnitionVoltage "HVESP25 Ignition Voltage: The voltage level at the ignition input of this High Voltage Energy Storage Pack controller.This parameter is for one of multiple packs in an HVESS.  If there is only one pack in the system, the HVESS parameters should be us...";
CM_ SG_ 2364746238 Hvesp25IntakeCoolantTemperature "HVESP25 Intake Coolant Temperature: The temperature of liquid coolant as it enters this High Voltage Energy Storage Pack instance.This parameter is for one of multiple packs in an HVESS.  If there is only one pack in the system, the HVESS parameters ...";
CM_ SG_ 2364746238 Hvesp25OutletCoolantTemperature "HVESP25 Outlet Coolant Temperature: The temperature of liquid coolant as it exits this High Voltage Energy Storage Pack instance.This parameter is for one of multiple packs in an HVESS.  If there is only one pack in the system, the HVESS parameters s...";
CM_ SG_ 2364746238 Hvesp25ElectronicsTemperature "HVESP25 Electronics Temperature: The temperature of the electronics or control modules in this High Voltage Energy Storage Pack instance.  If there are multiple temperature sensors then this parameter would be set to the maximum sensor reading.This p...";
CM_ SG_ 2364746238 Hvesp25Temperature "HVESP25 Temperature: The temperature of this High Voltage Energy Storage Pack instance. The value may be determined from a unique sensor specifically for this purpose, or by aggregating various temperature sensor readings within the pack.This paramet...";
CM_ BO_ 2364746494 "High Voltage Energy Storage Pack 25 Status 1";
CM_ SG_ 2364746494 Hvsp25HghVltgBsPstvCnttrStt "HVESP25 High-Voltage Bus (Positive) Contactor State: Position of this High Voltage Energy Storage Pack instance positive side bus contactor.  When this contactor is closed, the positive side of this HVES instance is connected to the positive side of ...";
CM_ SG_ 2364746494 Hvsp25HghVltgBsNgtvCnttrStt "HVESP25 High-Voltage Bus (Negative) Contactor State: Position of this High Voltage Energy Storage Pack instance negative side bus contactor. When this contactor is closed, the negative side of this HVES instance is connected to the negative side of t...";
CM_ SG_ 2364746494 Hvsp25HghVltgBsDsnntFrwrnng "HVESP25 High-Voltage Bus Disconnect Forewarning: Indicates that this High Voltage Energy Storage Pack instance is about to disconnect from the high voltage bus due to unacceptable conditions.This parameter is for one of multiple packs in an HVESS. If...";
CM_ SG_ 2364746494 Hvsp25HghVltgBsPrChrgRlStt "HVESP25 High-Voltage Bus Pre-Charge Relay State: Position of the high-voltage bus contactor pre-charge relay.  When this relay is closed, this High Voltage Energy Storage Pack instance is bringing the high-voltage bus up to its operating level.This p...";
CM_ SG_ 2364746494 Hvsp25CntrOfPkCnttrStt "HVESP25 Center of Pack Contactor State: Position of the center high-voltage contactor. When this contactor is closed, the positive half of this High Voltage Energy Storage Pack instance is connected to the negative half. If a system controls the posi...";
CM_ SG_ 2364746494 Hvsp25HghVltgBsAtvIsltnTstStts "HVESP25 High-Voltage Bus Active Isolation Test Status: Status of the high-voltage bus electrical active isolation test as performed by this High Voltage Energy Storage Pack instance.This parameter is for one of multiple packs in an HVESS. If there is...";
CM_ SG_ 2364746494 Hvsp25HghVltgBsPssvIsltnTstStts "HVESP25 High-Voltage Bus Passive Isolation Test Status: Status of the high-voltage bus electrical passive isolation test as performed by this High Voltage Energy Storage Pack instance.This parameter is for one of multiple packs in an HVESS. If there ...";
CM_ SG_ 2364746494 Hvesp25HvilStatus "HVESP25 HVIL Status: Status of the High Voltage Interlock Loop from the viewpoint of this High Voltage Energy Storage Pack instance.This parameter is for one of multiple packs in an HVESS. If there is only one pack in the system, the HVESS parameters...";
CM_ SG_ 2364746494 Hvesp25InertiaSwitchStatus "HVESP25 Inertia Switch Status: Switch indicating that an impact has been sensed by this High Voltage Energy Storage Pack instance. The impact indication may require action by another controller, or by this HVES instance itself.  For example, a contro...";
CM_ SG_ 2364746494 Hvesp25StateOfChargeStatus "HVESP25 State of Charge Status: Status of this High Voltage Energy Storage Pack instance State of Charge (SOC).  Note:  A given HVES controller may not support all of the states.This parameter is for one of multiple packs in an HVESS.  If there is on...";
CM_ SG_ 2364746494 Hvesp25CellBalanceStatus "HVESP25 Cell Balance Status: Indicates whether or not the cells in this High Voltage Energy Storage Pack instance are balanced.This parameter is for one of multiple packs in an HVESS.  If there is only one pack in the system, the HVESS parameters sho...";
CM_ SG_ 2364746494 Hvesp25CellBalancingActive "HVESP25 Cell Balancing Active: Indicates whether or not the cells in this High Voltage Energy Storage Pack instance are currently being balanced.This parameter is for one of multiple packs in an HVESS.  If there is only one pack in the system, the HV...";
CM_ SG_ 2364746494 Hvesp25InternalChargerStatus "HVESP25 Internal Charger Status: Indicates that the charger in this HVES instance is on.  External chargers may use the External Energy Source Connection Status (SPN 7898) and related SPs.This parameter is for one of multiple packs in an HVESS. If th...";
CM_ SG_ 2364746494 Hvsp25HghVltgBsCnntnStts "HVESP25 High-Voltage Bus Connection Status: This parameter provides high level feedback on this High Voltage Energy Storage Pack instance high voltage bus connection. For specific contactor information, see SPN 17305 (HVESP25 High-Voltage Bus (Positi...";
CM_ SG_ 2364746494 Hvesp25OperationalStatus "HVESP25 Operational Status: Provides feedback on where this High Voltage Energy Storage Pack instance is in its operating spectrum, and includes feedback in response to the Operation Consent [i.e. SPN 17263 (HVESP25 Operation Consent)] and Power Down...";
CM_ SG_ 2364746494 Hvesp25Status1Counter "HVESP25 Status 1 Counter: The message counter is used to detect situations where the transmitting ECU malfunction repeats the same frame all the time. The receiver of the information may use the counter parameter to detect this situation. The transmi...";
CM_ SG_ 2364746494 Hvesp25Status1Crc "HVESP25 Status 1 CRC: The CRC is defined as follows: - Length: 8 bits- Polynomial: x^8+x^5+x^3+x^2+x+1- Initial Value: FFh- Input Data Reflection: Not reflected- Result Data Reflection: Not reflected- XOR value: FFh SAE makes no claim of the function...";
CM_ BO_ 2364746750 "High Voltage Energy Storage Pack 25 Data 7";
CM_ SG_ 2364746750 Hvesp25DischargeEnergyCapacity "HVESP25 Discharge Energy Capacity: The amount of stored electrical energy in this High Voltage Energy Storage Pack instance that is available for use by the hybrid or EV system, i.e. 'how full is the tank'. See SPN 17292 (HVESP25 Discharge Capacity) ...";
CM_ SG_ 2364746750 Hvesp25ChargeEnergyCapacity "HVESP25 Charge Energy Capacity: The amount of unused electrical energy storage available to be filled by charging this High Voltage Energy Storage Pack instance, i.e. 'how much empty space is remaining in the tank'. See SPN 17293 (HVESP25 Charge Capa...";
CM_ SG_ 2364746750 Hvsp25MxmmChrgVltgLmt "HVESP25 Maximum Charge Voltage Limit: The maximum voltage level not to be exceeded while charging this High Voltage Energy Storage Pack instance. If this parameter is not supported, the maximum charge voltage should be limited to SPN 17391 (HVESP25 R...";
BA_DEF_ SG_  "SPN" INT 0 524287;
BA_DEF_ BO_  "VFrameFormat" ENUM  "StandardCAN","ExtendedCAN","reserved","J1939PG";
BA_DEF_DEF_  "SPN" 0;
BA_DEF_DEF_  "VFrameFormat" "J1939PG";
BA_ "SPN" SG_ 2364732414 Hvsp21HghstCllTmprtrMdlNmr 16802;
BA_ "SPN" SG_ 2364732414 Hvsp21HghstCllTmprtrCllNmr 16803;
BA_ "SPN" SG_ 2364732414 Hvsp21LwstCllTmprtrMdlNmr 16804;
BA_ "SPN" SG_ 2364732414 Hvsp21LwstCllTmprtrCllNmr 16805;
BA_ "SPN" SG_ 2364732414 Hvess21ThermalEventDetected 21308;
BA_ "SPN" SG_ 2364732414 Hvsp21Dt9EmdddIntgrtSpprt 23034;
BA_ "SPN" SG_ 2364732414 Hvesp21Data9Counter 23035;
BA_ "SPN" SG_ 2364732414 Hvesp21Data9Crc 23036;
BA_ "SPN" SG_ 2364732670 Hvsp21HghstCllSttOfChrgMdlNmr 16806;
BA_ "SPN" SG_ 2364732670 Hvsp21HghstCllSttOfChrgCllNmr 16807;
BA_ "SPN" SG_ 2364732670 Hvsp21LwstCllSttOfChrgMdlNmr 16808;
BA_ "SPN" SG_ 2364732670 Hvsp21LwstCllSttOfChrgCllNmr 16809;
BA_ "SPN" SG_ 2364732670 Hvsp21HghVltgBsAtvIsltnTstRslts 16810;
BA_ "SPN" SG_ 2364732670 Hvsp21HVtBsPssvIstTstRsts 16811;
BA_ "SPN" SG_ 2364732926 Hvsp21BsVltgNgtvTChsssGrndVltg 16812;
BA_ "SPN" SG_ 2364732926 Hvsp21VltgLvlNgtvTChsssGrndVltg 16813;
BA_ "SPN" SG_ 2364732926 Hvesp21ActualChargeRate 16814;
BA_ "SPN" SG_ 2364733182 Hvsp22DshrgPwrLmtDTSttOfChrg 16842;
BA_ "SPN" SG_ 2364733182 Hvsp22DshrgPwrLmtDTBttrTmprtr 16843;
BA_ "SPN" SG_ 2364733182 Hvsp22DsPwLtDTBttDstCdt 16844;
BA_ "SPN" SG_ 2364733182 Hvsp22DsPwLtDTBttOCVt 16845;
BA_ "SPN" SG_ 2364733182 Hvsp22DshrgPwrLmtDTBttrCrrnt 16846;
BA_ "SPN" SG_ 2364733182 Hvsp22DshrgPwrLmtDTAnUndfndCs 16847;
BA_ "SPN" SG_ 2364733182 Hvsp22ChrgPwrLmtDTSttOfChrg 16848;
BA_ "SPN" SG_ 2364733182 Hvsp22ChrgPwrLmtDTBttrTmprtr 16849;
BA_ "SPN" SG_ 2364733182 Hvsp22CPwLtDTBttDstCdt 16850;
BA_ "SPN" SG_ 2364733182 Hvsp22ChrgPwrLmtDTBttrOrCllVltg 16851;
BA_ "SPN" SG_ 2364733182 Hvsp22ChrgPwrLmtDTBttrCrrnt 16852;
BA_ "SPN" SG_ 2364733182 Hvsp22ChrgPwrLmtDTAnUndfndCs 16853;
BA_ "SPN" SG_ 2364733438 Hvesp22AvailableDischargePower 16854;
BA_ "SPN" SG_ 2364733438 Hvesp22AvailableChargePower 16855;
BA_ "SPN" SG_ 2364733438 Hvesp22VoltageLevel 16856;
BA_ "SPN" SG_ 2364733438 Hvesp22Current 16857;
BA_ "SPN" SG_ 2364733694 Hvesp22FastUpdateStateOfCharge 16858;
BA_ "SPN" SG_ 2364733694 Hvesp22HighestCellVoltage 16859;
BA_ "SPN" SG_ 2364733694 Hvesp22LowestCellVoltage 16860;
BA_ "SPN" SG_ 2364733694 Hvsp22CllVltgDffrntlStts 16861;
BA_ "SPN" SG_ 2364733950 Hvesp22HighestCellTemperature 16862;
BA_ "SPN" SG_ 2364733950 Hvesp22LowestCellTemperature 16863;
BA_ "SPN" SG_ 2364733950 Hvesp22AverageCellTemperature 16864;
BA_ "SPN" SG_ 2364733950 Hvsp22CllTmprtrDffrntlStts 16865;
BA_ "SPN" SG_ 2364734206 Hvesp22DischargeCapacity 16866;
BA_ "SPN" SG_ 2364734206 Hvesp22ChargeCapacity 16867;
BA_ "SPN" SG_ 2364734206 Hvesp22CellBalancingCount 16868;
BA_ "SPN" SG_ 2364734462 Hvesp22LowestCellStateOfCharge 16871;
BA_ "SPN" SG_ 2364734462 Hvesp22HighestCellStateOfCharge 16872;
BA_ "SPN" SG_ 2364734462 Hvsp22MxmmInstntnsDshrgCrrntLmt 16869;
BA_ "SPN" SG_ 2364734462 Hvsp22MxmmInstntnsChrgCrrntLmt 16870;
BA_ "SPN" SG_ 2364734718 Hvesp22BusVoltage 16873;
BA_ "SPN" SG_ 2364734718 Hvesp22IgnitionVoltage 16874;
BA_ "SPN" SG_ 2364734718 Hvesp22IntakeCoolantTemperature 16875;
BA_ "SPN" SG_ 2364734718 Hvesp22OutletCoolantTemperature 16876;
BA_ "SPN" SG_ 2364734718 Hvesp22ElectronicsTemperature 16877;
BA_ "SPN" SG_ 2364734718 Hvesp22Temperature 16878;
BA_ "SPN" SG_ 2364734974 Hvsp22HghVltgBsPstvCnttrStt 16879;
BA_ "SPN" SG_ 2364734974 Hvsp22HghVltgBsNgtvCnttrStt 16880;
BA_ "SPN" SG_ 2364734974 Hvsp22HghVltgBsDsnntFrwrnng 16881;
BA_ "SPN" SG_ 2364734974 Hvsp22HghVltgBsPrChrgRlStt 16882;
BA_ "SPN" SG_ 2364734974 Hvsp22CntrOfPkCnttrStt 16883;
BA_ "SPN" SG_ 2364734974 Hvsp22HghVltgBsAtvIsltnTstStts 16884;
BA_ "SPN" SG_ 2364734974 Hvsp22HghVltgBsPssvIsltnTstStts 16885;
BA_ "SPN" SG_ 2364734974 Hvesp22HvilStatus 16886;
BA_ "SPN" SG_ 2364734974 Hvesp22InertiaSwitchStatus 16887;
BA_ "SPN" SG_ 2364734974 Hvesp22StateOfChargeStatus 16888;
BA_ "SPN" SG_ 2364734974 Hvesp22CellBalanceStatus 16889;
BA_ "SPN" SG_ 2364734974 Hvesp22CellBalancingActive 16890;
BA_ "SPN" SG_ 2364734974 Hvesp22InternalChargerStatus 16891;
BA_ "SPN" SG_ 2364734974 Hvsp22HghVltgBsCnntnStts 16892;
BA_ "SPN" SG_ 2364734974 Hvesp22OperationalStatus 16893;
BA_ "SPN" SG_ 2364734974 Hvesp22Status1Counter 16894;
BA_ "SPN" SG_ 2364734974 Hvesp22Status1Crc 16895;
BA_ "SPN" SG_ 2364735230 Hvesp22DischargeEnergyCapacity 16896;
BA_ "SPN" SG_ 2364735230 Hvesp22ChargeEnergyCapacity 16897;
BA_ "SPN" SG_ 2364735230 Hvsp22MxmmChrgVltgLmt 16898;
BA_ "SPN" SG_ 2364735486 Hvesp22Module1OperationalStatus 16899;
BA_ "SPN" SG_ 2364735486 Hvesp22Module2OperationalStatus 16900;
BA_ "SPN" SG_ 2364735486 Hvesp22Module3OperationalStatus 16901;
BA_ "SPN" SG_ 2364735486 Hvesp22Module4OperationalStatus 16902;
BA_ "SPN" SG_ 2364735486 Hvesp22Module5OperationalStatus 16903;
BA_ "SPN" SG_ 2364735486 Hvesp22Module6OperationalStatus 16904;
BA_ "SPN" SG_ 2364735486 Hvesp22Module7OperationalStatus 16905;
BA_ "SPN" SG_ 2364735486 Hvesp22Module8OperationalStatus 16906;
BA_ "SPN" SG_ 2364735486 Hvesp22Module9OperationalStatus 16907;
BA_ "SPN" SG_ 2364735486 Hvsp22Mdl10OprtnlStts 16908;
BA_ "SPN" SG_ 2364735486 Hvsp22Mdl11OprtnlStts 16909;
BA_ "SPN" SG_ 2364735486 Hvsp22Mdl12OprtnlStts 16910;
BA_ "SPN" SG_ 2364735486 Hvsp22Mdl13OprtnlStts 16911;
BA_ "SPN" SG_ 2364735486 Hvsp22Mdl14OprtnlStts 16912;
BA_ "SPN" SG_ 2364735486 Hvsp22Mdl15OprtnlStts 16913;
BA_ "SPN" SG_ 2364735486 Hvsp22Mdl16OprtnlStts 16914;
BA_ "SPN" SG_ 2364735486 Hvsp22Mdl17OprtnlStts 16915;
BA_ "SPN" SG_ 2364735486 Hvsp22Mdl18OprtnlStts 16916;
BA_ "SPN" SG_ 2364735486 Hvsp22Mdl19OprtnlStts 16917;
BA_ "SPN" SG_ 2364735486 Hvsp22Mdl20OprtnlStts 16918;
BA_ "SPN" SG_ 2364735486 Hvsp22Mdl21OprtnlStts 16919;
BA_ "SPN" SG_ 2364735486 Hvsp22Mdl22OprtnlStts 16920;
BA_ "SPN" SG_ 2364735486 Hvsp22Mdl23OprtnlStts 16921;
BA_ "SPN" SG_ 2364735486 Hvsp22Mdl24OprtnlStts 16922;
BA_ "SPN" SG_ 2364735486 Hvsp22Mdl25OprtnlStts 16923;
BA_ "SPN" SG_ 2364735486 Hvsp22Mdl26OprtnlStts 16924;
BA_ "SPN" SG_ 2364735486 Hvsp22Mdl27OprtnlStts 16925;
BA_ "SPN" SG_ 2364735486 Hvsp22Mdl28OprtnlStts 16926;
BA_ "SPN" SG_ 2364735486 Hvsp22Mdl29OprtnlStts 16927;
BA_ "SPN" SG_ 2364735486 Hvsp22Mdl30OprtnlStts 16928;
BA_ "SPN" SG_ 2364735486 Hvsp22Mdl31OprtnlStts 16929;
BA_ "SPN" SG_ 2364735486 Hvsp22Mdl32OprtnlStts 16930;
BA_ "SPN" SG_ 2364735742 Hvsp22ThrmlMngmntSstmSlInptPwr 16931;
BA_ "SPN" SG_ 2364735742 Hvsp22TMtSstHVtIptPw 16932;
BA_ "SPN" SG_ 2364735742 Hvsp22ThrmlMngmntSstmCmprssrSpd 16933;
BA_ "SPN" SG_ 2364735742 Hvsp22ThrmlMngmntSstmRltvHmdt 16934;
BA_ "SPN" SG_ 2364735742 Hvsp22ThrmlMngmntSstmHtrStts 16935;
BA_ "SPN" SG_ 2364735742 Hvsp22ThrmlMngmntSstmHvlStts 16936;
BA_ "SPN" SG_ 2364735742 Hvsp22ThrmlMngmntSstmMd 16937;
BA_ "SPN" SG_ 2364735742 Hvsp22ThrmlMngmntSstmClntLvl 16938;
BA_ "SPN" SG_ 2364735998 Hvsp22HghstCllVltgMdlNmr 16939;
BA_ "SPN" SG_ 2364735998 Hvsp22HghstCllVltgCllNmr 16940;
BA_ "SPN" SG_ 2364735998 Hvsp22LwstCllVltgMdlNmr 16941;
BA_ "SPN" SG_ 2364735998 Hvsp22LwstCllVltgCllNmr 16942;
BA_ "SPN" SG_ 2364735998 Hvesp22AverageCellVoltage 16943;
BA_ "SPN" SG_ 2364736254 Hvsp22HghstCllTmprtrMdlNmr 16944;
BA_ "SPN" SG_ 2364736254 Hvsp22HghstCllTmprtrCllNmr 16945;
BA_ "SPN" SG_ 2364736254 Hvsp22LwstCllTmprtrMdlNmr 16946;
BA_ "SPN" SG_ 2364736254 Hvsp22LwstCllTmprtrCllNmr 16947;
BA_ "SPN" SG_ 2364736254 Hvess22ThermalEventDetected 21309;
BA_ "SPN" SG_ 2364736254 Hvsp22Dt9EmdddIntgrtSpprt 23037;
BA_ "SPN" SG_ 2364736254 Hvesp22Data9Counter 23038;
BA_ "SPN" SG_ 2364736254 Hvesp22Data9Crc 23039;
BA_ "SPN" SG_ 2364736510 Hvsp22HghstCllSttOfChrgMdlNmr 16948;
BA_ "SPN" SG_ 2364736510 Hvsp22HghstCllSttOfChrgCllNmr 16949;
BA_ "SPN" SG_ 2364736510 Hvsp22LwstCllSttOfChrgMdlNmr 16950;
BA_ "SPN" SG_ 2364736510 Hvsp22LwstCllSttOfChrgCllNmr 16951;
BA_ "SPN" SG_ 2364736510 Hvsp22HghVltgBsAtvIsltnTstRslts 16952;
BA_ "SPN" SG_ 2364736510 Hvsp22HVtBsPssvIstTstRsts 16953;
BA_ "SPN" SG_ 2364736766 Hvsp22BsVltgNgtvTChsssGrndVltg 16954;
BA_ "SPN" SG_ 2364736766 Hvsp22VltgLvlNgtvTChsssGrndVltg 16955;
BA_ "SPN" SG_ 2364736766 Hvesp22ActualChargeRate 16956;
BA_ "SPN" SG_ 2364737022 Hvsp23DshrgPwrLmtDTSttOfChrg 16984;
BA_ "SPN" SG_ 2364737022 Hvsp23DshrgPwrLmtDTBttrTmprtr 16985;
BA_ "SPN" SG_ 2364737022 Hvsp23DsPwLtDTBttDstCdt 16986;
BA_ "SPN" SG_ 2364737022 Hvsp23DsPwLtDTBttOCVt 16987;
BA_ "SPN" SG_ 2364737022 Hvsp23DshrgPwrLmtDTBttrCrrnt 16988;
BA_ "SPN" SG_ 2364737022 Hvsp23DshrgPwrLmtDTAnUndfndCs 16989;
BA_ "SPN" SG_ 2364737022 Hvsp23ChrgPwrLmtDTSttOfChrg 16990;
BA_ "SPN" SG_ 2364737022 Hvsp23ChrgPwrLmtDTBttrTmprtr 16991;
BA_ "SPN" SG_ 2364737022 Hvsp23CPwLtDTBttDstCdt 16992;
BA_ "SPN" SG_ 2364737022 Hvsp23ChrgPwrLmtDTBttrOrCllVltg 16993;
BA_ "SPN" SG_ 2364737022 Hvsp23ChrgPwrLmtDTBttrCrrnt 16994;
BA_ "SPN" SG_ 2364737022 Hvsp23ChrgPwrLmtDTAnUndfndCs 16995;
BA_ "SPN" SG_ 2364737278 Hvesp23AvailableDischargePower 16996;
BA_ "SPN" SG_ 2364737278 Hvesp23AvailableChargePower 16997;
BA_ "SPN" SG_ 2364737278 Hvesp23VoltageLevel 16998;
BA_ "SPN" SG_ 2364737278 Hvesp23Current 16999;
BA_ "SPN" SG_ 2364737534 Hvesp23FastUpdateStateOfCharge 17000;
BA_ "SPN" SG_ 2364737534 Hvesp23HighestCellVoltage 17001;
BA_ "SPN" SG_ 2364737534 Hvesp23LowestCellVoltage 17002;
BA_ "SPN" SG_ 2364737534 Hvsp23CllVltgDffrntlStts 17003;
BA_ "SPN" SG_ 2364737790 Hvesp23HighestCellTemperature 17004;
BA_ "SPN" SG_ 2364737790 Hvesp23LowestCellTemperature 17005;
BA_ "SPN" SG_ 2364737790 Hvesp23AverageCellTemperature 17006;
BA_ "SPN" SG_ 2364737790 Hvsp23CllTmprtrDffrntlStts 17007;
BA_ "SPN" SG_ 2364738046 Hvesp23DischargeCapacity 17008;
BA_ "SPN" SG_ 2364738046 Hvesp23ChargeCapacity 17009;
BA_ "SPN" SG_ 2364738046 Hvesp23CellBalancingCount 17010;
BA_ "SPN" SG_ 2364738302 Hvesp23LowestCellStateOfCharge 17013;
BA_ "SPN" SG_ 2364738302 Hvesp23HighestCellStateOfCharge 17014;
BA_ "SPN" SG_ 2364738302 Hvsp23MxmmInstntnsDshrgCrrntLmt 17011;
BA_ "SPN" SG_ 2364738302 Hvsp23MxmmInstntnsChrgCrrntLmt 17012;
BA_ "SPN" SG_ 2364738558 Hvesp23BusVoltage 17015;
BA_ "SPN" SG_ 2364738558 Hvesp23IgnitionVoltage 17016;
BA_ "SPN" SG_ 2364738558 Hvesp23IntakeCoolantTemperature 17017;
BA_ "SPN" SG_ 2364738558 Hvesp23OutletCoolantTemperature 17018;
BA_ "SPN" SG_ 2364738558 Hvesp23ElectronicsTemperature 17019;
BA_ "SPN" SG_ 2364738558 Hvesp23Temperature 17020;
BA_ "SPN" SG_ 2364738814 Hvsp23HghVltgBsPstvCnttrStt 17021;
BA_ "SPN" SG_ 2364738814 Hvsp23HghVltgBsNgtvCnttrStt 17022;
BA_ "SPN" SG_ 2364738814 Hvsp23HghVltgBsDsnntFrwrnng 17023;
BA_ "SPN" SG_ 2364738814 Hvsp23HghVltgBsPrChrgRlStt 17024;
BA_ "SPN" SG_ 2364738814 Hvsp23CntrOfPkCnttrStt 17025;
BA_ "SPN" SG_ 2364738814 Hvsp23HghVltgBsAtvIsltnTstStts 17026;
BA_ "SPN" SG_ 2364738814 Hvsp23HghVltgBsPssvIsltnTstStts 17027;
BA_ "SPN" SG_ 2364738814 Hvesp23HvilStatus 17028;
BA_ "SPN" SG_ 2364738814 Hvesp23InertiaSwitchStatus 17029;
BA_ "SPN" SG_ 2364738814 Hvesp23StateOfChargeStatus 17030;
BA_ "SPN" SG_ 2364738814 Hvesp23CellBalanceStatus 17031;
BA_ "SPN" SG_ 2364738814 Hvesp23CellBalancingActive 17032;
BA_ "SPN" SG_ 2364738814 Hvesp23InternalChargerStatus 17033;
BA_ "SPN" SG_ 2364738814 Hvsp23HghVltgBsCnntnStts 17034;
BA_ "SPN" SG_ 2364738814 Hvesp23OperationalStatus 17035;
BA_ "SPN" SG_ 2364738814 Hvesp23Status1Counter 17036;
BA_ "SPN" SG_ 2364738814 Hvesp23Status1Crc 17037;
BA_ "SPN" SG_ 2364739070 Hvesp23DischargeEnergyCapacity 17038;
BA_ "SPN" SG_ 2364739070 Hvesp23ChargeEnergyCapacity 17039;
BA_ "SPN" SG_ 2364739070 Hvsp23MxmmChrgVltgLmt 17040;
BA_ "SPN" SG_ 2364739326 Hvesp23Module1OperationalStatus 17041;
BA_ "SPN" SG_ 2364739326 Hvesp23Module2OperationalStatus 17042;
BA_ "SPN" SG_ 2364739326 Hvesp23Module3OperationalStatus 17043;
BA_ "SPN" SG_ 2364739326 Hvesp23Module4OperationalStatus 17044;
BA_ "SPN" SG_ 2364739326 Hvesp23Module5OperationalStatus 17045;
BA_ "SPN" SG_ 2364739326 Hvesp23Module6OperationalStatus 17046;
BA_ "SPN" SG_ 2364739326 Hvesp23Module7OperationalStatus 17047;
BA_ "SPN" SG_ 2364739326 Hvesp23Module8OperationalStatus 17048;
BA_ "SPN" SG_ 2364739326 Hvesp23Module9OperationalStatus 17049;
BA_ "SPN" SG_ 2364739326 Hvsp23Mdl10OprtnlStts 17050;
BA_ "SPN" SG_ 2364739326 Hvsp23Mdl11OprtnlStts 17051;
BA_ "SPN" SG_ 2364739326 Hvsp23Mdl12OprtnlStts 17052;
BA_ "SPN" SG_ 2364739326 Hvsp23Mdl13OprtnlStts 17053;
BA_ "SPN" SG_ 2364739326 Hvsp23Mdl14OprtnlStts 17054;
BA_ "SPN" SG_ 2364739326 Hvsp23Mdl15OprtnlStts 17055;
BA_ "SPN" SG_ 2364739326 Hvsp23Mdl16OprtnlStts 17056;
BA_ "SPN" SG_ 2364739326 Hvsp23Mdl17OprtnlStts 17057;
BA_ "SPN" SG_ 2364739326 Hvsp23Mdl18OprtnlStts 17058;
BA_ "SPN" SG_ 2364739326 Hvsp23Mdl19OprtnlStts 17059;
BA_ "SPN" SG_ 2364739326 Hvsp23Mdl20OprtnlStts 17060;
BA_ "SPN" SG_ 2364739326 Hvsp23Mdl21OprtnlStts 17061;
BA_ "SPN" SG_ 2364739326 Hvsp23Mdl22OprtnlStts 17062;
BA_ "SPN" SG_ 2364739326 Hvsp23Mdl23OprtnlStts 17063;
BA_ "SPN" SG_ 2364739326 Hvsp23Mdl24OprtnlStts 17064;
BA_ "SPN" SG_ 2364739326 Hvsp23Mdl25OprtnlStts 17065;
BA_ "SPN" SG_ 2364739326 Hvsp23Mdl26OprtnlStts 17066;
BA_ "SPN" SG_ 2364739326 Hvsp23Mdl27OprtnlStts 17067;
BA_ "SPN" SG_ 2364739326 Hvsp23Mdl28OprtnlStts 17068;
BA_ "SPN" SG_ 2364739326 Hvsp23Mdl29OprtnlStts 17069;
BA_ "SPN" SG_ 2364739326 Hvsp23Mdl30OprtnlStts 17070;
BA_ "SPN" SG_ 2364739326 Hvsp23Mdl31OprtnlStts 17071;
BA_ "SPN" SG_ 2364739326 Hvsp23Mdl32OprtnlStts 17072;
BA_ "SPN" SG_ 2364739582 Hvsp23ThrmlMngmntSstmSlInptPwr 17073;
BA_ "SPN" SG_ 2364739582 Hvsp23TMtSstHVtIptPw 17074;
BA_ "SPN" SG_ 2364739582 Hvsp23ThrmlMngmntSstmCmprssrSpd 17075;
BA_ "SPN" SG_ 2364739582 Hvsp23ThrmlMngmntSstmRltvHmdt 17076;
BA_ "SPN" SG_ 2364739582 Hvsp23ThrmlMngmntSstmHtrStts 17077;
BA_ "SPN" SG_ 2364739582 Hvsp23ThrmlMngmntSstmHvlStts 17078;
BA_ "SPN" SG_ 2364739582 Hvsp23ThrmlMngmntSstmMd 17079;
BA_ "SPN" SG_ 2364739582 Hvsp23ThrmlMngmntSstmClntLvl 17080;
BA_ "SPN" SG_ 2364739838 Hvsp23HghstCllVltgMdlNmr 17081;
BA_ "SPN" SG_ 2364739838 Hvsp23HghstCllVltgCllNmr 17082;
BA_ "SPN" SG_ 2364739838 Hvsp23LwstCllVltgMdlNmr 17083;
BA_ "SPN" SG_ 2364739838 Hvsp23LwstCllVltgCllNmr 17084;
BA_ "SPN" SG_ 2364739838 Hvesp23AverageCellVoltage 17085;
BA_ "SPN" SG_ 2364740094 Hvsp23HghstCllTmprtrMdlNmr 17086;
BA_ "SPN" SG_ 2364740094 Hvsp23HghstCllTmprtrCllNmr 17087;
BA_ "SPN" SG_ 2364740094 Hvsp23LwstCllTmprtrMdlNmr 17088;
BA_ "SPN" SG_ 2364740094 Hvsp23LwstCllTmprtrCllNmr 17089;
BA_ "SPN" SG_ 2364740094 Hvess23ThermalEventDetected 21310;
BA_ "SPN" SG_ 2364740094 Hvsp23Dt9EmdddIntgrtSpprt 23040;
BA_ "SPN" SG_ 2364740094 Hvesp23Data9Counter 23041;
BA_ "SPN" SG_ 2364740094 Hvesp23Data9Crc 23042;
BA_ "SPN" SG_ 2364740350 Hvsp23HghstCllSttOfChrgMdlNmr 17090;
BA_ "SPN" SG_ 2364740350 Hvsp23HghstCllSttOfChrgCllNmr 17091;
BA_ "SPN" SG_ 2364740350 Hvsp23LwstCllSttOfChrgMdlNmr 17092;
BA_ "SPN" SG_ 2364740350 Hvsp23LwstCllSttOfChrgCllNmr 17093;
BA_ "SPN" SG_ 2364740350 Hvsp23HghVltgBsAtvIsltnTstRslts 17094;
BA_ "SPN" SG_ 2364740350 Hvsp23HVtBsPssvIstTstRsts 17095;
BA_ "SPN" SG_ 2364740606 Hvsp23BsVltgNgtvTChsssGrndVltg 17096;
BA_ "SPN" SG_ 2364740606 Hvsp23VltgLvlNgtvTChsssGrndVltg 17097;
BA_ "SPN" SG_ 2364740606 Hvesp23ActualChargeRate 17098;
BA_ "SPN" SG_ 2364740862 Hvsp24DshrgPwrLmtDTSttOfChrg 17126;
BA_ "SPN" SG_ 2364740862 Hvsp24DshrgPwrLmtDTBttrTmprtr 17127;
BA_ "SPN" SG_ 2364740862 Hvsp24DsPwLtDTBttDstCdt 17128;
BA_ "SPN" SG_ 2364740862 Hvsp24DsPwLtDTBttOCVt 17129;
BA_ "SPN" SG_ 2364740862 Hvsp24DshrgPwrLmtDTBttrCrrnt 17130;
BA_ "SPN" SG_ 2364740862 Hvsp24DshrgPwrLmtDTAnUndfndCs 17131;
BA_ "SPN" SG_ 2364740862 Hvsp24ChrgPwrLmtDTSttOfChrg 17132;
BA_ "SPN" SG_ 2364740862 Hvsp24ChrgPwrLmtDTBttrTmprtr 17133;
BA_ "SPN" SG_ 2364740862 Hvsp24CPwLtDTBttDstCdt 17134;
BA_ "SPN" SG_ 2364740862 Hvsp24ChrgPwrLmtDTBttrOrCllVltg 17135;
BA_ "SPN" SG_ 2364740862 Hvsp24ChrgPwrLmtDTBttrCrrnt 17136;
BA_ "SPN" SG_ 2364740862 Hvsp24ChrgPwrLmtDTAnUndfndCs 17137;
BA_ "SPN" SG_ 2364741118 Hvesp24AvailableDischargePower 17138;
BA_ "SPN" SG_ 2364741118 Hvesp24AvailableChargePower 17139;
BA_ "SPN" SG_ 2364741118 Hvesp24VoltageLevel 17140;
BA_ "SPN" SG_ 2364741118 Hvesp24Current 17141;
BA_ "SPN" SG_ 2364741374 Hvesp24FastUpdateStateOfCharge 17142;
BA_ "SPN" SG_ 2364741374 Hvesp24HighestCellVoltage 17143;
BA_ "SPN" SG_ 2364741374 Hvesp24LowestCellVoltage 17144;
BA_ "SPN" SG_ 2364741374 Hvsp24CllVltgDffrntlStts 17145;
BA_ "SPN" SG_ 2364741630 Hvesp24HighestCellTemperature 17146;
BA_ "SPN" SG_ 2364741630 Hvesp24LowestCellTemperature 17147;
BA_ "SPN" SG_ 2364741630 Hvesp24AverageCellTemperature 17148;
BA_ "SPN" SG_ 2364741630 Hvsp24CllTmprtrDffrntlStts 17149;
BA_ "SPN" SG_ 2364741886 Hvesp24DischargeCapacity 17150;
BA_ "SPN" SG_ 2364741886 Hvesp24ChargeCapacity 17151;
BA_ "SPN" SG_ 2364741886 Hvesp24CellBalancingCount 17152;
BA_ "SPN" SG_ 2364742142 Hvesp24LowestCellStateOfCharge 17155;
BA_ "SPN" SG_ 2364742142 Hvesp24HighestCellStateOfCharge 17156;
BA_ "SPN" SG_ 2364742142 Hvsp24MxmmInstntnsDshrgCrrntLmt 17153;
BA_ "SPN" SG_ 2364742142 Hvsp24MxmmInstntnsChrgCrrntLmt 17154;
BA_ "SPN" SG_ 2364742398 Hvesp24BusVoltage 17157;
BA_ "SPN" SG_ 2364742398 Hvesp24IgnitionVoltage 17158;
BA_ "SPN" SG_ 2364742398 Hvesp24IntakeCoolantTemperature 17159;
BA_ "SPN" SG_ 2364742398 Hvesp24OutletCoolantTemperature 17160;
BA_ "SPN" SG_ 2364742398 Hvesp24ElectronicsTemperature 17161;
BA_ "SPN" SG_ 2364742398 Hvesp24Temperature 17162;
BA_ "SPN" SG_ 2364742654 Hvsp24HghVltgBsPstvCnttrStt 17163;
BA_ "SPN" SG_ 2364742654 Hvsp24HghVltgBsNgtvCnttrStt 17164;
BA_ "SPN" SG_ 2364742654 Hvsp24HghVltgBsDsnntFrwrnng 17165;
BA_ "SPN" SG_ 2364742654 Hvsp24HghVltgBsPrChrgRlStt 17166;
BA_ "SPN" SG_ 2364742654 Hvsp24CntrOfPkCnttrStt 17167;
BA_ "SPN" SG_ 2364742654 Hvsp24HghVltgBsAtvIsltnTstStts 17168;
BA_ "SPN" SG_ 2364742654 Hvsp24HghVltgBsPssvIsltnTstStts 17169;
BA_ "SPN" SG_ 2364742654 Hvesp24HvilStatus 17170;
BA_ "SPN" SG_ 2364742654 Hvesp24InertiaSwitchStatus 17171;
BA_ "SPN" SG_ 2364742654 Hvesp24StateOfChargeStatus 17172;
BA_ "SPN" SG_ 2364742654 Hvesp24CellBalanceStatus 17173;
BA_ "SPN" SG_ 2364742654 Hvesp24CellBalancingActive 17174;
BA_ "SPN" SG_ 2364742654 Hvesp24InternalChargerStatus 17175;
BA_ "SPN" SG_ 2364742654 Hvsp24HghVltgBsCnntnStts 17176;
BA_ "SPN" SG_ 2364742654 Hvesp24OperationalStatus 17177;
BA_ "SPN" SG_ 2364742654 Hvesp24Status1Counter 17178;
BA_ "SPN" SG_ 2364742654 Hvesp24Status1Crc 17179;
BA_ "SPN" SG_ 2364742910 Hvesp24DischargeEnergyCapacity 17180;
BA_ "SPN" SG_ 2364742910 Hvesp24ChargeEnergyCapacity 17181;
BA_ "SPN" SG_ 2364742910 Hvsp24MxmmChrgVltgLmt 17182;
BA_ "SPN" SG_ 2364743166 Hvesp24Module1OperationalStatus 17183;
BA_ "SPN" SG_ 2364743166 Hvesp24Module2OperationalStatus 17184;
BA_ "SPN" SG_ 2364743166 Hvesp24Module3OperationalStatus 17185;
BA_ "SPN" SG_ 2364743166 Hvesp24Module4OperationalStatus 17186;
BA_ "SPN" SG_ 2364743166 Hvesp24Module5OperationalStatus 17187;
BA_ "SPN" SG_ 2364743166 Hvesp24Module6OperationalStatus 17188;
BA_ "SPN" SG_ 2364743166 Hvesp24Module7OperationalStatus 17189;
BA_ "SPN" SG_ 2364743166 Hvesp24Module8OperationalStatus 17190;
BA_ "SPN" SG_ 2364743166 Hvesp24Module9OperationalStatus 17191;
BA_ "SPN" SG_ 2364743166 Hvsp24Mdl10OprtnlStts 17192;
BA_ "SPN" SG_ 2364743166 Hvsp24Mdl11OprtnlStts 17193;
BA_ "SPN" SG_ 2364743166 Hvsp24Mdl12OprtnlStts 17194;
BA_ "SPN" SG_ 2364743166 Hvsp24Mdl13OprtnlStts 17195;
BA_ "SPN" SG_ 2364743166 Hvsp24Mdl14OprtnlStts 17196;
BA_ "SPN" SG_ 2364743166 Hvsp24Mdl15OprtnlStts 17197;
BA_ "SPN" SG_ 2364743166 Hvsp24Mdl16OprtnlStts 17198;
BA_ "SPN" SG_ 2364743166 Hvsp24Mdl17OprtnlStts 17199;
BA_ "SPN" SG_ 2364743166 Hvsp24Mdl18OprtnlStts 17200;
BA_ "SPN" SG_ 2364743166 Hvsp24Mdl19OprtnlStts 17201;
BA_ "SPN" SG_ 2364743166 Hvsp24Mdl20OprtnlStts 17202;
BA_ "SPN" SG_ 2364743166 Hvsp24Mdl21OprtnlStts 17203;
BA_ "SPN" SG_ 2364743166 Hvsp24Mdl22OprtnlStts 17204;
BA_ "SPN" SG_ 2364743166 Hvsp24Mdl23OprtnlStts 17205;
BA_ "SPN" SG_ 2364743166 Hvsp24Mdl24OprtnlStts 17206;
BA_ "SPN" SG_ 2364743166 Hvsp24Mdl25OprtnlStts 17207;
BA_ "SPN" SG_ 2364743166 Hvsp24Mdl26OprtnlStts 17208;
BA_ "SPN" SG_ 2364743166 Hvsp24Mdl27OprtnlStts 17209;
BA_ "SPN" SG_ 2364743166 Hvsp24Mdl28OprtnlStts 17210;
BA_ "SPN" SG_ 2364743166 Hvsp24Mdl29OprtnlStts 17211;
BA_ "SPN" SG_ 2364743166 Hvsp24Mdl30OprtnlStts 17212;
BA_ "SPN" SG_ 2364743166 Hvsp24Mdl31OprtnlStts 17213;
BA_ "SPN" SG_ 2364743166 Hvsp24Mdl32OprtnlStts 17214;
BA_ "SPN" SG_ 2364743422 Hvsp24ThrmlMngmntSstmSlInptPwr 17215;
BA_ "SPN" SG_ 2364743422 Hvsp24TMtSstHVtIptPw 17216;
BA_ "SPN" SG_ 2364743422 Hvsp24ThrmlMngmntSstmCmprssrSpd 17217;
BA_ "SPN" SG_ 2364743422 Hvsp24ThrmlMngmntSstmRltvHmdt 17218;
BA_ "SPN" SG_ 2364743422 Hvsp24ThrmlMngmntSstmHtrStts 17219;
BA_ "SPN" SG_ 2364743422 Hvsp24ThrmlMngmntSstmHvlStts 17220;
BA_ "SPN" SG_ 2364743422 Hvsp24ThrmlMngmntSstmMd 17221;
BA_ "SPN" SG_ 2364743422 Hvsp24ThrmlMngmntSstmClntLvl 17222;
BA_ "SPN" SG_ 2364743678 Hvsp24HghstCllVltgMdlNmr 17223;
BA_ "SPN" SG_ 2364743678 Hvsp24HghstCllVltgCllNmr 17224;
BA_ "SPN" SG_ 2364743678 Hvsp24LwstCllVltgMdlNmr 17225;
BA_ "SPN" SG_ 2364743678 Hvsp24LwstCllVltgCllNmr 17226;
BA_ "SPN" SG_ 2364743678 Hvesp24AverageCellVoltage 17227;
BA_ "SPN" SG_ 2364743934 Hvsp24HghstCllTmprtrMdlNmr 17228;
BA_ "SPN" SG_ 2364743934 Hvsp24HghstCllTmprtrCllNmr 17229;
BA_ "SPN" SG_ 2364743934 Hvsp24LwstCllTmprtrMdlNmr 17230;
BA_ "SPN" SG_ 2364743934 Hvsp24LwstCllTmprtrCllNmr 17231;
BA_ "SPN" SG_ 2364743934 Hvess24ThermalEventDetected 21311;
BA_ "SPN" SG_ 2364743934 Hvsp24Dt9EmdddIntgrtSpprt 23043;
BA_ "SPN" SG_ 2364743934 Hvesp24Data9Counter 23044;
BA_ "SPN" SG_ 2364743934 Hvesp24Data9Crc 23045;
BA_ "SPN" SG_ 2364744190 Hvsp24HghstCllSttOfChrgMdlNmr 17232;
BA_ "SPN" SG_ 2364744190 Hvsp24HghstCllSttOfChrgCllNmr 17233;
BA_ "SPN" SG_ 2364744190 Hvsp24LwstCllSttOfChrgMdlNmr 17234;
BA_ "SPN" SG_ 2364744190 Hvsp24LwstCllSttOfChrgCllNmr 17235;
BA_ "SPN" SG_ 2364744190 Hvsp24HghVltgBsAtvIsltnTstRslts 17236;
BA_ "SPN" SG_ 2364744190 Hvsp24HVtBsPssvIstTstRsts 17237;
BA_ "SPN" SG_ 2364744446 Hvsp24BsVltgNgtvTChsssGrndVltg 17238;
BA_ "SPN" SG_ 2364744446 Hvsp24VltgLvlNgtvTChsssGrndVltg 17239;
BA_ "SPN" SG_ 2364744446 Hvesp24ActualChargeRate 17240;
BA_ "SPN" SG_ 2364744702 Hvsp25DshrgPwrLmtDTSttOfChrg 17268;
BA_ "SPN" SG_ 2364744702 Hvsp25DshrgPwrLmtDTBttrTmprtr 17269;
BA_ "SPN" SG_ 2364744702 Hvsp25DsPwLtDTBttDstCdt 17270;
BA_ "SPN" SG_ 2364744702 Hvsp25DsPwLtDTBttOCVt 17271;
BA_ "SPN" SG_ 2364744702 Hvsp25DshrgPwrLmtDTBttrCrrnt 17272;
BA_ "SPN" SG_ 2364744702 Hvsp25DshrgPwrLmtDTAnUndfndCs 17273;
BA_ "SPN" SG_ 2364744702 Hvsp25ChrgPwrLmtDTSttOfChrg 17274;
BA_ "SPN" SG_ 2364744702 Hvsp25ChrgPwrLmtDTBttrTmprtr 17275;
BA_ "SPN" SG_ 2364744702 Hvsp25CPwLtDTBttDstCdt 17276;
BA_ "SPN" SG_ 2364744702 Hvsp25ChrgPwrLmtDTBttrOrCllVltg 17277;
BA_ "SPN" SG_ 2364744702 Hvsp25ChrgPwrLmtDTBttrCrrnt 17278;
BA_ "SPN" SG_ 2364744702 Hvsp25ChrgPwrLmtDTAnUndfndCs 17279;
BA_ "SPN" SG_ 2364744958 Hvesp25AvailableDischargePower 17280;
BA_ "SPN" SG_ 2364744958 Hvesp25AvailableChargePower 17281;
BA_ "SPN" SG_ 2364744958 Hvesp25VoltageLevel 17282;
BA_ "SPN" SG_ 2364744958 Hvesp25Current 17283;
BA_ "SPN" SG_ 2364745214 Hvesp25FastUpdateStateOfCharge 17284;
BA_ "SPN" SG_ 2364745214 Hvesp25HighestCellVoltage 17285;
BA_ "SPN" SG_ 2364745214 Hvesp25LowestCellVoltage 17286;
BA_ "SPN" SG_ 2364745214 Hvsp25CllVltgDffrntlStts 17287;
BA_ "SPN" SG_ 2364745470 Hvesp25HighestCellTemperature 17288;
BA_ "SPN" SG_ 2364745470 Hvesp25LowestCellTemperature 17289;
BA_ "SPN" SG_ 2364745470 Hvesp25AverageCellTemperature 17290;
BA_ "SPN" SG_ 2364745470 Hvsp25CllTmprtrDffrntlStts 17291;
BA_ "SPN" SG_ 2364745726 Hvesp25DischargeCapacity 17292;
BA_ "SPN" SG_ 2364745726 Hvesp25ChargeCapacity 17293;
BA_ "SPN" SG_ 2364745726 Hvesp25CellBalancingCount 17294;
BA_ "SPN" SG_ 2364745982 Hvesp25LowestCellStateOfCharge 17297;
BA_ "SPN" SG_ 2364745982 Hvesp25HighestCellStateOfCharge 17298;
BA_ "SPN" SG_ 2364745982 Hvsp25MxmmInstntnsDshrgCrrntLmt 17295;
BA_ "SPN" SG_ 2364745982 Hvsp25MxmmInstntnsChrgCrrntLmt 17296;
BA_ "SPN" SG_ 2364746238 Hvesp25BusVoltage 17299;
BA_ "SPN" SG_ 2364746238 Hvesp25IgnitionVoltage 17300;
BA_ "SPN" SG_ 2364746238 Hvesp25IntakeCoolantTemperature 17301;
BA_ "SPN" SG_ 2364746238 Hvesp25OutletCoolantTemperature 17302;
BA_ "SPN" SG_ 2364746238 Hvesp25ElectronicsTemperature 17303;
BA_ "SPN" SG_ 2364746238 Hvesp25Temperature 17304;
BA_ "SPN" SG_ 2364746494 Hvsp25HghVltgBsPstvCnttrStt 17305;
BA_ "SPN" SG_ 2364746494 Hvsp25HghVltgBsNgtvCnttrStt 17306;
BA_ "SPN" SG_ 2364746494 Hvsp25HghVltgBsDsnntFrwrnng 17307;
BA_ "SPN" SG_ 2364746494 Hvsp25HghVltgBsPrChrgRlStt 17308;
BA_ "SPN" SG_ 2364746494 Hvsp25CntrOfPkCnttrStt 17309;
BA_ "SPN" SG_ 2364746494 Hvsp25HghVltgBsAtvIsltnTstStts 17310;
BA_ "SPN" SG_ 2364746494 Hvsp25HghVltgBsPssvIsltnTstStts 17311;
BA_ "SPN" SG_ 2364746494 Hvesp25HvilStatus 17312;
BA_ "SPN" SG_ 2364746494 Hvesp25InertiaSwitchStatus 17313;
BA_ "SPN" SG_ 2364746494 Hvesp25StateOfChargeStatus 17314;
BA_ "SPN" SG_ 2364746494 Hvesp25CellBalanceStatus 17315;
BA_ "SPN" SG_ 2364746494 Hvesp25CellBalancingActive 17316;
BA_ "SPN" SG_ 2364746494 Hvesp25InternalChargerStatus 17317;
BA_ "SPN" SG_ 2364746494 Hvsp25HghVltgBsCnntnStts 17318;
BA_ "SPN" SG_ 2364746494 Hvesp25OperationalStatus 17319;
BA_ "SPN" SG_ 2364746494 Hvesp25Status1Counter 17320;
BA_ "SPN" SG_ 2364746494 Hvesp25Status1Crc 17321;
BA_ "SPN" SG_ 2364746750 Hvesp25DischargeEnergyCapacity 17322;
BA_ "SPN" SG_ 2364746750 Hvesp25ChargeEnergyCapacity 17323;
BA_ "SPN" SG_ 2364746750 Hvsp25MxmmChrgVltgLmt 17324;
